VERSION ""

NS_ :

BS_:

BU_: WPC2 RLPSU DPSU APSU PSB SHVU_RR vHS_B2 FCS EMCU SLB ARS RCM CGW_CCU vDummy_HS_B ATS RLHV SGU PFSU ALBCU DSAU SWRC SHVU_FR RCS RRPSU BLTN_CAM SCM DLBCU OHCL RWPC RRHV WPC HOD ASAU

BO_ 2244048387 RCU_03_20ms_3: 8 CGW_CCU
 SG_ RCU_AD3_SCC_TqIntrvntnVal : 0|8@1+ (0.390625,0) [0|0] "%" Vector__XXX
 SG_ RCU_AD3_TCS_TqFlag : 19|1@1+ (1,0) [0|0] "" Vector__XXX
 SG_ RCU_AD3_TCS_Sta : 20|4@1+ (1,0) [0|0] "" Vector__XXX
 SG_ RCU_AD3_VehAccelVal : 24|11@1+ (0.01,-10.23) [0|0] "m/s^2" Vector__XXX
 SG_ RCU_AD3_MSR_TqFlag : 35|1@1+ (1,0) [0|0] "" Vector__XXX
 SG_ RCU_AD3_LDM_Sta : 36|2@1+ (1,0) [0|0] "" Vector__XXX
 SG_ RCU_AD3_ECD_ActvSta : 38|2@1+ (1,0) [0|0] "" Vector__XXX
 SG_ RCU_AD3_MSR_FuncReq : 40|2@1+ (1,0) [0|0] "" Vector__XXX
 SG_ RCU_AD3_TCS_Req : 42|2@1+ (1,0) [0|0] "" Vector__XXX
 SG_ RCU_AD3_TCS_LmpSta : 44|2@1+ (1,0) [0|0] "" Vector__XXX
 SG_ RCU_AD3_SCC_TqReq : 46|2@1+ (1,0) [0|0] "" Vector__XXX
 SG_ RCU_AD3_StdStillVal : 48|2@1+ (1,0) [0|0] "" Vector__XXX
 SG_ RCU_AD3_SCC_ReqLimSta : 50|2@1+ (1,0) [0|0] "" Vector__XXX
 SG_ RCU_AD3_SCC_OptTyp : 52|2@1+ (1,0) [0|0] "" Vector__XXX
 SG_ RCU_AD3_SCC_EnblReq : 54|2@1+ (1,0) [0|0] "" Vector__XXX
 SG_ RCU_AD3_FCA_EquipSta : 56|2@1+ (1,0) [0|0] "" Vector__XXX
 SG_ RCU_AD3_FCA_ActvSta : 58|2@1+ (1,0) [0|0] "" Vector__XXX
 SG_ RCU_AD3_DclEnblReq : 60|2@1+ (1,0) [0|0] "" Vector__XXX
 SG_ RCU_AD3_DBS_ActvSta : 62|2@1+ (1,0) [0|0] "" Vector__XXX
 SG_ RCU_AD3_AccelBasisVal : 8|11@1+ (0.01,-10.23) [0|0] "m/s^2" Vector__XXX

BO_ 2244048386 RCU_03_20ms_2: 8 CGW_CCU
 SG_ RCU_AD3_Wss2FlFltSta : 0|2@1+ (1,0) [0|0] "" Vector__XXX
 SG_ RCU_AD3_DiagSta : 10|2@1+ (1,0) [0|0] "" Vector__XXX
 SG_ RCU_AD3_operation : 12|2@1+ (1,0) [0|0] "" Vector__XXX
 SG_ RCU_AD3_PrsrValVldSta : 14|2@1+ (1,0) [0|0] "" Vector__XXX
 SG_ RCU_AD3_PrsrVal : 16|16@1- (0.01,-30) [0|0] "Bar" Vector__XXX
 SG_ RCU_AD3_Wss2FrFltSta : 2|2@1+ (1,0) [0|0] "" Vector__XXX
 SG_ RCU_AD3_ABS_DfctvSta : 32|2@1+ (1,0) [0|0] "" Vector__XXX
 SG_ RCU_AD3_ABS_ActvSta : 34|2@1+ (1,0) [0|0] "" Vector__XXX
 SG_ RCU_AD3_BBC_DfctvSta : 36|2@1+ (1,0) [0|0] "" Vector__XXX
 SG_ RCU_AD3_BBC_ActvSta : 38|2@1+ (1,0) [0|0] "" Vector__XXX
 SG_ RCU_AD3_Wss2RlFltSta : 4|2@1+ (1,0) [0|0] "" Vector__XXX
 SG_ RCU_AD3_BrkLtActSta : 40|2@1+ (1,0) [0|0] "" Vector__XXX
 SG_ RCU_AD3_DrvOvrdSta : 42|2@1+ (1,0) [0|0] "" Vector__XXX
 SG_ RCU_AD3_PrkBrkActvSta : 44|2@1+ (1,0) [0|0] "" Vector__XXX
 SG_ RCU_AD3_FCA_AvlblSta : 46|2@1+ (1,0) [0|0] "" Vector__XXX
 SG_ RCU_AD3_MSR_TqIntrvntnVal : 48|8@1+ (0.390625,0) [0|0] "%" Vector__XXX
 SG_ RCU_AD3_TCS_TqIntrvntnVal : 56|8@1+ (0.390625,0) [0|0] "%" Vector__XXX
 SG_ RCU_AD3_Wss2RrFltSta : 6|2@1+ (1,0) [0|0] "" Vector__XXX
 SG_ RCU_AD3_SrvLmpDis : 8|2@1+ (1,0) [0|0] "" Vector__XXX

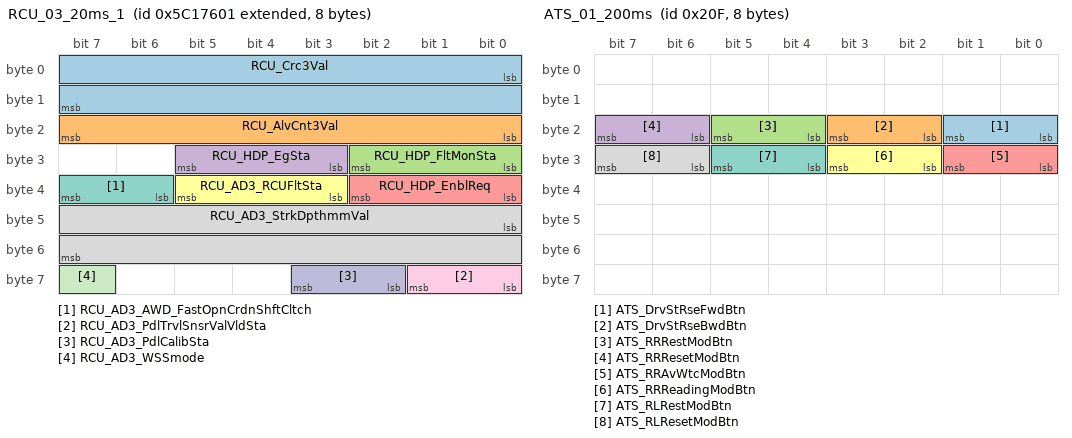
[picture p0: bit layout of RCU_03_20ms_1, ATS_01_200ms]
BO_ 2244048385 RCU_03_20ms_1: 8 CGW_CCU
 SG_ RCU_Crc3Val : 0|16@1+ (1,0) [0|0] "" Vector__XXX
 SG_ RCU_AlvCnt3Val : 16|8@1+ (1,0) [0|0] "" Vector__XXX
 SG_ RCU_HDP_FltMonSta : 24|3@1+ (1,0) [0|0] "" Vector__XXX
 SG_ RCU_HDP_EgSta : 27|3@1+ (1,0) [0|0] ""  PSB
 SG_ RCU_HDP_EnblReq : 32|3@1+ (1,0) [0|0] "" Vector__XXX
 SG_ RCU_AD3_RCUFltSta : 35|3@1+ (1,0) [0|0] "" Vector__XXX
 SG_ RCU_AD3_AWD_FastOpnCrdnShftCltch : 38|2@1+ (1,0) [0|0] "" Vector__XXX
 SG_ RCU_AD3_StrkDpthmmVal : 40|16@1- (0.1,-40) [0|0] "mm" Vector__XXX
 SG_ RCU_AD3_PdlTrvlSnsrValVldSta : 56|2@1+ (1,0) [0|0] "" Vector__XXX
 SG_ RCU_AD3_PdlCalibSta : 58|2@1+ (1,0) [0|0] "" Vector__XXX
 SG_ RCU_AD3_WSSmode : 63|1@1+ (1,0) [0|0] "" Vector__XXX

BO_ 527 ATS_01_200ms: 8 ATS
 SG_ ATS_DrvStRseFwdBtn : 16|2@1+ (1,0) [0|0] "" Vector__XXX
 SG_ ATS_DrvStRseBwdBtn : 18|2@1+ (1,0) [0|0] "" Vector__XXX
 SG_ ATS_RRRestModBtn : 20|2@1+ (1,0) [0|0] "" Vector__XXX
 SG_ ATS_RRResetModBtn : 22|2@1+ (1,0) [0|0] "" Vector__XXX
 SG_ ATS_RRAvWtcModBtn : 24|2@1+ (1,0) [0|0] "" Vector__XXX
 SG_ ATS_RRReadingModBtn : 26|2@1+ (1,0) [0|0] "" Vector__XXX
 SG_ ATS_RLRestModBtn : 28|2@1+ (1,0) [0|0] "" Vector__XXX
 SG_ ATS_RLResetModBtn : 30|2@1+ (1,0) [0|0] "" Vector__XXX

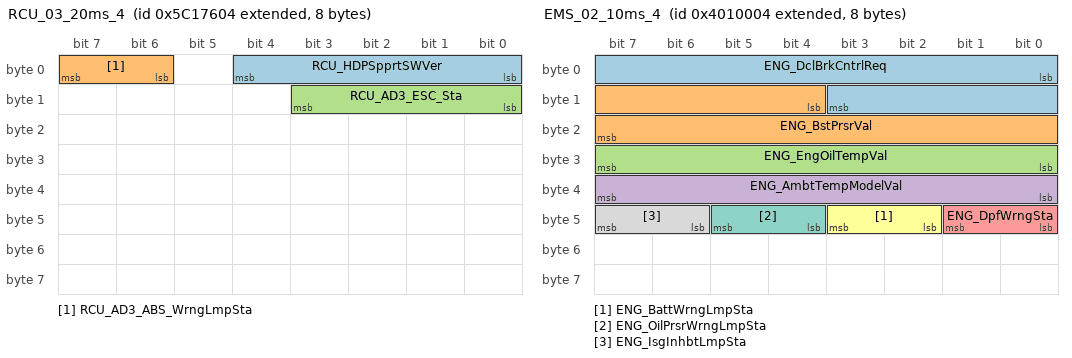
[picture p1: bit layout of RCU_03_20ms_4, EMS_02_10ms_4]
BO_ 2244048388 RCU_03_20ms_4: 8 CGW_CCU
 SG_ RCU_HDPSpprtSWVer : 0|5@1+ (1,0) [0|0] "" Vector__XXX
 SG_ RCU_AD3_ABS_WrngLmpSta : 6|2@1+ (1,0) [0|0] "" Vector__XXX
 SG_ RCU_AD3_ESC_Sta : 8|4@1+ (1,0) [0|0] "" Vector__XXX

BO_ 1616 MKBD_HU_E_01: 8 CGW_CCU
 SG_ MKBD_IllumiState : 48|2@1+ (1,0) [0|0] "" Vector__XXX
 SG_ MKBD_SeatKeySet : 50|2@1+ (1,0) [0|0] ""  APSU,SHVU_FR,DPSU

BO_ 543 ATS_02_200ms: 8 ATS
 SG_ ATS_AstStSldFwdBtn : 16|2@1+ (1,0) [0|0] "" Vector__XXX
 SG_ ATS_AstStSldBwdBtn : 18|2@1+ (1,0) [0|0] "" Vector__XXX
 SG_ ATS_AstStRclFwdBtn : 20|2@1+ (1,0) [0|0] "" Vector__XXX
 SG_ ATS_AstStRclBwdBtn : 22|2@1+ (1,0) [0|0] "" Vector__XXX
 SG_ ATS_AstStHgtUpBtn : 28|2@1+ (1,0) [0|0] "" Vector__XXX
 SG_ ATS_AstStHgtDnBtn : 30|2@1+ (1,0) [0|0] "" Vector__XXX
 SG_ ATS_AstStHRestUpBtn : 40|2@1+ (1,0) [0|0] "" Vector__XXX
 SG_ ATS_AstStHRestDnBtn : 42|2@1+ (1,0) [0|0] "" Vector__XXX
 SG_ ATS_AstStHRestFwdBtn : 44|2@1+ (1,0) [0|0] "" Vector__XXX
 SG_ ATS_AstStHRestBwdBtn : 46|2@1+ (1,0) [0|0] "" Vector__XXX
 SG_ ATS_AstStHRestFldBtn : 48|2@1+ (1,0) [0|0] "" Vector__XXX
 SG_ ATS_AstStHRestUnFldBtn : 50|2@1+ (1,0) [0|0] "" Vector__XXX
 SG_ ATS_AstStRseFwdBtn : 52|2@1+ (1,0) [0|0] "" Vector__XXX
 SG_ ATS_AstStRseBwdBtn : 54|2@1+ (1,0) [0|0] "" Vector__XXX
 SG_ ATS_AstStFRestFldBtn : 56|2@1+ (1,0) [0|0] "" Vector__XXX
 SG_ ATS_AstStFRestUnFldBtn : 58|2@1+ (1,0) [0|0] "" Vector__XXX
 SG_ ATS_AstTltUpBtn : 60|2@1+ (1,0) [0|0] "" Vector__XXX
 SG_ ATS_AstTltDnBtn : 62|2@1+ (1,0) [0|0] "" Vector__XXX

BO_ 2214658052 EMS_02_10ms_4: 8 CGW_CCU
 SG_ ENG_DclBrkCntrlReq : 0|12@1+ (0.001,-4.094) [0|0] "m/s^2" Vector__XXX
 SG_ ENG_BstPrsrVal : 12|12@1+ (1.322,0) [0|0] "hPa" Vector__XXX
 SG_ ENG_EngOilTempVal : 24|8@1+ (0.75,-40) [0|0] "¡É" Vector__XXX
 SG_ ENG_AmbtTempModelVal : 32|8@1+ (0.5,-41) [0|0] "¡É" Vector__XXX
 SG_ ENG_DpfWrngSta : 40|2@1+ (1,0) [0|0] "" Vector__XXX
 SG_ ENG_BattWrngLmpSta : 42|2@1+ (1,0) [0|0] "" Vector__XXX
 SG_ ENG_OilPrsrWrngLmpSta : 44|2@1+ (1,0) [0|0] "" Vector__XXX
 SG_ ENG_IsgInhbtLmpSta : 46|2@1+ (1,0) [0|0] ""  FCS

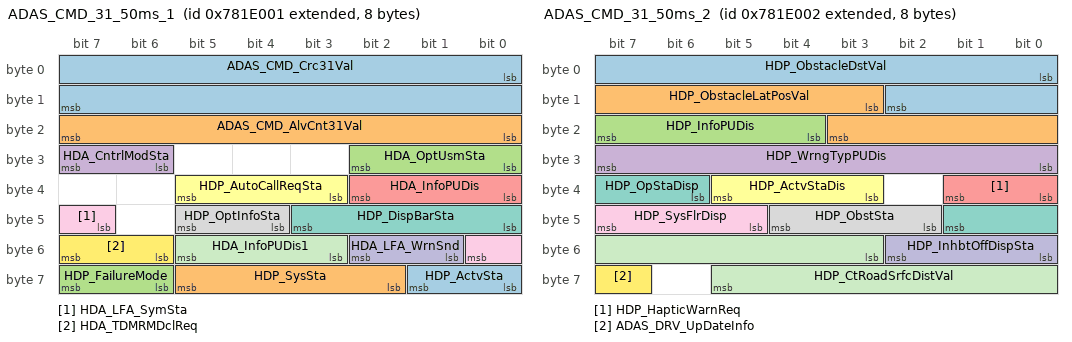
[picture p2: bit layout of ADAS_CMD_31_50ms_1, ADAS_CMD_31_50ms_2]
BO_ 2273435649 ADAS_CMD_31_50ms_1: 8 CGW_CCU
 SG_ ADAS_CMD_Crc31Val : 0|16@1+ (1,0) [0|0] "" Vector__XXX
 SG_ ADAS_CMD_AlvCnt31Val : 16|8@1+ (1,0) [0|0] "" Vector__XXX
 SG_ HDA_OptUsmSta : 24|3@1+ (1,0) [0|0] "" Vector__XXX
 SG_ HDA_CntrlModSta : 30|2@1+ (1,0) [0|0] "" Vector__XXX
 SG_ HDA_InfoPUDis : 32|3@1+ (1,0) [0|0] "" Vector__XXX
 SG_ HDP_AutoCallReqSta : 35|3@1+ (1,0) [0|0] "" Vector__XXX
 SG_ HDP_DispBarSta : 40|4@1+ (1,0) [0|0] "" Vector__XXX
 SG_ HDP_OptInfoSta : 44|2@1+ (1,0) [0|0] "" Vector__XXX
 SG_ HDA_LFA_SymSta : 47|2@1+ (1,0) [0|0] "" Vector__XXX
 SG_ HDA_LFA_WrnSnd : 49|2@1+ (1,0) [0|0] "" Vector__XXX
 SG_ HDA_InfoPUDis1 : 51|3@1+ (1,0) [0|0] "" Vector__XXX
 SG_ HDA_TDMRMDclReq : 54|2@1+ (1,0) [0|0] "" Vector__XXX
 SG_ HDP_ActvSta : 56|2@1+ (1,0) [0|0] "" Vector__XXX
 SG_ HDP_SysSta : 58|4@1+ (1,0) [0|0] ""  HOD
 SG_ HDP_FailureMode : 62|2@1+ (1,0) [0|0] "" Vector__XXX

BO_ 2273435650 ADAS_CMD_31_50ms_2: 8 CGW_CCU
 SG_ HDP_ObstacleDstVal : 0|11@1+ (0.1,0) [0|0] "m" Vector__XXX
 SG_ HDP_ObstacleLatPosVal : 11|9@1+ (0.1,-20) [0|0] "m" Vector__XXX
 SG_ HDP_InfoPUDis : 20|4@1+ (1,0) [0|0] "" Vector__XXX
 SG_ HDP_WrngTypPUDis : 24|8@1+ (1,0) [0|0] "" Vector__XXX
 SG_ HDP_HapticWarnReq : 32|2@1+ (1,0) [0|0] ""  PSB
 SG_ HDP_ActvStaDis : 35|3@1+ (1,0) [0|0] "" Vector__XXX
 SG_ HDP_OpStaDisp : 38|4@1+ (1,0) [0|0] "" Vector__XXX
 SG_ HDP_ObstSta : 42|3@1+ (1,0) [0|0] "" Vector__XXX
 SG_ HDP_SysFlrDisp : 45|3@1+ (1,0) [0|0] "" Vector__XXX
 SG_ HDP_InhbtOffDispSta : 48|3@1+ (1,0) [0|0] "" Vector__XXX
 SG_ HDP_CtRoadSrfcDistVal : 51|11@1+ (1,0) [0|0] "" Vector__XXX
 SG_ ADAS_DRV_UpDateInfo : 63|1@1+ (1,0) [0|0] "" Vector__XXX

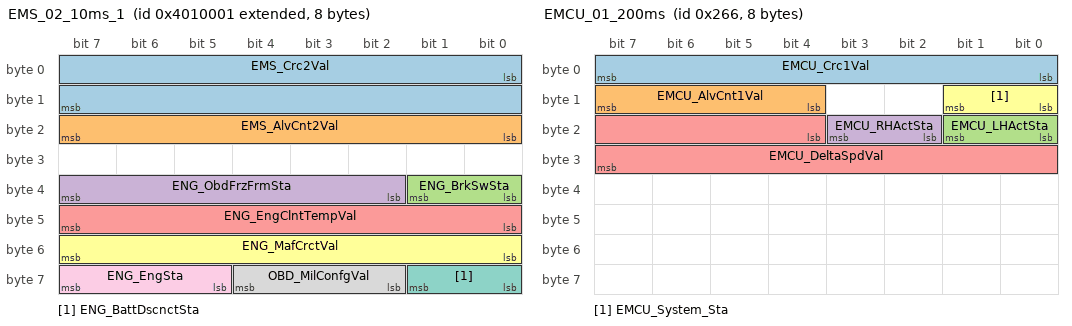
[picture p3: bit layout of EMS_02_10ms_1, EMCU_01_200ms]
BO_ 2214658049 EMS_02_10ms_1: 8 CGW_CCU
 SG_ EMS_Crc2Val : 0|16@1+ (1,0) [0|0] "" Vector__XXX
 SG_ EMS_AlvCnt2Val : 16|8@1+ (1,0) [0|0] "" Vector__XXX
 SG_ ENG_BrkSwSta : 32|2@1+ (1,0) [0|0] ""  BLTN_CAM
 SG_ ENG_ObdFrzFrmSta : 34|6@1+ (1,0) [0|0] "" Vector__XXX
 SG_ ENG_EngClntTempVal : 40|8@1+ (0.75,-48) [0|0] "¡É" Vector__XXX
 SG_ ENG_MafCrctVal : 48|8@1+ (0.00781,0) [0|0] "" Vector__XXX
 SG_ ENG_BattDscnctSta : 56|2@1+ (1,0) [0|0] "" Vector__XXX
 SG_ OBD_MilConfgVal : 58|3@1+ (1,0) [0|0] "" Vector__XXX
 SG_ ENG_EngSta : 61|3@1+ (1,0) [0|0] ""  SCM,WPC,RWPC,SWRC,APSU,RLHV,RRHV,SHVU_FR,SHVU_RR,DPSU,DLBCU,PFSU,RRPSU,RLPSU,HOD,RCM,BLTN_CAM,EMCU,WPC2

BO_ 614 EMCU_01_200ms: 8 EMCU
 SG_ EMCU_Crc1Val : 0|8@1+ (1,0) [0|0] "" Vector__XXX
 SG_ EMCU_AlvCnt1Val : 12|4@1+ (1,0) [0|0] "" Vector__XXX
 SG_ EMCU_LHActSta : 16|2@1+ (1,0) [0|0] "" Vector__XXX
 SG_ EMCU_RHActSta : 18|2@1+ (1,0) [0|0] "" Vector__XXX
 SG_ EMCU_DeltaSpdVal : 20|12@1+ (0.01,0) [0|0] "" Vector__XXX
 SG_ EMCU_System_Sta : 8|2@1+ (1,0) [0|0] "" Vector__XXX

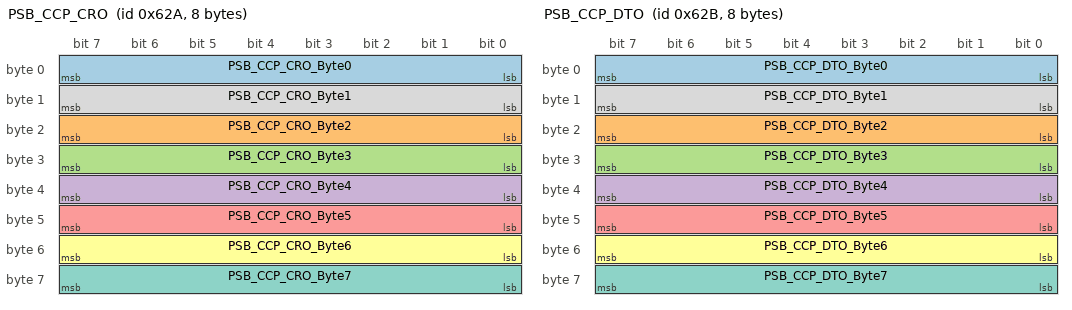
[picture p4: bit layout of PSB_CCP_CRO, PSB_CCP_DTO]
BO_ 1578 PSB_CCP_CRO: 8 CGW_CCU
 SG_ PSB_CCP_CRO_Byte0 : 0|8@1+ (1,0) [0|0] ""  PSB
 SG_ PSB_CCP_CRO_Byte2 : 16|8@1+ (1,0) [0|0] ""  PSB
 SG_ PSB_CCP_CRO_Byte3 : 24|8@1+ (1,0) [0|0] ""  PSB
 SG_ PSB_CCP_CRO_Byte4 : 32|8@1+ (1,0) [0|0] ""  PSB
 SG_ PSB_CCP_CRO_Byte5 : 40|8@1+ (1,0) [0|0] ""  PSB
 SG_ PSB_CCP_CRO_Byte6 : 48|8@1+ (1,0) [0|0] ""  PSB
 SG_ PSB_CCP_CRO_Byte7 : 56|8@1+ (1,0) [0|0] ""  PSB
 SG_ PSB_CCP_CRO_Byte1 : 8|8@1+ (1,0) [0|0] ""  PSB

BO_ 1579 PSB_CCP_DTO: 8 PSB
 SG_ PSB_CCP_DTO_Byte0 : 0|8@1+ (1,0) [0|0] ""  CGW_CCU
 SG_ PSB_CCP_DTO_Byte2 : 16|8@1+ (1,0) [0|0] ""  CGW_CCU
 SG_ PSB_CCP_DTO_Byte3 : 24|8@1+ (1,0) [0|0] ""  CGW_CCU
 SG_ PSB_CCP_DTO_Byte4 : 32|8@1+ (1,0) [0|0] ""  CGW_CCU
 SG_ PSB_CCP_DTO_Byte5 : 40|8@1+ (1,0) [0|0] ""  CGW_CCU
 SG_ PSB_CCP_DTO_Byte6 : 48|8@1+ (1,0) [0|0] ""  CGW_CCU
 SG_ PSB_CCP_DTO_Byte7 : 56|8@1+ (1,0) [0|0] ""  CGW_CCU
 SG_ PSB_CCP_DTO_Byte1 : 8|8@1+ (1,0) [0|0] ""  CGW_CCU

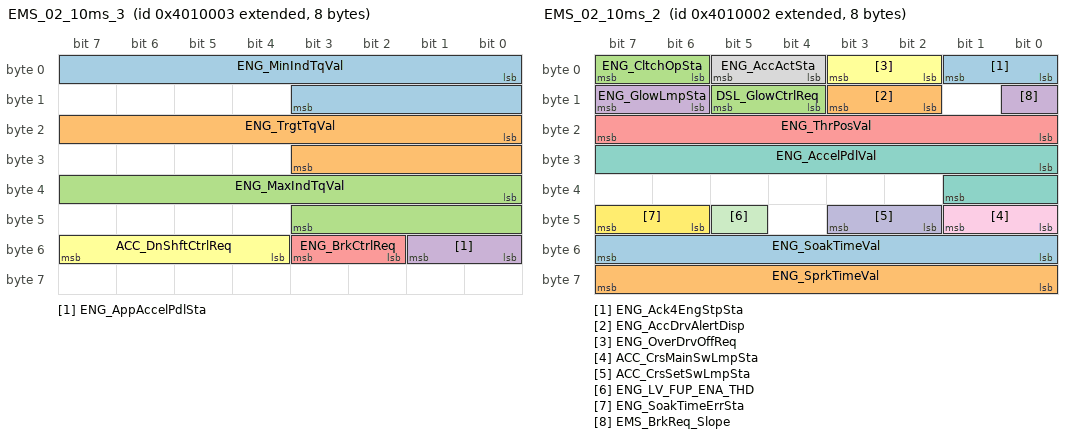
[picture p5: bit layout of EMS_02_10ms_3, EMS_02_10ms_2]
BO_ 2214658051 EMS_02_10ms_3: 8 CGW_CCU
 SG_ ENG_MinIndTqVal : 0|12@1- (1,0) [0|0] "Nm" Vector__XXX
 SG_ ENG_TrgtTqVal : 16|12@1- (1,0) [0|0] "Nm" Vector__XXX
 SG_ ENG_MaxIndTqVal : 32|12@1- (1,0) [0|0] "Nm" Vector__XXX
 SG_ ENG_AppAccelPdlSta : 48|2@1+ (1,0) [0|0] "" Vector__XXX
 SG_ ENG_BrkCtrlReq : 50|2@1+ (1,0) [0|0] "" Vector__XXX
 SG_ ACC_DnShftCtrlReq : 52|4@1+ (1,0) [0|0] "" Vector__XXX

BO_ 2214658050 EMS_02_10ms_2: 8 CGW_CCU
 SG_ ENG_Ack4EngStpSta : 0|2@1+ (1,0) [0|0] "" Vector__XXX
 SG_ ENG_AccDrvAlertDisp : 10|2@1+ (1,0) [0|0] "" Vector__XXX
 SG_ DSL_GlowCtrlReq : 12|2@1+ (1,0) [0|0] "" Vector__XXX
 SG_ ENG_GlowLmpSta : 14|2@1+ (1,0) [0|0] "" Vector__XXX
 SG_ ENG_ThrPosVal : 16|8@1+ (0.4694836,-15.0234742) [0|0] "%" Vector__XXX
 SG_ ENG_OverDrvOffReq : 2|2@1+ (1,0) [0|0] "" Vector__XXX
 SG_ ENG_AccelPdlVal : 24|10@1+ (0.09784,0) [0|0] "%"  BLTN_CAM,EMCU
 SG_ ENG_AccActSta : 4|2@1+ (1,0) [0|0] "" Vector__XXX
 SG_ ACC_CrsMainSwLmpSta : 40|2@1+ (1,0) [0|0] "" Vector__XXX
 SG_ ACC_CrsSetSwLmpSta : 42|2@1+ (1,0) [0|0] "" Vector__XXX
 SG_ ENG_LV_FUP_ENA_THD : 45|1@1+ (1,0) [0|0] "" Vector__XXX
 SG_ ENG_SoakTimeErrSta : 46|2@1+ (1,0) [0|0] "" Vector__XXX
 SG_ ENG_SoakTimeVal : 48|8@1+ (1,0) [0|0] "Min" Vector__XXX
 SG_ ENG_SprkTimeVal : 56|8@1+ (0.375,-35.625) [0|0] "¢ª" Vector__XXX
 SG_ ENG_CltchOpSta : 6|2@1+ (1,0) [0|0] "" Vector__XXX
 SG_ EMS_BrkReq_Slope : 8|1@1+ (1,0) [0|0] "" Vector__XXX

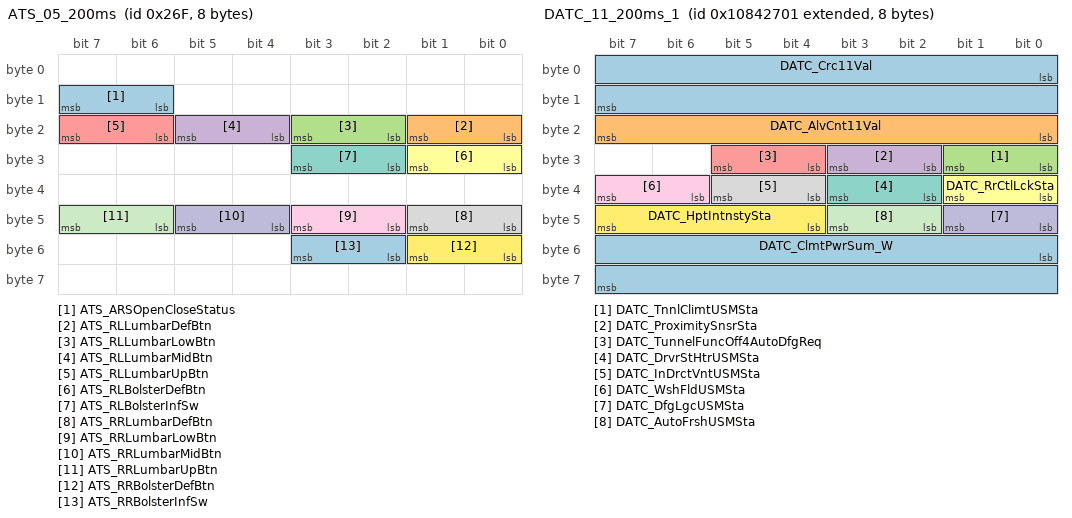
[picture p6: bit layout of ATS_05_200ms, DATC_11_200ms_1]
BO_ 623 ATS_05_200ms: 8 ATS
 SG_ ATS_ARSOpenCloseStatus : 14|2@1+ (1,0) [0|0] "" Vector__XXX
 SG_ ATS_RLLumbarDefBtn : 16|2@1+ (1,0) [0|0] "" Vector__XXX
 SG_ ATS_RLLumbarLowBtn : 18|2@1+ (1,0) [0|0] "" Vector__XXX
 SG_ ATS_RLLumbarMidBtn : 20|2@1+ (1,0) [0|0] "" Vector__XXX
 SG_ ATS_RLLumbarUpBtn : 22|2@1+ (1,0) [0|0] "" Vector__XXX
 SG_ ATS_RLBolsterDefBtn : 24|2@1+ (1,0) [0|0] "" Vector__XXX
 SG_ ATS_RLBolsterInfSw : 26|2@1+ (1,0) [0|0] "" Vector__XXX
 SG_ ATS_RRLumbarDefBtn : 40|2@1+ (1,0) [0|0] "" Vector__XXX
 SG_ ATS_RRLumbarLowBtn : 42|2@1+ (1,0) [0|0] "" Vector__XXX
 SG_ ATS_RRLumbarMidBtn : 44|2@1+ (1,0) [0|0] "" Vector__XXX
 SG_ ATS_RRLumbarUpBtn : 46|2@1+ (1,0) [0|0] "" Vector__XXX
 SG_ ATS_RRBolsterDefBtn : 48|2@1+ (1,0) [0|0] "" Vector__XXX
 SG_ ATS_RRBolsterInfSw : 50|2@1+ (1,0) [0|0] "" Vector__XXX

BO_ 639 ATS_04_00ms: 8 ATS
 SG_ ATS_RRSeatHeaterSW : 0|2@1+ (1,0) [0|0] ""  RRHV,SHVU_RR
 SG_ ATS_RLSeatHeaterUpSW : 10|2@1+ (1,0) [0|0] ""  RLHV,SHVU_RR
 SG_ ATS_RRSeatVentDownSW : 12|2@1+ (1,0) [0|0] ""  RRHV,SHVU_RR
 SG_ ATS_RLSeatVentDownSW : 14|2@1+ (1,0) [0|0] ""  RLHV,SHVU_RR
 SG_ ATS_RLMemoryRestBtn : 16|2@1+ (1,0) [0|0] "" Vector__XXX
 SG_ ATS_RLMemoryReturnBtn : 18|2@1+ (1,0) [0|0] "" Vector__XXX
 SG_ ATS_RLSeatHeaterSW : 2|2@1+ (1,0) [0|0] ""  RLHV,SHVU_RR
 SG_ ATS_RRMemoryRestBtn : 20|2@1+ (1,0) [0|0] "" Vector__XXX
 SG_ ATS_RRMemoryReturnBtn : 22|2@1+ (1,0) [0|0] "" Vector__XXX
 SG_ ATS_RRMemoryAvWtcBtn : 24|2@1+ (1,0) [0|0] "" Vector__XXX
 SG_ ATS_RRMemoryReadingBtn : 26|2@1+ (1,0) [0|0] "" Vector__XXX
 SG_ ATS_RRRestModBtnSTD : 32|2@1+ (1,0) [0|0] "" Vector__XXX
 SG_ ATS_RRResetModBtnSTD : 34|2@1+ (1,0) [0|0] "" Vector__XXX
 SG_ ATS_RRAvWtcModBtnSTD : 36|2@1+ (1,0) [0|0] "" Vector__XXX
 SG_ ATS_RRReadingModBtnSTD : 38|2@1+ (1,0) [0|0] "" Vector__XXX
 SG_ ATS_RRSeatVentSW : 4|2@1+ (1,0) [0|0] ""  RRHV,SHVU_RR
 SG_ ATS_RLRestModBtnSTD : 40|2@1+ (1,0) [0|0] "" Vector__XXX
 SG_ ATS_RLResetModBtnSTD : 42|2@1+ (1,0) [0|0] "" Vector__XXX
 SG_ ATS_RRModestateStopBtn : 44|2@1+ (1,0) [0|0] "" Vector__XXX
 SG_ ATS_RLModestateStopBtn : 46|2@1+ (1,0) [0|0] "" Vector__XXX
 SG_ ATS_RLResetRestBtn : 48|2@1+ (1,0) [0|0] "" Vector__XXX
 SG_ ATS_RLResetReturnBtn : 50|2@1+ (1,0) [0|0] "" Vector__XXX
 SG_ ATS_RRResetRestBtn : 52|2@1+ (1,0) [0|0] "" Vector__XXX
 SG_ ATS_RRResetReturnBtn : 54|2@1+ (1,0) [0|0] "" Vector__XXX
 SG_ ATS_RRResetAvWtcBtn : 56|2@1+ (1,0) [0|0] "" Vector__XXX
 SG_ ATS_RRResetReadingBtn : 58|2@1+ (1,0) [0|0] "" Vector__XXX
 SG_ ATS_RLSeatVentSW : 6|2@1+ (1,0) [0|0] ""  RLHV,SHVU_RR
 SG_ ATS_RRSeatHeaterUpSW : 8|2@1+ (1,0) [0|0] ""  RRHV,SHVU_RR

BO_ 1584 HU_AMP_E_01: 8 CGW_CCU
 SG_ AMP_NaviWarnSound : 0|2@1+ (1,0) [0|0] "" Vector__XXX
 SG_ AMP_Beep1Mode : 14|2@1+ (1,0) [0|0] ""  ATS
 SG_ AMP_MasterBeepVolumeStep : 16|3@1+ (1,0) [0|0] "" Vector__XXX
 SG_ AMP_RrTTSSound : 2|2@1+ (1,0) [0|0] "" Vector__XXX
 SG_ AMP_ASDMode : 21|3@1+ (1,0) [0|0] "" Vector__XXX
 SG_ AMP_ANCMode : 25|2@1+ (1,0) [0|0] "" Vector__XXX
 SG_ AMP_VirtualVenueMode : 32|3@1+ (1,0) [0|0] "" Vector__XXX
 SG_ AMP_QLIMode : 35|3@1+ (1,0) [0|0] "" Vector__XXX
 SG_ AMP_DriverMode : 38|2@1+ (1,0) [0|0] "" Vector__XXX
 SG_ AMP_NaviSound : 4|2@1+ (1,0) [0|0] "" Vector__XXX
 SG_ AMP_ETCSSound : 42|2@1+ (1,0) [0|0] "" Vector__XXX
 SG_ AMP_VoiceGuideTTS : 44|2@1+ (1,0) [0|0] "" Vector__XXX
 SG_ AMP_Beep1KBDMode : 46|2@1+ (1,0) [0|0] "" Vector__XXX
 SG_ AMP_ETCSVolumeStep : 48|8@1+ (1,0) [0|0] "" Vector__XXX
 SG_ AMP_NaviWarnVolumeStep : 56|8@1+ (1,0) [0|0] "" Vector__XXX
 SG_ AMP_TTSSound : 6|2@1+ (1,0) [0|0] "" Vector__XXX
 SG_ AMP_SDVCStep : 9|3@1+ (1,0) [0|0] "" Vector__XXX

BO_ 577 HU_APSU_PE_02: 8 CGW_CCU
 SG_ C_AstBolsterInfSw_HU : 0|2@1+ (1,0) [0|0] ""  ASAU,ALBCU
 SG_ C_RLHrestUpSw_HU : 14|2@1+ (1,0) [0|0] ""  APSU,RLPSU
 SG_ C_RLHrestDnSw_HU : 16|2@1+ (1,0) [0|0] ""  APSU,RLPSU
 SG_ C_RLHrestFwdSw_HU : 18|2@1+ (1,0) [0|0] ""  APSU,RLPSU
 SG_ C_AstBolsterDefSw_HU : 2|2@1+ (1,0) [0|0] ""  ASAU,ALBCU
 SG_ C_RLHrestBwdSw_HU : 20|2@1+ (1,0) [0|0] ""  APSU,RLPSU
 SG_ C_RLLumbarUpSw_HU : 22|2@1+ (1,0) [0|0] ""  RLPSU
 SG_ C_RLLumbarMidSw_HU : 24|2@1+ (1,0) [0|0] ""  RLPSU
 SG_ C_RLLumbarLowSw_HU : 26|2@1+ (1,0) [0|0] ""  RLPSU
 SG_ C_RLLumbarDefSw_HU : 28|2@1+ (1,0) [0|0] ""  RLPSU
 SG_ C_RLBolsterInfSw_HU : 30|2@1+ (1,0) [0|0] ""  RLPSU
 SG_ C_RLBolsterDefSw_HU : 32|2@1+ (1,0) [0|0] ""  RLPSU
 SG_ C_AstHrestUpSw_HU : 36|2@1+ (1,0) [0|0] ""  APSU
 SG_ C_AstHrestDnSw_HU : 38|2@1+ (1,0) [0|0] ""  APSU
 SG_ C_AstFootrestFldSw_HU : 4|2@1+ (1,0) [0|0] ""  APSU
 SG_ C_AstHrestFwdSw_HU : 46|2@1+ (1,0) [0|0] ""  APSU
 SG_ C_AstHrestBwdSw_HU : 54|2@1+ (1,0) [0|0] ""  APSU
 SG_ C_AstFootrestUnFldSw_HU : 6|2@1+ (1,0) [0|0] ""  APSU

BO_ 578 HU_APSU_PE_03: 8 CGW_CCU
 SG_ C_RRLegSupFwdSw_HU : 0|2@1+ (1,0) [0|0] ""  APSU,RRPSU
 SG_ C_RRHrestDnSw_HU : 10|2@1+ (1,0) [0|0] ""  APSU,RRPSU
 SG_ C_RRHrestFwdSw_HU : 12|2@1+ (1,0) [0|0] ""  APSU,RRPSU
 SG_ C_RRHrestBwdSw_HU : 14|2@1+ (1,0) [0|0] ""  APSU,RRPSU
 SG_ C_RRLumbarUpSw_HU : 16|2@1+ (1,0) [0|0] ""  APSU,RRPSU
 SG_ C_RRLumbarMidSw_HU : 18|2@1+ (1,0) [0|0] ""  APSU,RRPSU
 SG_ C_RRLegSupBwdSw_HU : 2|2@1+ (1,0) [0|0] ""  APSU,RRPSU
 SG_ C_RRLumbarLowSw_HU : 20|2@1+ (1,0) [0|0] ""  APSU,RRPSU
 SG_ C_RRLumbarDefSw_HU : 22|2@1+ (1,0) [0|0] ""  APSU,RRPSU
 SG_ C_RRBolsterInfSw_HU : 24|2@1+ (1,0) [0|0] ""  APSU,RRPSU
 SG_ C_RRLegSupUpSw_HU : 4|2@1+ (1,0) [0|0] ""  APSU,RRPSU
 SG_ C_RROneTchNValueSet : 40|3@1+ (1,0) [0|0] ""  APSU,RRPSU,ATS
 SG_ C_RLOneTchNValueSet : 43|3@1+ (1,0) [0|0] ""  APSU,RRPSU,RLPSU,ATS
 SG_ C_RRBolsterDefSw_HU : 46|2@1+ (1,0) [0|0] ""  APSU,RRPSU
 SG_ C_AstRlxTiltUpSw_HU : 50|2@1+ (1,0) [0|0] ""  APSU
 SG_ C_AstRlxTiltDnSw_HU : 52|2@1+ (1,0) [0|0] ""  APSU
 SG_ C_RLRSEUpSw_HU : 54|2@1+ (1,0) [0|0] ""  APSU,RLPSU
 SG_ C_RLRSEDnSw_HU : 56|2@1+ (1,0) [0|0] ""  APSU,RLPSU
 SG_ C_RRRSEUpSw_HU : 58|2@1+ (1,0) [0|0] ""  APSU,RRPSU
 SG_ C_RRLegSupDnSw_HU : 6|2@1+ (1,0) [0|0] ""  APSU,RRPSU
 SG_ C_RRRSEDnSw_HU : 60|2@1+ (1,0) [0|0] ""  APSU,RRPSU
 SG_ C_RRHrestUpSw_HU : 8|2@1+ (1,0) [0|0] ""  APSU,RRPSU

BO_ 2424579841 DATC_11_200ms_1: 8 CGW_CCU
 SG_ DATC_Crc11Val : 0|16@1+ (1,0) [0|0] "" Vector__XXX
 SG_ DATC_AlvCnt11Val : 16|8@1+ (1,0) [0|0] "" Vector__XXX
 SG_ DATC_TnnlClimtUSMSta : 24|2@1+ (1,0) [0|0] "" Vector__XXX
 SG_ DATC_ProximitySnsrSta : 26|2@1+ (1,0) [0|0] "" Vector__XXX
 SG_ DATC_TunnelFuncOff4AutoDfgReq : 28|2@1+ (1,0) [0|0] "" Vector__XXX
 SG_ DATC_RrCtlLckSta : 32|2@1+ (1,0) [0|0] ""  ATS
 SG_ DATC_DrvrStHtrUSMSta : 34|2@1+ (1,0) [0|0] ""  APSU,DPSU
 SG_ DATC_InDrctVntUSMSta : 36|2@1+ (1,0) [0|0] "" Vector__XXX
 SG_ DATC_WshFldUSMSta : 38|2@1+ (1,0) [0|0] "" Vector__XXX
 SG_ DATC_DfgLgcUSMSta : 40|2@1+ (1,0) [0|0] "" Vector__XXX
 SG_ DATC_AutoFrshUSMSta : 42|2@1+ (1,0) [0|0] "" Vector__XXX
 SG_ DATC_HptIntnstySta : 44|4@1+ (1,0) [0|0] "" Vector__XXX
 SG_ DATC_ClmtPwrSum_W : 48|16@1+ (1,0) [0|0] "Wh" Vector__XXX

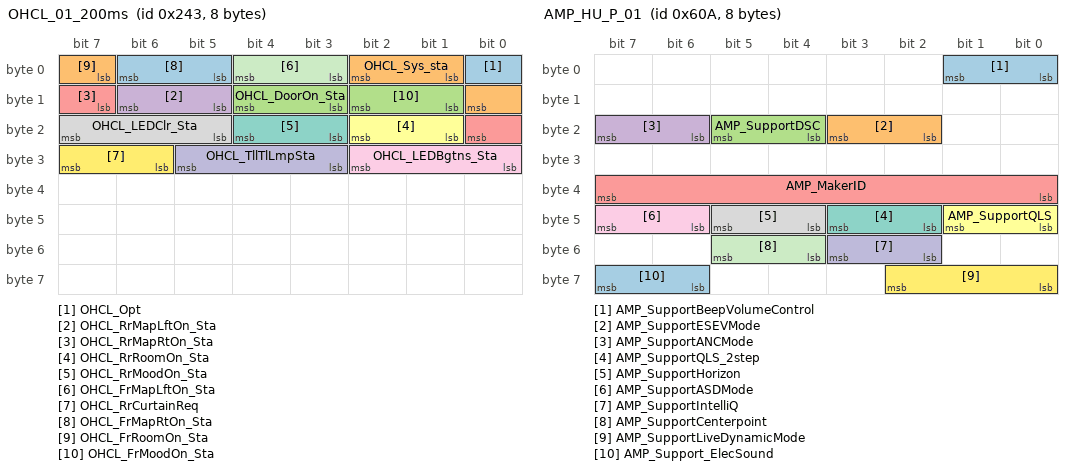
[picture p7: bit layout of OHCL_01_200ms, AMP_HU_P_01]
BO_ 579 OHCL_01_200ms: 8 OHCL
 SG_ OHCL_Opt : 0|1@1+ (1,0) [0|0] ""  ATS
 SG_ OHCL_Sys_sta : 1|2@1+ (1,0) [0|0] ""  ATS
 SG_ OHCL_DoorOn_Sta : 11|2@1+ (1,0) [0|0] ""  ATS
 SG_ OHCL_RrMapLftOn_Sta : 13|2@1+ (1,0) [0|0] ""  ATS
 SG_ OHCL_RrMapRtOn_Sta : 15|2@1+ (1,0) [0|0] ""  ATS
 SG_ OHCL_RrRoomOn_Sta : 17|2@1+ (1,0) [0|0] ""  ATS
 SG_ OHCL_RrMoodOn_Sta : 19|2@1+ (1,0) [0|0] ""  ATS
 SG_ OHCL_LEDClr_Sta : 21|3@1+ (1,0) [0|0] ""  ATS
 SG_ OHCL_LEDBgtns_Sta : 24|3@1+ (1,0) [0|0] ""  ATS
 SG_ OHCL_TllTlLmpSta : 27|3@1+ (1,0) [0|0] ""  CGW_CCU
 SG_ OHCL_FrMapLftOn_Sta : 3|2@1+ (1,0) [0|0] ""  ATS
 SG_ OHCL_RrCurtainReq : 30|2@1+ (1,0) [0|0] "" Vector__XXX
 SG_ OHCL_FrMapRtOn_Sta : 5|2@1+ (1,0) [0|0] ""  ATS
 SG_ OHCL_FrRoomOn_Sta : 7|2@1+ (1,0) [0|0] ""  ATS
 SG_ OHCL_FrMoodOn_Sta : 9|2@1+ (1,0) [0|0] ""  ATS

BO_ 1546 AMP_HU_P_01: 8 CGW_CCU
 SG_ AMP_SupportBeepVolumeControl : 0|2@1+ (1,0) [0|0] ""  ATS
 SG_ AMP_SupportESEVMode : 18|2@1+ (1,0) [0|0] "" Vector__XXX
 SG_ AMP_SupportDSC : 20|2@1+ (1,0) [0|0] "" Vector__XXX
 SG_ AMP_SupportANCMode : 22|2@1+ (1,0) [0|0] "" Vector__XXX
 SG_ AMP_MakerID : 32|8@1+ (1,0) [0|0] "" Vector__XXX
 SG_ AMP_SupportQLS : 40|2@1+ (1,0) [0|0] "" Vector__XXX
 SG_ AMP_SupportQLS_2step : 42|2@1+ (1,0) [0|0] "" Vector__XXX
 SG_ AMP_SupportHorizon : 44|2@1+ (1,0) [0|0] "" Vector__XXX
 SG_ AMP_SupportASDMode : 46|2@1+ (1,0) [0|0] "" Vector__XXX
 SG_ AMP_SupportIntelliQ : 50|2@1+ (1,0) [0|0] "" Vector__XXX
 SG_ AMP_SupportCenterpoint : 52|2@1+ (1,0) [0|0] "" Vector__XXX
 SG_ AMP_SupportLiveDynamicMode : 56|3@1+ (1,0) [0|0] "" Vector__XXX
 SG_ AMP_Support_ElecSound : 62|2@1+ (1,0) [0|0] "" Vector__XXX

CM_ BO_ 2244048387 "[P] Periodic";
CM_ SG_ 2244048387 RCU_AD3_SCC_TqIntrvntnVal "RCU_SCC_TorqueInterventionValue";
CM_ SG_ 2244048387 RCU_AD3_TCS_TqFlag "RCU_Flag indicating positive or negative TCS Intervention";
CM_ SG_ 2244048387 RCU_AD3_TCS_Sta "RCU_Status of TCS Function";
CM_ SG_ 2244048387 RCU_AD3_VehAccelVal "RCU_VehicleAccelerationValue";
CM_ SG_ 2244048387 RCU_AD3_MSR_TqFlag "RCU_Flag indicating positive or negative MSR Intervention";
CM_ SG_ 2244048387 RCU_AD3_LDM_Sta "RCU_LDM_Status";
CM_ SG_ 2244048387 RCU_AD3_ECD_ActvSta "RCU_ECD_ActiveStatus";
CM_ SG_ 2244048387 RCU_AD3_MSR_FuncReq "RCU_MSR_FunctionRequest";
CM_ SG_ 2244048387 RCU_AD3_TCS_Req "RCU_TCS_Request";
CM_ SG_ 2244048387 RCU_AD3_TCS_LmpSta "RCU_TCS_LampStatus";
CM_ SG_ 2244048387 RCU_AD3_SCC_TqReq "RCU_SCC_TorqueRequest";
CM_ SG_ 2244048387 RCU_AD3_StdStillVal "RCU_StandStillValue";
CM_ SG_ 2244048387 RCU_AD3_SCC_ReqLimSta "RCU_SCC_RequestLimitedStatus";
CM_ SG_ 2244048387 RCU_AD3_SCC_OptTyp "RCU_SCC_OptionType";
CM_ SG_ 2244048387 RCU_AD3_SCC_EnblReq "RCU_SCC_EnableRequest";
CM_ SG_ 2244048387 RCU_AD3_FCA_EquipSta "RCU_FCA_EquipmentStatus";
CM_ SG_ 2244048387 RCU_AD3_FCA_ActvSta "Status of control for RCU_FCA control request flag";
CM_ SG_ 2244048387 RCU_AD3_DclEnblReq "RCU_DecelerationEnableRequest";
CM_ SG_ 2244048387 RCU_AD3_DBS_ActvSta "RCU_DBS_ActvSta";
CM_ SG_ 2244048387 RCU_AD3_AccelBasisVal "RCU_AccelerationBasisValue";
CM_ BO_ 2244048386 "[P] Periodic";
CM_ SG_ 2244048386 RCU_AD3_Wss2FlFltSta "Wheel Speed sensor fault status (Front Left Wheel - 2nd)";
CM_ SG_ 2244048386 RCU_AD3_DiagSta "RCU DiagnosticStatus";
CM_ SG_ 2244048386 RCU_AD3_operation "Indicate RCU mode On / Off ( not each function mode )";
CM_ SG_ 2244048386 RCU_AD3_PrsrValVldSta "RCU front circuit pressure Value Validity";
CM_ SG_ 2244048386 RCU_AD3_PrsrVal "RCU front circuit pressure Value";
CM_ SG_ 2244048386 RCU_AD3_Wss2FrFltSta "Wheel Speed sensor fault status (Front Right Wheel - 2nd))";
CM_ SG_ 2244048386 RCU_AD3_ABS_DfctvSta "RCU ABS function Defective Status";
CM_ SG_ 2244048386 RCU_AD3_ABS_ActvSta "RCU ABS Active Status";
CM_ SG_ 2244048386 RCU_AD3_BBC_DfctvSta "RCU BBC function Defective Status";
CM_ SG_ 2244048386 RCU_AD3_BBC_ActvSta "RCU BBC Active Status";
CM_ SG_ 2244048386 RCU_AD3_Wss2RlFltSta "Wheel Speed sensor fault status (Rear Left Wheel - 2nd)";
CM_ SG_ 2244048386 RCU_AD3_BrkLtActSta "RCU_BrakeLightActiveStatus";
CM_ SG_ 2244048386 RCU_AD3_DrvOvrdSta "RCU_OverrideRequest";
CM_ SG_ 2244048386 RCU_AD3_PrkBrkActvSta "RCU_ParkingBrakeActiveStatus";
CM_ SG_ 2244048386 RCU_AD3_FCA_AvlblSta "RCU_FCA_AvailableStatus";
CM_ SG_ 2244048386 RCU_AD3_MSR_TqIntrvntnVal "RCU_MSR_TorqueInterventionValue";
CM_ SG_ 2244048386 RCU_AD3_TCS_TqIntrvntnVal "RCU_TCS_TorqueInterventionValue";
CM_ SG_ 2244048386 RCU_AD3_Wss2RrFltSta "Wheel Speed sensor fault status (Rear Right Wheel - 2nd)";
CM_ SG_ 2244048386 RCU_AD3_SrvLmpDis "RCU_ServiceLampDisplay";
CM_ BO_ 2244048385 "[P] Periodic";
CM_ SG_ 2244048385 RCU_Crc3Val "RCU_CyclicRedundancyCheck3Value";
CM_ SG_ 2244048385 RCU_AlvCnt3Val "RCU_AliveCounter3Value";
CM_ SG_ 2244048385 RCU_HDP_FltMonSta "RCU_HDP_FaultStatus";
CM_ SG_ 2244048385 RCU_HDP_EgSta "RCU_HDP_EngagedStatus";
CM_ SG_ 2244048385 RCU_HDP_EnblReq "RCU_HDP_EnableRequest";
CM_ SG_ 2244048385 RCU_AD3_RCUFltSta "RCU fault status ( degraded support / not support )";
CM_ SG_ 2244048385 RCU_AD3_AWD_FastOpnCrdnShftCltch "(RCU) AWD_FastOpenCardanShaftClutchRequest";
CM_ SG_ 2244048385 RCU_AD3_StrkDpthmmVal "RCU Pedal ( PTS2 ) Stroke Depth mmValue";
CM_ SG_ 2244048385 RCU_AD3_PdlTrvlSnsrValVldSta "RCU_PedalTravelSensor Value Validity Status (PTS2)";
CM_ SG_ 2244048385 RCU_AD3_PdlCalibSta "RCU_PedalCalibrationStatus ( PTS2 )";
CM_ SG_ 2244048385 RCU_AD3_WSSmode "RCU Wheel control mode";
CM_ BO_ 527 "[PE] Periodic and On Event";
CM_ SG_ 527 ATS_DrvStRseFwdBtn "Drive Seat  RSE Forward Touch Button";
CM_ SG_ 527 ATS_DrvStRseBwdBtn "Drive Seat  RSE Backward Touch Button";
CM_ SG_ 527 ATS_RRRestModBtn "Rear Right Rest Mode Touch Button";
CM_ SG_ 527 ATS_RRResetModBtn "Rear Right Return Mode Touch Button";
CM_ SG_ 527 ATS_RRAvWtcModBtn "Rear Right AV Watching Mode Touch Button";
CM_ SG_ 527 ATS_RRReadingModBtn "Rear Right Reading Mode Touch Button";
CM_ SG_ 527 ATS_RLRestModBtn "Rear Left Rest Mode Touch Button";
CM_ SG_ 527 ATS_RLResetModBtn "Rear Left Return Mode Touch Button";
CM_ BO_ 2244048388 "[P] Periodic";
CM_ SG_ 2244048388 RCU_HDPSpprtSWVer "IEB/RCU - HDP Support Software Version";
CM_ SG_ 2244048388 RCU_AD3_ABS_WrngLmpSta "RCU_ABS_WarningLampStatus";
CM_ SG_ 2244048388 RCU_AD3_ESC_Sta "Status of RCU ESC Function";
CM_ BO_ 1616 "[EC] On Event and On Change";
CM_ SG_ 1616 MKBD_IllumiState "Signal to confirm completion transmission of illumination information between MKBD and HU";
CM_ SG_ 1616 MKBD_SeatKeySet "The signal for transmitting Seat Key inputs from MKBD to Seat ECU";
CM_ BO_ 543 "[PE] Periodic and On Event";
CM_ SG_ 543 ATS_AstStSldFwdBtn "Assist Power Seat Slide Forward Rear Walk In Button";
CM_ SG_ 543 ATS_AstStSldBwdBtn "Assist Power Seat Slide Backward Rear Walk In Button";
CM_ SG_ 543 ATS_AstStRclFwdBtn "Assist Power Seat Recline Forward Rear Walk In Button";
CM_ SG_ 543 ATS_AstStRclBwdBtn "Assist Power Seat Recline Backward Rear Walk In Button";
CM_ SG_ 543 ATS_AstStHgtUpBtn "Assist Power Seat Height Up Walk In Button";
CM_ SG_ 543 ATS_AstStHgtDnBtn "Assist Power Seat Height Dn Walk In Button";
CM_ SG_ 543 ATS_AstStHRestUpBtn "Assist Power Seat Head Rest Up Walk In Button";
CM_ SG_ 543 ATS_AstStHRestDnBtn "Assist Power Seat  Head Rest Dn Walk In Button";
CM_ SG_ 543 ATS_AstStHRestFwdBtn "Assist Power Seat Head Rest Forward  Walk In Button";
CM_ SG_ 543 ATS_AstStHRestBwdBtn "Assist Power Seat Head Rest Backward  Walk In Button";
CM_ SG_ 543 ATS_AstStHRestFldBtn "Assist Power Seat Head Rest Folding  Walk In Button";
CM_ SG_ 543 ATS_AstStHRestUnFldBtn "Assist Power Seat Head Rest Unfolding  Walk In Button";
CM_ SG_ 543 ATS_AstStRseFwdBtn "Assist Power Seat RSE Forward  Walk In Button";
CM_ SG_ 543 ATS_AstStRseBwdBtn "Assist Power Seat RSE Backward Walk In Button";
CM_ SG_ 543 ATS_AstStFRestFldBtn "Assist Power Seat Foot Rest Folding Walk In Button";
CM_ SG_ 543 ATS_AstStFRestUnFldBtn "Assist Power Seat Foot Rest Unfolding Walk In Button";
CM_ SG_ 543 ATS_AstTltUpBtn "Assist Power Seat  Tilt Up Walk In Button";
CM_ SG_ 543 ATS_AstTltDnBtn "Assist Power Seat Tilt Down  Walk In Button";
CM_ BO_ 2214658052 "[P] Periodic";
CM_ SG_ 2214658052 ENG_DclBrkCntrlReq "ENG_DecelerationBrakeControlRequest ##2G##EMS - EMS19 - CF_Ems_DecelReq";
CM_ SG_ 2214658052 ENG_BstPrsrVal "ENG_BoostPressureValue ##2G##EMS - EMS19 - CR_Ems_BstPre";
CM_ SG_ 2214658052 ENG_EngOilTempVal "ENG_EngineOilTemperatureValue ##2G##EMS - EMS19 - CR_Ems_EngOilTemp";
CM_ SG_ 2214658052 ENG_AmbtTempModelVal "ENG_AmbientTemperatureModelValue ##2G##EMS - EMS19 - CF_Ems_ModeledAmbTemp";
CM_ SG_ 2214658052 ENG_DpfWrngSta "ENG_DpfWarningStatus ##2G##EMS - EMS19 - DPF_LAMP_STAT";
CM_ SG_ 2214658052 ENG_BattWrngLmpSta "ENG_BatteryWarningLampStatus ##2G##EMS - EMS19 - BAT_LAMP_STAT";
CM_ SG_ 2214658052 ENG_OilPrsrWrngLmpSta "ENG_OilPressureWarningLampStatus ##2G##EMS - EMS19 - CF_Ems_OPSFail";
CM_ SG_ 2214658052 ENG_IsgInhbtLmpSta "ENG_IsgInhibitLampStatus ##2G##EMS - EMS19 - ISG_INHIBIT_LAMP_STAT";
CM_ BO_ 2273435649 "[P] Periodic";
CM_ SG_ 2273435649 ADAS_CMD_Crc31Val "ADAS_CMD_CyclicRedundancyCheck31Value";
CM_ SG_ 2273435649 ADAS_CMD_AlvCnt31Val "ADAS_CMD_AliveCounter31Value";
CM_ SG_ 2273435649 HDA_OptUsmSta "HDA_OptionUSMStatus ##2G##LDW_LKA - HDA11 - CF_HDA_Opt_USM";
CM_ SG_ 2273435649 HDA_CntrlModSta "HDA_ControlModeStatus ##2G##LDW_LKA - HDA11 - CF_HDA_Mode";
CM_ SG_ 2273435649 HDA_InfoPUDis "HDA_InformationPopUpDisplay ##2G##LDW_LKA - HDA11 - CF_HDA_InfoDisplay";
CM_ SG_ 2273435649 HDP_AutoCallReqSta "HDP Auto Call Request State";
CM_ SG_ 2273435649 HDP_DispBarSta "HDP Display Bar State";
CM_ SG_ 2273435649 HDP_OptInfoSta "HDP Option Infomation State";
CM_ SG_ 2273435649 HDA_LFA_SymSta "HDA_LFA_SymbolStatus ##2G##LDW_LKA - HDA11 - CF_HDA_LFA_SymbolState";
CM_ SG_ 2273435649 HDA_LFA_WrnSnd "HDA/LFA Additional Warning Sound";
CM_ SG_ 2273435649 HDA_InfoPUDis1 "HDA_InfomationPopupDisplay";
CM_ SG_ 2273435649 HDP_ActvSta "HDP_ControlActiveStatus";
CM_ SG_ 2273435649 HDP_SysSta "HDP_SystemStatus";
CM_ BO_ 2273435650 "[P] Periodic";
CM_ SG_ 2273435650 HDP_ObstacleDstVal "HDP_InPathObstacleDistance";
CM_ SG_ 2273435650 HDP_ObstacleLatPosVal "HDP_InPathObstaclePositionValue";
CM_ SG_ 2273435650 HDP_InfoPUDis "HDP_InformationPopupDisplay (main pop-up)";
CM_ SG_ 2273435650 HDP_WrngTypPUDis "HDP_WarningTypePopupDisplay (mini pop-up)";
CM_ SG_ 2273435650 HDP_HapticWarnReq "Request for HDP haptic warning";
CM_ SG_ 2273435650 HDP_ActvStaDis "HDP_Active/Deactive Status Display";
CM_ SG_ 2273435650 HDP_OpStaDisp "HDP Operation State Display";
CM_ SG_ 2273435650 HDP_ObstSta "HDP Obstacle State";
CM_ SG_ 2273435650 HDP_SysFlrDisp "HDP System Failure Display";
CM_ SG_ 2273435650 HDP_InhbtOffDispSta "HDP Inhibit Off Display State";
CM_ SG_ 2273435650 HDP_CtRoadSrfcDistVal "HDP Center Road Surface Distance Value";
CM_ SG_ 2273435650 ADAS_DRV_UpDateInfo "ADAS_DRV update state info";
CM_ BO_ 2214658049 "[P] Periodic";
CM_ SG_ 2214658049 EMS_Crc2Val "EMS_CyclicRedundancyCheck2Value";
CM_ SG_ 2214658049 EMS_AlvCnt2Val "EMS_AliveCounter2Value";
CM_ SG_ 2214658049 ENG_BrkSwSta "ENG_BrakeSwitchStatus ##2G##EMS - EMS12 - BRAKE_ACT";
CM_ SG_ 2214658049 ENG_ObdFrzFrmSta "ENG_ObdFreezeFrameStatus ##2G##EMS - EMS12 - OBD_FRF_ACK";
CM_ SG_ 2214658049 ENG_EngClntTempVal "ENG_EngineCoolantTemperatureValue ##2G##EMS - EMS12 - TEMP_ENG";
CM_ SG_ 2214658049 ENG_MafCrctVal "ENG_MassAirFlowCorrectionValue ##2G##EMS - EMS12 - MAF_FAC_ALTI_MMV";
CM_ SG_ 2214658049 ENG_BattDscnctSta "ENG_BatteryDisconnectStatus ##2G##EMS - EMS12 - VB_OFF_ACT";
CM_ SG_ 2214658049 OBD_MilConfgVal "OBD_MalfunctionIndicationLampConfigurationValue ##2G##EMS - EMS12 - CONF_MIL_FMY";
CM_ SG_ 2214658049 ENG_EngSta "ENG_EngineStatus ##2G##EMS - EMS16 - ENG_STAT";
CM_ BO_ 614 "[PE] Periodic and On Event";
CM_ SG_ 614 EMCU_Crc1Val "EMCU_CyclicRedundancyCheck1Value";
CM_ SG_ 614 EMCU_AlvCnt1Val "EMCU_AliveCounter1Value";
CM_ SG_ 614 EMCU_LHActSta "EMCU_LeftActuatorStatus";
CM_ SG_ 614 EMCU_RHActSta "EMCU_RightActuatorStatus";
CM_ SG_ 614 EMCU_DeltaSpdVal "EMCU_DeltaSpeedValue";
CM_ SG_ 614 EMCU_System_Sta "EMCU_SystemStatus";
CM_ BO_ 1578 "[EW] On Event and On Write";
CM_ SG_ 1578 PSB_CCP_CRO_Byte0 "EOL Message for PSB";
CM_ SG_ 1578 PSB_CCP_CRO_Byte2 "EOL Message for PSB";
CM_ SG_ 1578 PSB_CCP_CRO_Byte3 "EOL Message for PSB";
CM_ SG_ 1578 PSB_CCP_CRO_Byte4 "EOL Message for PSB";
CM_ SG_ 1578 PSB_CCP_CRO_Byte5 "EOL Message for PSB";
CM_ SG_ 1578 PSB_CCP_CRO_Byte6 "EOL Message for PSB";
CM_ SG_ 1578 PSB_CCP_CRO_Byte7 "EOL Message for PSB";
CM_ SG_ 1578 PSB_CCP_CRO_Byte1 "EOL Message for PSB";
CM_ BO_ 1579 "[EW] On Event and On Write";
CM_ SG_ 1579 PSB_CCP_DTO_Byte0 "EOL Message for PSB";
CM_ SG_ 1579 PSB_CCP_DTO_Byte2 "EOL Message for PSB";
CM_ SG_ 1579 PSB_CCP_DTO_Byte3 "EOL Message for PSB";
CM_ SG_ 1579 PSB_CCP_DTO_Byte4 "EOL Message for PSB";
CM_ SG_ 1579 PSB_CCP_DTO_Byte5 "EOL Message for PSB";
CM_ SG_ 1579 PSB_CCP_DTO_Byte6 "EOL Message for PSB";
CM_ SG_ 1579 PSB_CCP_DTO_Byte7 "EOL Message for PSB";
CM_ SG_ 1579 PSB_CCP_DTO_Byte1 "EOL Message for PSB";
CM_ BO_ 2214658051 "[P] Periodic";
CM_ SG_ 2214658051 ENG_MinIndTqVal "ENG_MinimumIndicatedTorqueValue ##2G##EMS - EMS16 - TQI_MIN";
CM_ SG_ 2214658051 ENG_TrgtTqVal "ENG_TargetTorqueValue ##2G##EMS - EMS16 - TQI_TARGET";
CM_ SG_ 2214658051 ENG_MaxIndTqVal "ENG_MaximumIndicatedTorqueValue ##2G##EMS - EMS16 - TQI_MAX";
CM_ SG_ 2214658051 ENG_AppAccelPdlSta "ENG_AppliedAcceleratorPedalStatus ##2G##EMS - EMS16 - CF_Ems_AclAct";
CM_ SG_ 2214658051 ENG_BrkCtrlReq "ENG_BrakeControlRequest ##2G##EMS - EMS19 - CF_Ems_BrkReq";
CM_ SG_ 2214658051 ACC_DnShftCtrlReq "ACC_DownShiftControlRequest ##2G##EMS - EMS19 - CF_Ems_DnShftReq";
CM_ BO_ 2214658050 "[P] Periodic";
CM_ SG_ 2214658050 ENG_Ack4EngStpSta "ENG_AcknowledgeForEngineStopStatus ##2G##EMS - EMS12 - ACK_ES";
CM_ SG_ 2214658050 ENG_AccDrvAlertDisp "The status of No Auto cruise Engaged or Auto cruise Disengaged.";
CM_ SG_ 2214658050 DSL_GlowCtrlReq "DSL_GlowControlRequest ##2G##EMS - EMS12 - GP_CTL";
CM_ SG_ 2214658050 ENG_GlowLmpSta "ENG_GlowLampStatus ##2G##EMS - EMS16 - GLOW_STAT";
CM_ SG_ 2214658050 ENG_ThrPosVal "ENG_ThrottlePositionValue ##2G##EMS - EMS12 - TPS";
CM_ SG_ 2214658050 ENG_OverDrvOffReq "ENG_OverDriveOffRequest ##2G##EMS - EMS12 - OD_OFF_REQ";
CM_ SG_ 2214658050 ENG_AccelPdlVal "ENG_AcceleratorPedalValue ##2G##EMS - EMS12 - PV_AV_CAN";
CM_ SG_ 2214658050 ENG_AccActSta "ENG_AutoCruiseControlActiveStatus ##2G##EMS - EMS12 - ACC_ACT";
CM_ SG_ 2214658050 ACC_CrsMainSwLmpSta "ACC_CruiseMainSwLampStatus ##2G##EMS - EMS16 - CRUISE_LAMP_M";
CM_ SG_ 2214658050 ACC_CrsSetSwLmpSta "ACC_CruiseSetSwLampStatus ##2G##EMS - EMS16 - CRUISE_LAMP_S";
CM_ SG_ 2214658050 ENG_LV_FUP_ENA_THD "Fuel prsssure state ##2G##EMS - LPI11 - LV_FUP_ENA_THD";
CM_ SG_ 2214658050 ENG_SoakTimeErrSta "ENG_SoakTimeErrorStatus ##2G##EMS - EMS16 - SOAK_TIME_ERROR";
CM_ SG_ 2214658050 ENG_SoakTimeVal "ENG_SoakTimeValue ##2G##EMS - EMS16 - SOAK_TIME";
CM_ SG_ 2214658050 ENG_SprkTimeVal "ENG_SparkTimeValue ##2G##EMS - EMS16 - SPK_TIME_CUR";
CM_ SG_ 2214658050 ENG_CltchOpSta "ENG_ClutchStatus ##2G##EMS - EMS12 - CLU_ACK";
CM_ SG_ 2214658050 EMS_BrkReq_Slope "Brake request at slope for anti-stall";
CM_ BO_ 623 "[PE] Periodic and On Event";
CM_ SG_ 623 ATS_ARSOpenCloseStatus "Armrest Open / Close Status";
CM_ SG_ 623 ATS_RLLumbarDefBtn "Rear Left Lumbar Deflation Touch Button";
CM_ SG_ 623 ATS_RLLumbarLowBtn "Rear Left Lumbar Low Touch Button";
CM_ SG_ 623 ATS_RLLumbarMidBtn "Rear Left Lumbar Middle Touch Button";
CM_ SG_ 623 ATS_RLLumbarUpBtn "Rear Left Lumbar Up Touch Button";
CM_ SG_ 623 ATS_RLBolsterDefBtn "Rear Left Bolster Deflation Touch Button";
CM_ SG_ 623 ATS_RLBolsterInfSw "Rear Left Bolster Inflation Touch Button";
CM_ SG_ 623 ATS_RRLumbarDefBtn "Rear Right Lumbar Deflation Touch Button";
CM_ SG_ 623 ATS_RRLumbarLowBtn "Rear Right Lumbar Low Touch Button";
CM_ SG_ 623 ATS_RRLumbarMidBtn "Rear Right Lumbar Middle Touch Button";
CM_ SG_ 623 ATS_RRLumbarUpBtn "Rear Right Lumbar Up Touch Button";
CM_ SG_ 623 ATS_RRBolsterDefBtn "Rear Right Bolster Deflation Touch Button";
CM_ SG_ 623 ATS_RRBolsterInfSw "Rear Right Bolster Inflation Touch Button";
CM_ BO_ 639 "[EC] On Event and On Change";
CM_ SG_ 639 ATS_RRSeatHeaterSW "ATS touch command for seat heat control (For Rear Right seat)";
CM_ SG_ 639 ATS_RLSeatHeaterUpSW "ATS touch command for seat heat control  (For Rear Left seat)";
CM_ SG_ 639 ATS_RRSeatVentDownSW "ATS touch command for seat Vent control (For Rear Right seat)";
CM_ SG_ 639 ATS_RLSeatVentDownSW "ATS touch command for seat Vent control (For Rear Left seat)";
CM_ SG_ 639 ATS_RLMemoryRestBtn "Rear Left Rest Mode Custom Save Button (Except North America)";
CM_ SG_ 639 ATS_RLMemoryReturnBtn "Rear Left Return Mode Custom Save Button (Except North America)";
CM_ SG_ 639 ATS_RLSeatHeaterSW "ATS touch command for seat heat control  (For Rear Left seat)";
CM_ SG_ 639 ATS_RRMemoryRestBtn "Rear Right Rest Mode Custom Save Button (Except North America)";
CM_ SG_ 639 ATS_RRMemoryReturnBtn "Rear Right Return Mode Custom Save Button (Except North America)";
CM_ SG_ 639 ATS_RRMemoryAvWtcBtn "Rear Right AV Watching Mode Custom Save Button (Except North America)";
CM_ SG_ 639 ATS_RRMemoryReadingBtn "Rear Right Reading Mode Custom Save Button (Except North America)";
CM_ SG_ 639 ATS_RRRestModBtnSTD "Rear Right Rest Mode Touch Button (EXCEPT North America)";
CM_ SG_ 639 ATS_RRResetModBtnSTD "Rear Right Return Mode Touch Button (EXCEPT North America)";
CM_ SG_ 639 ATS_RRAvWtcModBtnSTD "Rear Right AV Watching Mode Touch Button (EXCEPT North America)";
CM_ SG_ 639 ATS_RRReadingModBtnSTD "Rear Right Reading Mode Touch Button (EXCEPT North America)";
CM_ SG_ 639 ATS_RRSeatVentSW "ATS touch command for seat Vent control (For Rear Right seat)";
CM_ SG_ 639 ATS_RLRestModBtnSTD "Rear Left Rest Mode Touch Button (EXCEPT North America)";
CM_ SG_ 639 ATS_RLResetModBtnSTD "Rear Left Return Mode Touch Button (EXCEPT North America)";
CM_ SG_ 639 ATS_RRModestateStopBtn "Rear Right One touch mode Stop Button";
CM_ SG_ 639 ATS_RLModestateStopBtn "Rear Left One touch mode Stop Button";
CM_ SG_ 639 ATS_RLResetRestBtn "Rear Left Rest Mode Custom Initialization Button (Except North America)";
CM_ SG_ 639 ATS_RLResetReturnBtn "Rear Left Return Mode Custom Initialization Button (Except North America)";
CM_ SG_ 639 ATS_RRResetRestBtn "Rear Right Rest Mode Custom Initialization Button (Except North America)";
CM_ SG_ 639 ATS_RRResetReturnBtn "Rear Right Return Mode Custom Initialization Button (Except North America)";
CM_ SG_ 639 ATS_RRResetAvWtcBtn "Rear Right AV Watching Mode Custom Initialization Button (Except North America)";
CM_ SG_ 639 ATS_RRResetReadingBtn "Rear Right Reading Mode Custom Initialization Button (Except North America)";
CM_ SG_ 639 ATS_RLSeatVentSW "ATS touch command for seat Vent control (For Rear Left seat)";
CM_ SG_ 639 ATS_RRSeatHeaterUpSW "ATS touch command for seat heat control  (For Rear Right seat)";
CM_ BO_ 1584 "[EC] On Event and On Change";
CM_ SG_ 1584 AMP_NaviWarnSound "Navi Warning prompt on/off";
CM_ SG_ 1584 AMP_Beep1Mode "Play touch beep sound one time
Beep1 mode on/off
For Harman AMP
Default : Off
Goes On when play beep sound
-This Signal's Feedback is AMP_Beep1ModeState(0x180)@AMP";
CM_ SG_ 1584 AMP_RrTTSSound "Rear TTS prompt on/offOnly ON during the Rear TTS Sound Playing Default : Off-This Signal's Feedback is AMP_RrTTSModeState(0x60c)@AMP";
CM_ SG_ 1584 AMP_ASDMode "ASD Set Mode Value";
CM_ SG_ 1584 AMP_ANCMode "Signal for setting ANC On/Off";
CM_ SG_ 1584 AMP_NaviSound "Navi prompt on/off
Only ON during the Navi Guide Sound Playing
Default : Off
-This Signal's Feedback is AMP_NaviModeState(0x180)@AMP";
CM_ SG_ 1584 AMP_ETCSSound "ETCS sound on/off";
CM_ SG_ 1584 AMP_Beep1KBDMode "Play touch beep sound at keyboard screen on AVN-This Signal's Feedback is AMP_Beep1KBDModeState@AMP";
CM_ SG_ 1584 AMP_ETCSVolumeStep "- Command for ETCS Volume Setting";
CM_ SG_ 1584 AMP_NaviWarnVolumeStep "- Command for Navigation Warning Prompt Volume Setting";
CM_ SG_ 1584 AMP_TTSSound "TTS prompt on/offOnly ON during the TTS Sound Playing Default : Off-This Signal's Feedback is AMP_TTSModeState(0x60c)@AMP";
CM_ SG_ 1584 AMP_SDVCStep "SDVC(Speed Dependant Volume Control = VSC) 
Step4 : off, low, mid, high";
CM_ BO_ 577 "[PE] Periodic and On Event";
CM_ SG_ 577 C_AstBolsterInfSw_HU "Assistant seat moving switch: Bolster Inflate";
CM_ SG_ 577 C_RLHrestUpSw_HU "2nd Left side seat Moving control : Headrest Up";
CM_ SG_ 577 C_RLHrestDnSw_HU "2nd Left side seat Moving control : Headrest Down";
CM_ SG_ 577 C_RLHrestFwdSw_HU "2nd Left side seat Moving control : Headrest Forward";
CM_ SG_ 577 C_AstBolsterDefSw_HU "Assistant seat moving switch: Bolster Deflate";
CM_ SG_ 577 C_RLHrestBwdSw_HU "2nd Left side seat Moving control : Headrest Backward";
CM_ SG_ 577 C_RLLumbarUpSw_HU "2nd Left side seat Moving control : Lumbar Up";
CM_ SG_ 577 C_RLLumbarMidSw_HU "2nd Left side seat Moving control : Lumbar Mid";
CM_ SG_ 577 C_RLLumbarLowSw_HU "2nd Left side seat Moving control : Lumbar Low";
CM_ SG_ 577 C_RLLumbarDefSw_HU "2nd Left side seat Moving control : Lumbar Deflate";
CM_ SG_ 577 C_RLBolsterInfSw_HU "2nd Left side seat Moving control : Bolster Inflate";
CM_ SG_ 577 C_RLBolsterDefSw_HU "2nd Left side seat Moving control : Bolster Deflate";
CM_ SG_ 577 C_AstHrestUpSw_HU "Assistant seat moving switch : Headrest Up";
CM_ SG_ 577 C_AstHrestDnSw_HU "Assistant seat Moving control : Headrest Down";
CM_ SG_ 577 C_AstFootrestFldSw_HU "Assistant seat moving switch: Footrest Fold";
CM_ SG_ 577 C_AstHrestFwdSw_HU "Assistant seat Moving control : Headrest Forward";
CM_ SG_ 577 C_AstHrestBwdSw_HU "Assistant seat moving switch : Headrest Backward";
CM_ SG_ 577 C_AstFootrestUnFldSw_HU "Assistant seat moving switch: Footrest Unfold";
CM_ BO_ 578 "[PE] Periodic and On Event";
CM_ SG_ 578 C_RRLegSupFwdSw_HU "2nd Right side seat Moving control : Leg Support Forward";
CM_ SG_ 578 C_RRHrestDnSw_HU "2nd Right side seat Moving control : Headrest Down";
CM_ SG_ 578 C_RRHrestFwdSw_HU "2nd Right side seat Moving control : Headrest Forward";
CM_ SG_ 578 C_RRHrestBwdSw_HU "2nd Right side seat Moving control : Headrest Backward";
CM_ SG_ 578 C_RRLumbarUpSw_HU "2nd Right side seat Moving control : Lumbar Up";
CM_ SG_ 578 C_RRLumbarMidSw_HU "2nd Right side seat Moving control : Lumbar Mid";
CM_ SG_ 578 C_RRLegSupBwdSw_HU "2nd Right side seat Moving control : Leg Support Backward";
CM_ SG_ 578 C_RRLumbarLowSw_HU "2nd Right side seat Moving control : Lumbar Low";
CM_ SG_ 578 C_RRLumbarDefSw_HU "2nd Right side seat Moving control : Lumbar Deflate";
CM_ SG_ 578 C_RRBolsterInfSw_HU "2nd Right side seat Moving control : Bolster Inflate";
CM_ SG_ 578 C_RRLegSupUpSw_HU "2nd Right side seat Moving control : Leg Support Up";
CM_ SG_ 578 C_RROneTchNValueSet "2nd Right side seat One Touch Mode";
CM_ SG_ 578 C_RLOneTchNValueSet "2nd Left side seat One Touch Mode";
CM_ SG_ 578 C_RRBolsterDefSw_HU "2nd Right side seat Moving control : Bolster Deflate";
CM_ SG_ 578 C_AstRlxTiltUpSw_HU "Assistant seat Moving control : Relaxtion Tilt Up";
CM_ SG_ 578 C_AstRlxTiltDnSw_HU "Assistant seat Moving control : Relaxtion Tilt Down";
CM_ SG_ 578 C_RLRSEUpSw_HU "2nd Left side seat Moving control : RSE Up";
CM_ SG_ 578 C_RLRSEDnSw_HU "2nd Left side seat Moving control : RSE Down";
CM_ SG_ 578 C_RRRSEUpSw_HU "2nd Right side seat Moving control : RSE Up";
CM_ SG_ 578 C_RRLegSupDnSw_HU "2nd Right side seat Moving control : Leg Support Down";
CM_ SG_ 578 C_RRRSEDnSw_HU "2nd Right side seat Moving control : RSE Down";
CM_ SG_ 578 C_RRHrestUpSw_HU "2nd Right side seat Moving control : Headrest Up";
CM_ BO_ 2424579841 "[PE] Periodic and On Event";
CM_ SG_ 2424579841 DATC_Crc11Val "DATC_CyclicRedundancyCheck11Value";
CM_ SG_ 2424579841 DATC_AlvCnt11Val "DATC_AliveCounter11Value";
CM_ SG_ 2424579841 DATC_TnnlClimtUSMSta "DATC_TunnelCLimateUSMState";
CM_ SG_ 2424579841 DATC_ProximitySnsrSta "DATC_ProximitySensorStatus";
CM_ SG_ 2424579841 DATC_TunnelFuncOff4AutoDfgReq "DATC_TunnelFunctionOffForAutoDefogRequest";
CM_ SG_ 2424579841 DATC_RrCtlLckSta "Datc_RearClimateControlLockStatus";
CM_ SG_ 2424579841 DATC_DrvrStHtrUSMSta "DATC_DriverSeatHeaterUSMStatus";
CM_ SG_ 2424579841 DATC_InDrctVntUSMSta "DATC_InDirectVent_USM_State";
CM_ SG_ 2424579841 DATC_WshFldUSMSta "DATC_WasherFulidUSMState";
CM_ SG_ 2424579841 DATC_DfgLgcUSMSta "DefLogic USM State";
CM_ SG_ 2424579841 DATC_AutoFrshUSMSta "Auto Fresh USM State";
CM_ SG_ 2424579841 DATC_HptIntnstySta "Haptic Intensity State";
CM_ SG_ 2424579841 DATC_ClmtPwrSum_W "accumulated energy consumption while driving(200ms)";
CM_ BO_ 579 "[PE] Periodic and On Event";
CM_ SG_ 579 OHCL_Opt "OHCL option state";
CM_ SG_ 579 OHCL_Sys_sta "OHCL Status";
CM_ SG_ 579 OHCL_DoorOn_Sta "Door lamp switch On/Off status";
CM_ SG_ 579 OHCL_RrMapLftOn_Sta "Rear left map lamp On/Off status";
CM_ SG_ 579 OHCL_RrMapRtOn_Sta "Rear right map lamp On/Off status";
CM_ SG_ 579 OHCL_RrRoomOn_Sta "Rear room lamp On/Off status";
CM_ SG_ 579 OHCL_RrMoodOn_Sta "Rear mood lamp On/Off status";
CM_ SG_ 579 OHCL_LEDClr_Sta "Interior lamps lighting color status";
CM_ SG_ 579 OHCL_LEDBgtns_Sta "Interior lamps brightness status";
CM_ SG_ 579 OHCL_TllTlLmpSta "PAB tell tale lamp status";
CM_ SG_ 579 OHCL_FrMapLftOn_Sta "Front left map lamp On/Off status";
CM_ SG_ 579 OHCL_RrCurtainReq "Rear Curtain Switch On/Off Signal";
CM_ SG_ 579 OHCL_FrMapRtOn_Sta "Front right map lamp On/Off status";
CM_ SG_ 579 OHCL_FrRoomOn_Sta "Front room lamp On/Off status";
CM_ SG_ 579 OHCL_FrMoodOn_Sta "Front mood lamp On/Off status";
CM_ BO_ 1546 "[P] Periodic";
CM_ SG_ 1546 AMP_SupportBeepVolumeControl "Information for AMPsupport configurable Beep1
send 500msec after Booting up";
CM_ SG_ 1546 AMP_SupportESEVMode "Information for AMP support ESEV(Engine Sound by Engine Vibration).";
CM_ SG_ 1546 AMP_SupportDSC "Does amp support Dynamic Speed Compensation mode?";
CM_ SG_ 1546 AMP_SupportANCMode "Does AMP support ANC?";
CM_ SG_ 1546 AMP_MakerID "Information for AMP Maker
For model afrer 2014, use 0x01~0x03 only.
* Use Only 0x01~0x03 values after 2014 *";
CM_ SG_ 1546 AMP_SupportQLS "Information for amp support Quantum Logic Surround mode
Harman AMP Only";
CM_ SG_ 1546 AMP_SupportQLS_2step "Information for amp support 2 Step Quantum Logic Surround mode Harman AMP Only";
CM_ SG_ 1546 AMP_SupportHorizon "Information for amp support Meridian Horizon mode Meridian AMP Only";
CM_ SG_ 1546 AMP_SupportASDMode "Information for  AMP support ASD (Active Sound Design, Virtual Engine Sound)";
CM_ SG_ 1546 AMP_SupportIntelliQ "Does amp support Meridian Intelli-Q mode?";
CM_ SG_ 1546 AMP_SupportCenterpoint "Does amp support CenterPoint mode?";
CM_ SG_ 1546 AMP_SupportLiveDynamicMode "Information for amp
 Support
 LiveDynamic mode";
CM_ SG_ 1546 AMP_Support_ElecSound "inform to H/U & CLU whether amp support premium electric sound or not";
BA_DEF_ BO_  "DiagState" ENUM  "No","Yes";
BA_DEF_ BO_  "DiagResponse" ENUM  "No","Yes";
BA_DEF_ BO_  "DiagRequest" ENUM  "No","Yes";
BA_DEF_ BO_  "TpMessage" ENUM  "No","Yes";
BA_DEF_ BO_  "UsrMsgIDSforwardDeviation" INT 0 100;
BA_DEF_ BO_  "UsrMsgIDSbackwardDeviation" INT 50 1000;
BA_DEF_ BO_  "GenMsgCycleTime" INT 0 2000;
BA_DEF_ BO_  "GenMsgStartDelayTime" INT 0 2000;
BA_DEF_ BO_  "GenMsgSendType" ENUM  "Cyclic","NoMsgSendType";
BA_DEF_ BO_  "GenMsgCycleTimeFast" INT 0 500;
BA_DEF_ BO_  "GenMsgDelayTime" INT 0 20;
BA_DEF_ BO_  "GenMsgILSupport" ENUM  "No","Yes";
BA_DEF_ BO_  "GenMsgNrOfRepetition" INT 0 3;
BA_DEF_ BO_  "NmMessage" ENUM  "No","Yes";
BA_DEF_ BO_  "NWM-Botschaft" ENUM  "No","Yes";
BA_DEF_ BO_  "TpTxIndex" INT 0 65535;
BA_DEF_ BO_  "VFrameFormat" ENUM  "StandardCAN","ExtendedCAN","reserved","reserved","reserved","reserved","reserved","reserved","reserved","reserved","reserved","reserved","reserved","reserved","StandardCAN_FD","ExtendedCAN_FD";
BA_DEF_ SG_  "UserSigValidity" ENUM  "B+","ACC","IG","IG1","IG2","IG3","IG1 or IG2","IG1 or IG3","Undef";
BA_DEF_ SG_  "TimeoutValue" STRING ;
BA_DEF_ SG_  "UsrSigPurpose" ENUM  "Undef","FN","DIAG","DIAG(Req)","DIAG(Res)","DIAG(Phy)","DEV","CCP(Req)","CCP(Res)","NM","TP";
BA_DEF_ SG_  "GenSigStartValue" INT 0 1215752192;
BA_DEF_ SG_  "NetworkRequest" ENUM  "Yes","No";
BA_DEF_ SG_  "NetworkRequestHoldingTime" INT 0 65535;
BA_DEF_ SG_  "Description" STRING ;
BA_DEF_ SG_  "Version" STRING ;
BA_DEF_ SG_  "GenSigEnvVarType" ENUM  "Int","Float","Undef";
BA_DEF_ SG_  "GenSigSendType" ENUM  "Cyclic","OnWrite","OnWriteWithRepetition","OnChange","OnChangeWithRepetition","IfActive","IfActiveWithRepetition","NoSigSendType","OnChangeAndIfActive","OnChangeAndIfActiveWithRepetition";
BA_DEF_ SG_  "GwSigLatencyTime" INT 0 65536;
BA_DEF_ SG_  "GwSigMissingSourceType" ENUM  "Undef","OldValue","DefaultValue","InitialValue";
BA_DEF_ SG_  "NWM-WakeupAllowed" ENUM  "<n.a.>";
BA_DEF_ SG_  "RoutingFactor" INT 1 1215752192;
BA_DEF_ SG_  "SystemSignalLongSymbol" STRING ;
BA_DEF_REL_ BU_SG_REL_  "GenSigTimeoutTime" INT 0 7000;
BA_DEF_DEF_  "DiagState" "No";
BA_DEF_DEF_  "DiagResponse" "No";
BA_DEF_DEF_  "DiagRequest" "No";
BA_DEF_DEF_  "TpMessage" "No";
BA_DEF_DEF_  "UsrMsgIDSforwardDeviation" 10;
BA_DEF_DEF_  "UsrMsgIDSbackwardDeviation" 100;
BA_DEF_DEF_  "GenMsgCycleTime" 200;
BA_DEF_DEF_  "GenMsgStartDelayTime" 0;
BA_DEF_DEF_  "GenMsgSendType" "NoMsgSendType";
BA_DEF_DEF_  "GenMsgCycleTimeFast" 40;
BA_DEF_DEF_  "GenMsgDelayTime" 20;
BA_DEF_DEF_  "GenMsgILSupport" "Yes";
BA_DEF_DEF_  "GenMsgNrOfRepetition" 3;
BA_DEF_DEF_  "NmMessage" "No";
BA_DEF_DEF_  "NWM-Botschaft" "No";
BA_DEF_DEF_  "TpTxIndex" 0;
BA_DEF_DEF_  "VFrameFormat" "StandardCAN";
BA_DEF_DEF_  "UserSigValidity" "IG";
BA_DEF_DEF_  "TimeoutValue" "";
BA_DEF_DEF_  "UsrSigPurpose" "FN";
BA_DEF_DEF_  "GenSigStartValue" 0;
BA_DEF_DEF_  "NetworkRequest" "No";
BA_DEF_DEF_  "NetworkRequestHoldingTime" 0;
BA_DEF_DEF_  "Description" "";
BA_DEF_DEF_  "Version" "";
BA_DEF_DEF_  "GenSigEnvVarType" "Undef";
BA_DEF_DEF_  "GenSigSendType" "NoSigSendType";
BA_DEF_DEF_  "GwSigLatencyTime" 40;
BA_DEF_DEF_  "GwSigMissingSourceType" "Undef";
BA_DEF_DEF_  "NWM-WakeupAllowed" "<n.a.>";
BA_DEF_DEF_  "RoutingFactor" 1;
BA_DEF_DEF_REL_ "GenSigTimeoutTime" 500;
BA_DEF_DEF_  "SystemSignalLongSymbol" "";
BA_ "GenMsgSendType" BO_ 2244048387 0;
BA_ "GenMsgCycleTime" BO_ 2244048387 100;
BA_ "GenMsgCycleTimeFast" BO_ 2244048387 0;
BA_ "GenMsgNrOfRepetition" BO_ 2244048387 0;
BA_ "VFrameFormat" BO_ 2244048387 1;
BA_ "GenMsgSendType" BO_ 2244048386 0;
BA_ "GenMsgCycleTime" BO_ 2244048386 100;
BA_ "GenMsgCycleTimeFast" BO_ 2244048386 0;
BA_ "GenMsgNrOfRepetition" BO_ 2244048386 0;
BA_ "VFrameFormat" BO_ 2244048386 1;
BA_ "GenMsgSendType" BO_ 2244048385 0;
BA_ "GenMsgCycleTime" BO_ 2244048385 100;
BA_ "GenMsgCycleTimeFast" BO_ 2244048385 0;
BA_ "GenMsgNrOfRepetition" BO_ 2244048385 0;
BA_ "VFrameFormat" BO_ 2244048385 1;
BA_ "GenMsgSendType" BO_ 527 0;
BA_ "GenMsgSendType" BO_ 2244048388 0;
BA_ "GenMsgCycleTime" BO_ 2244048388 100;
BA_ "GenMsgCycleTimeFast" BO_ 2244048388 0;
BA_ "GenMsgNrOfRepetition" BO_ 2244048388 0;
BA_ "VFrameFormat" BO_ 2244048388 1;
BA_ "GenMsgCycleTime" BO_ 1616 0;
BA_ "GenMsgSendType" BO_ 543 0;
BA_ "GenMsgSendType" BO_ 2214658052 0;
BA_ "GenMsgCycleTime" BO_ 2214658052 50;
BA_ "GenMsgCycleTimeFast" BO_ 2214658052 0;
BA_ "GenMsgNrOfRepetition" BO_ 2214658052 0;
BA_ "VFrameFormat" BO_ 2214658052 1;
BA_ "GenMsgSendType" BO_ 2273435649 0;
BA_ "GenMsgCycleTime" BO_ 2273435649 150;
BA_ "GenMsgCycleTimeFast" BO_ 2273435649 0;
BA_ "GenMsgNrOfRepetition" BO_ 2273435649 0;
BA_ "VFrameFormat" BO_ 2273435649 1;
BA_ "GenMsgSendType" BO_ 2273435650 0;
BA_ "GenMsgCycleTime" BO_ 2273435650 150;
BA_ "GenMsgCycleTimeFast" BO_ 2273435650 0;
BA_ "GenMsgNrOfRepetition" BO_ 2273435650 0;
BA_ "VFrameFormat" BO_ 2273435650 1;
BA_ "GenMsgSendType" BO_ 2214658049 0;
BA_ "GenMsgCycleTime" BO_ 2214658049 50;
BA_ "GenMsgCycleTimeFast" BO_ 2214658049 0;
BA_ "GenMsgNrOfRepetition" BO_ 2214658049 0;
BA_ "VFrameFormat" BO_ 2214658049 1;
BA_ "GenMsgSendType" BO_ 614 0;
BA_ "GenMsgCycleTime" BO_ 1578 0;
BA_ "GenMsgILSupport" BO_ 1578 0;
BA_ "TpMessage" BO_ 1578 1;
BA_ "GenMsgDelayTime" BO_ 1578 10;
BA_ "GenMsgCycleTime" BO_ 1579 0;
BA_ "GenMsgILSupport" BO_ 1579 0;
BA_ "TpMessage" BO_ 1579 1;
BA_ "GenMsgDelayTime" BO_ 1579 10;
BA_ "GenMsgSendType" BO_ 2214658051 0;
BA_ "GenMsgCycleTime" BO_ 2214658051 50;
BA_ "GenMsgCycleTimeFast" BO_ 2214658051 0;
BA_ "GenMsgNrOfRepetition" BO_ 2214658051 0;
BA_ "VFrameFormat" BO_ 2214658051 1;
BA_ "GenMsgSendType" BO_ 2214658050 0;
BA_ "GenMsgCycleTime" BO_ 2214658050 50;
BA_ "GenMsgCycleTimeFast" BO_ 2214658050 0;
BA_ "GenMsgNrOfRepetition" BO_ 2214658050 0;
BA_ "VFrameFormat" BO_ 2214658050 1;
BA_ "GenMsgSendType" BO_ 623 0;
BA_ "GenMsgCycleTime" BO_ 639 0;
BA_ "GenMsgCycleTime" BO_ 1584 0;
BA_ "GenMsgSendType" BO_ 577 0;
BA_ "GenMsgSendType" BO_ 578 0;
BA_ "GenMsgSendType" BO_ 2424579841 0;
BA_ "VFrameFormat" BO_ 2424579841 1;
BA_ "GenMsgSendType" BO_ 579 0;
BA_ "GenMsgSendType" BO_ 1546 0;
BA_ "GenMsgCycleTimeFast" BO_ 1546 0;
BA_ "GenMsgNrOfRepetition" BO_ 1546 0;
BA_ "Description" SG_ 2244048387 RCU_AD3_SCC_TqIntrvntnVal "The indicated torque command TQI_ACC is the basic control path to the engine power control. This command has the same priority in the torque-structure than the driver¡¯s demand torque. The maximum value of either TQI_ACC or the driver torque is selected ";
BA_ "UserSigValidity" SG_ 2244048387 RCU_AD3_SCC_TqIntrvntnVal 3;
BA_ "RoutingFactor" SG_ 2244048387 RCU_AD3_SCC_TqIntrvntnVal 5;
BA_ "Version" SG_ 2244048387 RCU_AD3_SCC_TqIntrvntnVal "22.01.00";
BA_ "Description" SG_ 2244048387 RCU_AD3_TCS_TqFlag "Flag indicating positive or negative TCS Intervention. (RCU)";
BA_ "UserSigValidity" SG_ 2244048387 RCU_AD3_TCS_TqFlag 3;
BA_ "RoutingFactor" SG_ 2244048387 RCU_AD3_TCS_TqFlag 5;
BA_ "Version" SG_ 2244048387 RCU_AD3_TCS_TqFlag "22.01.00";
BA_ "Description" SG_ 2244048387 RCU_AD3_TCS_Sta "Information regarding the status of TCS function. (RCU)

If the function has not been coded(fixed) yet, this signal will be transmitted as 0xE.";
BA_ "UserSigValidity" SG_ 2244048387 RCU_AD3_TCS_Sta 3;
BA_ "RoutingFactor" SG_ 2244048387 RCU_AD3_TCS_Sta 5;
BA_ "Version" SG_ 2244048387 RCU_AD3_TCS_Sta "22.01.00";
BA_ "Description" SG_ 2244048387 RCU_AD3_VehAccelVal "The vehicle acceleration ACCEL_REF_ACC displays the feedback signal for the inner acceleration control loop since it is the SCC-internal acceleration command value. In addition this signal is used to calculate the target object acceleration. If the requi";
BA_ "UserSigValidity" SG_ 2244048387 RCU_AD3_VehAccelVal 3;
BA_ "RoutingFactor" SG_ 2244048387 RCU_AD3_VehAccelVal 5;
BA_ "Version" SG_ 2244048387 RCU_AD3_VehAccelVal "22.01.00";
BA_ "Description" SG_ 2244048387 RCU_AD3_MSR_TqFlag "Flag indicating positive or negative MSR Intervention. (RCU)";
BA_ "UserSigValidity" SG_ 2244048387 RCU_AD3_MSR_TqFlag 3;
BA_ "RoutingFactor" SG_ 2244048387 RCU_AD3_MSR_TqFlag 5;
BA_ "Version" SG_ 2244048387 RCU_AD3_MSR_TqFlag "22.01.00";
BA_ "Description" SG_ 2244048387 RCU_AD3_LDM_Sta "Information about RCU-Readiness to perform Dynamic Braking Function (DBF) or Automatic Vehicle Hold (AVH) which is requested by AVH switch.



LDM_STAT (0H)

 - EPB function : EPB is slave

LDM_STAT (1H)

 - EPB function : EPB stand alone";
BA_ "UserSigValidity" SG_ 2244048387 RCU_AD3_LDM_Sta 3;
BA_ "RoutingFactor" SG_ 2244048387 RCU_AD3_LDM_Sta 5;
BA_ "Version" SG_ 2244048387 RCU_AD3_LDM_Sta "22.01.00";
BA_ "Description" SG_ 2244048387 RCU_AD3_ECD_ActvSta "RCU ECD Active signal indicates whether ECD function is active (operating) or not.";
BA_ "UserSigValidity" SG_ 2244048387 RCU_AD3_ECD_ActvSta 3;
BA_ "RoutingFactor" SG_ 2244048387 RCU_AD3_ECD_ActvSta 5;
BA_ "Version" SG_ 2244048387 RCU_AD3_ECD_ActvSta "22.01.00";
BA_ "Description" SG_ 2244048387 RCU_AD3_MSR_FuncReq "Request for an indicated desired engine torque, the combination of signals calls, on the one hand, for a desire for charge reduction (TCS or ESC function), and, on the other hand, for a desire for charge increase (MSR function).



MSR_C_REQ : Identifies";
BA_ "UserSigValidity" SG_ 2244048387 RCU_AD3_MSR_FuncReq 3;
BA_ "RoutingFactor" SG_ 2244048387 RCU_AD3_MSR_FuncReq 5;
BA_ "Version" SG_ 2244048387 RCU_AD3_MSR_FuncReq "22.01.00";
BA_ "Description" SG_ 2244048387 RCU_AD3_TCS_Req "Request for an indicated desired engine torque, the combination of signals calls, on the one hand, for a desire for charge reduction (TCS or ESC function), and, on the other hand, for a desire for charge increase (MSR function).



TCS_REQ : Identifies a";
BA_ "UserSigValidity" SG_ 2244048387 RCU_AD3_TCS_Req 3;
BA_ "RoutingFactor" SG_ 2244048387 RCU_AD3_TCS_Req 5;
BA_ "Version" SG_ 2244048387 RCU_AD3_TCS_Req "22.01.00";
BA_ "Description" SG_ 2244048387 RCU_AD3_TCS_LmpSta "The signal indicates the status of the ¡°TCS/ESC Function/Warning Lamp¡± (RCU)";
BA_ "UserSigValidity" SG_ 2244048387 RCU_AD3_TCS_LmpSta 3;
BA_ "RoutingFactor" SG_ 2244048387 RCU_AD3_TCS_LmpSta 5;
BA_ "Version" SG_ 2244048387 RCU_AD3_TCS_LmpSta "22.01.00";
BA_ "Description" SG_ 2244048387 RCU_AD3_SCC_TqReq "When it is set, the signal indicates that RCU requests engine torque control for SCC. When the signal is set, EMS should not conduct fuel-cut off control unless it is required to prevent the damage of the engine and the related components.";
BA_ "UserSigValidity" SG_ 2244048387 RCU_AD3_SCC_TqReq 3;
BA_ "RoutingFactor" SG_ 2244048387 RCU_AD3_SCC_TqReq 5;
BA_ "Version" SG_ 2244048387 RCU_AD3_SCC_TqReq "22.01.00";
BA_ "Description" SG_ 2244048387 RCU_AD3_StdStillVal "If an RCU/ESC uses active wheel speed sensors, wheel speeds down to 0 Km/h can be measured. And at 0 Km/h a StandStill flag is set in the RCU/ESC. This signal is used in the offset determination of the yaw rate and shall indicate that the vehicle has com";
BA_ "UserSigValidity" SG_ 2244048387 RCU_AD3_StdStillVal 3;
BA_ "RoutingFactor" SG_ 2244048387 RCU_AD3_StdStillVal 5;
BA_ "Version" SG_ 2244048387 RCU_AD3_StdStillVal "22.01.00";
BA_ "Description" SG_ 2244048387 RCU_AD3_SCC_ReqLimSta "Due to limitaion of the actuators the acceleration or deceleration request from SCC can not be processed or only partly. 



Examples:

1. SCC is requesting more acceleration than the engine can deliver.

2. SCC is requesting deceleration on a low ¥ì sur";
BA_ "UserSigValidity" SG_ 2244048387 RCU_AD3_SCC_ReqLimSta 3;
BA_ "RoutingFactor" SG_ 2244048387 RCU_AD3_SCC_ReqLimSta 5;
BA_ "Version" SG_ 2244048387 RCU_AD3_SCC_ReqLimSta "22.01.00";
BA_ "Description" SG_ 2244048387 RCU_AD3_SCC_OptTyp "This value is used for SCC is equipped or not.

Do not recognize 0x3(Not Coded) as failure.";
BA_ "UserSigValidity" SG_ 2244048387 RCU_AD3_SCC_OptTyp 3;
BA_ "RoutingFactor" SG_ 2244048387 RCU_AD3_SCC_OptTyp 5;
BA_ "Version" SG_ 2244048387 RCU_AD3_SCC_OptTyp "22.01.00";
BA_ "Description" SG_ 2244048387 RCU_AD3_SCC_EnblReq "This signal is set by the safety logic in the TCS/ESC. The safety logic shall monitor the following:

1. A temporary failure in the vehicle does not allow SCC (Brakes are overheated, etc¡¦). 

SCC is disabled reversible.

2. SCC communication failure (ti";
BA_ "UserSigValidity" SG_ 2244048387 RCU_AD3_SCC_EnblReq 3;
BA_ "RoutingFactor" SG_ 2244048387 RCU_AD3_SCC_EnblReq 5;
BA_ "Version" SG_ 2244048387 RCU_AD3_SCC_EnblReq "22.01.00";
BA_ "Description" SG_ 2244048387 RCU_AD3_FCA_EquipSta "FCA Equipment Status

Do not recognize 0x3(Not Coded) as failure.";
BA_ "UserSigValidity" SG_ 2244048387 RCU_AD3_FCA_EquipSta 3;
BA_ "RoutingFactor" SG_ 2244048387 RCU_AD3_FCA_EquipSta 5;
BA_ "Version" SG_ 2244048387 RCU_AD3_FCA_EquipSta "22.01.00";
BA_ "Description" SG_ 2244048387 RCU_AD3_FCA_ActvSta "This signal specifies the status of control for FCA control request flag.";
BA_ "UserSigValidity" SG_ 2244048387 RCU_AD3_FCA_ActvSta 3;
BA_ "RoutingFactor" SG_ 2244048387 RCU_AD3_FCA_ActvSta 5;
BA_ "Version" SG_ 2244048387 RCU_AD3_FCA_ActvSta "22.01.00";
BA_ "Description" SG_ 2244048387 RCU_AD3_DclEnblReq "This signal enables the deceleration control to accept command values axvCv from SCC. This flag is complementary to the ACC_REQ flag if SCC is in active mode.";
BA_ "UserSigValidity" SG_ 2244048387 RCU_AD3_DclEnblReq 3;
BA_ "RoutingFactor" SG_ 2244048387 RCU_AD3_DclEnblReq 5;
BA_ "Version" SG_ 2244048387 RCU_AD3_DclEnblReq "22.01.00";
BA_ "Description" SG_ 2244048387 RCU_AD3_DBS_ActvSta "This signal specifies the status of control for DBS flag.";
BA_ "UserSigValidity" SG_ 2244048387 RCU_AD3_DBS_ActvSta 3;
BA_ "RoutingFactor" SG_ 2244048387 RCU_AD3_DBS_ActvSta 5;
BA_ "Version" SG_ 2244048387 RCU_AD3_DBS_ActvSta "22.01.00";
BA_ "Description" SG_ 2244048387 RCU_AD3_AccelBasisVal "This value is used to initialize the acceleration control when SCC is engaged or after driver override. (RCU)";
BA_ "UserSigValidity" SG_ 2244048387 RCU_AD3_AccelBasisVal 3;
BA_ "RoutingFactor" SG_ 2244048387 RCU_AD3_AccelBasisVal 5;
BA_ "Version" SG_ 2244048387 RCU_AD3_AccelBasisVal "22.01.00";
BA_ "UserSigValidity" SG_ 2244048386 RCU_AD3_Wss2FlFltSta 3;
BA_ "RoutingFactor" SG_ 2244048386 RCU_AD3_Wss2FlFltSta 5;
BA_ "Version" SG_ 2244048386 RCU_AD3_Wss2FlFltSta "22.01.00";
BA_ "Description" SG_ 2244048386 RCU_AD3_DiagSta "Information regarding the ¡°diagnostic mode¡± indication. (RCU)";
BA_ "UserSigValidity" SG_ 2244048386 RCU_AD3_DiagSta 3;
BA_ "RoutingFactor" SG_ 2244048386 RCU_AD3_DiagSta 5;
BA_ "Version" SG_ 2244048386 RCU_AD3_DiagSta "22.01.00";
BA_ "UserSigValidity" SG_ 2244048386 RCU_AD3_operation 3;
BA_ "RoutingFactor" SG_ 2244048386 RCU_AD3_operation 5;
BA_ "Version" SG_ 2244048386 RCU_AD3_operation "22.01.00";
BA_ "Description" SG_ 2244048386 RCU_AD3_PrsrValVldSta "This signal indicates validity of 'RCU_PrsrVal' signal.";
BA_ "GenSigStartValue" SG_ 2244048386 RCU_AD3_PrsrValVldSta 1;
BA_ "UserSigValidity" SG_ 2244048386 RCU_AD3_PrsrValVldSta 3;
BA_ "RoutingFactor" SG_ 2244048386 RCU_AD3_PrsrValVldSta 5;
BA_ "Version" SG_ 2244048386 RCU_AD3_PrsrValVldSta "22.04.01";
BA_ "Description" SG_ 2244048386 RCU_AD3_PrsrVal "This signal indicates RCU front circuit pressure Value.";
BA_ "UserSigValidity" SG_ 2244048386 RCU_AD3_PrsrVal 3;
BA_ "RoutingFactor" SG_ 2244048386 RCU_AD3_PrsrVal 5;
BA_ "Version" SG_ 2244048386 RCU_AD3_PrsrVal "22.04.01";
BA_ "UserSigValidity" SG_ 2244048386 RCU_AD3_Wss2FrFltSta 3;
BA_ "RoutingFactor" SG_ 2244048386 RCU_AD3_Wss2FrFltSta 5;
BA_ "Version" SG_ 2244048386 RCU_AD3_Wss2FrFltSta "22.01.00";
BA_ "Description" SG_ 2244048386 RCU_AD3_ABS_DfctvSta "Information regarding the ABS 'defective' indication. (RCU)";
BA_ "UserSigValidity" SG_ 2244048386 RCU_AD3_ABS_DfctvSta 3;
BA_ "RoutingFactor" SG_ 2244048386 RCU_AD3_ABS_DfctvSta 5;
BA_ "Version" SG_ 2244048386 RCU_AD3_ABS_DfctvSta "22.01.00";
BA_ "Description" SG_ 2244048386 RCU_AD3_ABS_ActvSta "information on ABS Active signal. (RCU)";
BA_ "UserSigValidity" SG_ 2244048386 RCU_AD3_ABS_ActvSta 3;
BA_ "RoutingFactor" SG_ 2244048386 RCU_AD3_ABS_ActvSta 5;
BA_ "Version" SG_ 2244048386 RCU_AD3_ABS_ActvSta "22.01.00";
BA_ "Description" SG_ 2244048386 RCU_AD3_BBC_DfctvSta "Information regarding the BBC 'defective' indication. (RCU)";
BA_ "UserSigValidity" SG_ 2244048386 RCU_AD3_BBC_DfctvSta 3;
BA_ "RoutingFactor" SG_ 2244048386 RCU_AD3_BBC_DfctvSta 5;
BA_ "Version" SG_ 2244048386 RCU_AD3_BBC_DfctvSta "22.01.00";
BA_ "Description" SG_ 2244048386 RCU_AD3_BBC_ActvSta "information on BBC Active signal. (RCU)";
BA_ "UserSigValidity" SG_ 2244048386 RCU_AD3_BBC_ActvSta 3;
BA_ "RoutingFactor" SG_ 2244048386 RCU_AD3_BBC_ActvSta 5;
BA_ "Version" SG_ 2244048386 RCU_AD3_BBC_ActvSta "22.01.00";
BA_ "UserSigValidity" SG_ 2244048386 RCU_AD3_Wss2RlFltSta 3;
BA_ "RoutingFactor" SG_ 2244048386 RCU_AD3_Wss2RlFltSta 5;
BA_ "Version" SG_ 2244048386 RCU_AD3_Wss2RlFltSta "22.01.00";
BA_ "Description" SG_ 2244048386 RCU_AD3_BrkLtActSta "Flag which activates the illumination of the brake lights during automatic braking. (RCU)";
BA_ "UserSigValidity" SG_ 2244048386 RCU_AD3_BrkLtActSta 0;
BA_ "RoutingFactor" SG_ 2244048386 RCU_AD3_BrkLtActSta 5;
BA_ "Version" SG_ 2244048386 RCU_AD3_BrkLtActSta "22.01.00";
BA_ "Description" SG_ 2244048386 RCU_AD3_DrvOvrdSta "This signal indicates that acceleration or deceleration value of driver¡¯s requirement is greater than SCC setting value. (RCU)";
BA_ "UserSigValidity" SG_ 2244048386 RCU_AD3_DrvOvrdSta 3;
BA_ "RoutingFactor" SG_ 2244048386 RCU_AD3_DrvOvrdSta 5;
BA_ "Version" SG_ 2244048386 RCU_AD3_DrvOvrdSta "22.01.00";
BA_ "Description" SG_ 2244048386 RCU_AD3_PrkBrkActvSta "This signal indicates whether the parking brake is activated or not. (RCU)";
BA_ "UserSigValidity" SG_ 2244048386 RCU_AD3_PrkBrkActvSta 3;
BA_ "RoutingFactor" SG_ 2244048386 RCU_AD3_PrkBrkActvSta 5;
BA_ "Version" SG_ 2244048386 RCU_AD3_PrkBrkActvSta "22.01.00";
BA_ "Description" SG_ 2244048386 RCU_AD3_FCA_AvlblSta "This signal indicates state signal from RCU to FCA which tells if RCU is 'Available', 'Temporarily not available', 'Permanently not available' or 'FCA Communication Error'.";
BA_ "UserSigValidity" SG_ 2244048386 RCU_AD3_FCA_AvlblSta 3;
BA_ "RoutingFactor" SG_ 2244048386 RCU_AD3_FCA_AvlblSta 5;
BA_ "Version" SG_ 2244048386 RCU_AD3_FCA_AvlblSta "22.01.00";
BA_ "Description" SG_ 2244048386 RCU_AD3_MSR_TqIntrvntnVal "Request for an indicated desired engine torque, the combination of signals calls, on the one hand, for a desire for charge reduction (TCS or ESC function), and, on the other hand, for a desire for charge increase (MSR function).



TQI_MSR : The torque i";
BA_ "UserSigValidity" SG_ 2244048386 RCU_AD3_MSR_TqIntrvntnVal 3;
BA_ "RoutingFactor" SG_ 2244048386 RCU_AD3_MSR_TqIntrvntnVal 5;
BA_ "Version" SG_ 2244048386 RCU_AD3_MSR_TqIntrvntnVal "22.01.00";
BA_ "Description" SG_ 2244048386 RCU_AD3_TCS_TqIntrvntnVal "Request for an indicated desired engine torque, the combination of signals calls, on the one hand, for a desire for charge reduction (TCS or ESC function), and, on the other hand, for a desire for charge increase (MSR function).



TQI_TCS : Torque reduc";
BA_ "GenSigStartValue" SG_ 2244048386 RCU_AD3_TCS_TqIntrvntnVal 255;
BA_ "UserSigValidity" SG_ 2244048386 RCU_AD3_TCS_TqIntrvntnVal 3;
BA_ "RoutingFactor" SG_ 2244048386 RCU_AD3_TCS_TqIntrvntnVal 5;
BA_ "Version" SG_ 2244048386 RCU_AD3_TCS_TqIntrvntnVal "22.01.00";
BA_ "UserSigValidity" SG_ 2244048386 RCU_AD3_Wss2RrFltSta 3;
BA_ "RoutingFactor" SG_ 2244048386 RCU_AD3_Wss2RrFltSta 5;
BA_ "Version" SG_ 2244048386 RCU_AD3_Wss2RrFltSta "22.01.00";
BA_ "Description" SG_ 2244048386 RCU_AD3_SrvLmpDis "The signal indicates the status of the ¡°RCU Service lamp¡±";
BA_ "UserSigValidity" SG_ 2244048386 RCU_AD3_SrvLmpDis 3;
BA_ "RoutingFactor" SG_ 2244048386 RCU_AD3_SrvLmpDis 5;
BA_ "Version" SG_ 2244048386 RCU_AD3_SrvLmpDis "22.04.01";
BA_ "Description" SG_ 2244048385 RCU_Crc3Val "The data area for CRC calculation is based on the data length (DLC) of the message DB.

The CRC shall be calculated over the entire data block (excluding the CRC bytes) including the user data, alive counter and Data ID



- CRC Polynomial (0x1021) , Ini";
BA_ "GenSigStartValue" SG_ 2244048385 RCU_Crc3Val 65535;
BA_ "UserSigValidity" SG_ 2244048385 RCU_Crc3Val 3;
BA_ "RoutingFactor" SG_ 2244048385 RCU_Crc3Val 5;
BA_ "Version" SG_ 2244048385 RCU_Crc3Val "22.01.00";
BA_ "Description" SG_ 2244048385 RCU_AlvCnt3Val "For the first transmission request for a data element the counter shall be initialized with 0 and shall be incremented by 1 for every subsequent send request. 

When the counter reaches the maximum value(0xFF), then it shall restart with 0 for the next s";
BA_ "UserSigValidity" SG_ 2244048385 RCU_AlvCnt3Val 3;
BA_ "RoutingFactor" SG_ 2244048385 RCU_AlvCnt3Val 5;
BA_ "Version" SG_ 2244048385 RCU_AlvCnt3Val "22.01.00";
BA_ "Description" SG_ 2244048385 RCU_HDP_FltMonSta "This signal is the result of the RCU monitoring the state of the HDP controller (Main/Sub).";
BA_ "UserSigValidity" SG_ 2244048385 RCU_HDP_FltMonSta 3;
BA_ "RoutingFactor" SG_ 2244048385 RCU_HDP_FltMonSta 5;
BA_ "Version" SG_ 2244048385 RCU_HDP_FltMonSta "22.01.00";
BA_ "Description" SG_ 2244048385 RCU_HDP_EgSta "This signal is the information which of the HDP controllers (Main/Sub) the IEB (ESC)/RCU is engaged.";
BA_ "UserSigValidity" SG_ 2244048385 RCU_HDP_EgSta 0;
BA_ "RoutingFactor" SG_ 2244048385 RCU_HDP_EgSta 5;
BA_ "Version" SG_ 2244048385 RCU_HDP_EgSta "22.05.03";
BA_ "Description" SG_ 2244048385 RCU_HDP_EnblReq "This signal is a fault state of the RCU for the HDP function.";
BA_ "UserSigValidity" SG_ 2244048385 RCU_HDP_EnblReq 3;
BA_ "RoutingFactor" SG_ 2244048385 RCU_HDP_EnblReq 5;
BA_ "Version" SG_ 2244048385 RCU_HDP_EnblReq "22.01.00";
BA_ "UserSigValidity" SG_ 2244048385 RCU_AD3_RCUFltSta 3;
BA_ "RoutingFactor" SG_ 2244048385 RCU_AD3_RCUFltSta 5;
BA_ "Version" SG_ 2244048385 RCU_AD3_RCUFltSta "22.01.00";
BA_ "Description" SG_ 2244048385 RCU_AD3_AWD_FastOpnCrdnShftCltch "Interface signal between RCU and 4WD, demands fast opening or torque limit of the 4WD cardan shaft clutch.";
BA_ "UserSigValidity" SG_ 2244048385 RCU_AD3_AWD_FastOpnCrdnShftCltch 3;
BA_ "RoutingFactor" SG_ 2244048385 RCU_AD3_AWD_FastOpnCrdnShftCltch 5;
BA_ "Version" SG_ 2244048385 RCU_AD3_AWD_FastOpnCrdnShftCltch "22.01.00";
BA_ "SystemSignalLongSymbol" SG_ 2244048385 RCU_AD3_AWD_FastOpnCrdnShftCltch "RCU_AD3_AWD_FastOpnCrdnShftCltchReq";
BA_ "Description" SG_ 2244048385 RCU_AD3_StrkDpthmmVal "The signal indicates the depth of brake pedal (RCU Pedal - PTS2)";
BA_ "UserSigValidity" SG_ 2244048385 RCU_AD3_StrkDpthmmVal 3;
BA_ "RoutingFactor" SG_ 2244048385 RCU_AD3_StrkDpthmmVal 5;
BA_ "Version" SG_ 2244048385 RCU_AD3_StrkDpthmmVal "22.04.01";
BA_ "Description" SG_ 2244048385 RCU_AD3_PdlTrvlSnsrValVldSta "Information regarding the pedal travel sensor value validity status (RCU Pedal - PTS2)";
BA_ "UserSigValidity" SG_ 2244048385 RCU_AD3_PdlTrvlSnsrValVldSta 3;
BA_ "RoutingFactor" SG_ 2244048385 RCU_AD3_PdlTrvlSnsrValVldSta 5;
BA_ "Version" SG_ 2244048385 RCU_AD3_PdlTrvlSnsrValVldSta "22.04.01";
BA_ "Description" SG_ 2244048385 RCU_AD3_PdlCalibSta "Information regarding the pedal travel sensor¡¯s calibration status (RCU Pedal - PTS2)";
BA_ "UserSigValidity" SG_ 2244048385 RCU_AD3_PdlCalibSta 3;
BA_ "RoutingFactor" SG_ 2244048385 RCU_AD3_PdlCalibSta 5;
BA_ "Version" SG_ 2244048385 RCU_AD3_PdlCalibSta "22.04.01";
BA_ "Description" SG_ 2244048385 RCU_AD3_WSSmode "This signal indicates RCU support WSS or Not ( not each wss validity )";
BA_ "UserSigValidity" SG_ 2244048385 RCU_AD3_WSSmode 3;
BA_ "RoutingFactor" SG_ 2244048385 RCU_AD3_WSSmode 5;
BA_ "Version" SG_ 2244048385 RCU_AD3_WSSmode "22.01.00";
BA_ "Description" SG_ 527 ATS_DrvStRseFwdBtn "¿îÀü¼® ¸ð´ÏÅÍ °¢µµ Á¶Àý Àü¹æ ÀÌµ¿";
BA_ "GenSigSendType" SG_ 527 ATS_DrvStRseFwdBtn 4;
BA_ "UserSigValidity" SG_ 527 ATS_DrvStRseFwdBtn 3;
BA_ "NetworkRequest" SG_ 527 ATS_DrvStRseFwdBtn 0;
BA_ "NetworkRequestHoldingTime" SG_ 527 ATS_DrvStRseFwdBtn 5000;
BA_ "Version" SG_ 527 ATS_DrvStRseFwdBtn "19.09.02";
BA_ "Description" SG_ 527 ATS_DrvStRseBwdBtn "¿îÀü¼® ¸ð´ÏÅÍ °¢µµ Á¶Àý ÈÄ¹æ ÀÌµ¿";
BA_ "GenSigSendType" SG_ 527 ATS_DrvStRseBwdBtn 4;
BA_ "UserSigValidity" SG_ 527 ATS_DrvStRseBwdBtn 3;
BA_ "NetworkRequest" SG_ 527 ATS_DrvStRseBwdBtn 0;
BA_ "NetworkRequestHoldingTime" SG_ 527 ATS_DrvStRseBwdBtn 5000;
BA_ "Version" SG_ 527 ATS_DrvStRseBwdBtn "19.09.02";
BA_ "Description" SG_ 527 ATS_RRRestModBtn "ÈÄ¼® RH REST ¸ðµå ÀÛµ¿";
BA_ "GenSigSendType" SG_ 527 ATS_RRRestModBtn 4;
BA_ "UserSigValidity" SG_ 527 ATS_RRRestModBtn 3;
BA_ "NetworkRequest" SG_ 527 ATS_RRRestModBtn 0;
BA_ "NetworkRequestHoldingTime" SG_ 527 ATS_RRRestModBtn 5000;
BA_ "Version" SG_ 527 ATS_RRRestModBtn "19.09.02";
BA_ "Description" SG_ 527 ATS_RRResetModBtn "ÈÄ¼® RH RETURN ¸ðµå ÀÛµ¿";
BA_ "GenSigSendType" SG_ 527 ATS_RRResetModBtn 4;
BA_ "UserSigValidity" SG_ 527 ATS_RRResetModBtn 3;
BA_ "NetworkRequest" SG_ 527 ATS_RRResetModBtn 0;
BA_ "NetworkRequestHoldingTime" SG_ 527 ATS_RRResetModBtn 5000;
BA_ "Version" SG_ 527 ATS_RRResetModBtn "19.09.02";
BA_ "Description" SG_ 527 ATS_RRAvWtcModBtn "ÈÄ¼® RH AVN ¸ðµå ÀÛµ¿";
BA_ "GenSigSendType" SG_ 527 ATS_RRAvWtcModBtn 4;
BA_ "UserSigValidity" SG_ 527 ATS_RRAvWtcModBtn 3;
BA_ "NetworkRequest" SG_ 527 ATS_RRAvWtcModBtn 0;
BA_ "NetworkRequestHoldingTime" SG_ 527 ATS_RRAvWtcModBtn 5000;
BA_ "Version" SG_ 527 ATS_RRAvWtcModBtn "19.09.02";
BA_ "Description" SG_ 527 ATS_RRReadingModBtn "ÈÄ¼® RH READING ¸ðµå ÀÛµ¿";
BA_ "GenSigSendType" SG_ 527 ATS_RRReadingModBtn 4;
BA_ "UserSigValidity" SG_ 527 ATS_RRReadingModBtn 3;
BA_ "NetworkRequest" SG_ 527 ATS_RRReadingModBtn 0;
BA_ "NetworkRequestHoldingTime" SG_ 527 ATS_RRReadingModBtn 5000;
BA_ "Version" SG_ 527 ATS_RRReadingModBtn "19.09.02";
BA_ "Description" SG_ 527 ATS_RLRestModBtn "ÈÄ¼® LH REST ¸ðµå ÀÛµ¿";
BA_ "GenSigSendType" SG_ 527 ATS_RLRestModBtn 4;
BA_ "UserSigValidity" SG_ 527 ATS_RLRestModBtn 3;
BA_ "NetworkRequest" SG_ 527 ATS_RLRestModBtn 0;
BA_ "NetworkRequestHoldingTime" SG_ 527 ATS_RLRestModBtn 5000;
BA_ "Version" SG_ 527 ATS_RLRestModBtn "19.09.02";
BA_ "Description" SG_ 527 ATS_RLResetModBtn "ÈÄ¼® LH RETURN ¸ðµå ÀÛµ¿";
BA_ "GenSigSendType" SG_ 527 ATS_RLResetModBtn 4;
BA_ "UserSigValidity" SG_ 527 ATS_RLResetModBtn 3;
BA_ "NetworkRequest" SG_ 527 ATS_RLResetModBtn 0;
BA_ "NetworkRequestHoldingTime" SG_ 527 ATS_RLResetModBtn 5000;
BA_ "Version" SG_ 527 ATS_RLResetModBtn "19.09.02";
BA_ "Description" SG_ 2244048388 RCU_HDPSpprtSWVer "Software version of IEB/RCU that supports HDP function";
BA_ "UserSigValidity" SG_ 2244048388 RCU_HDPSpprtSWVer 3;
BA_ "RoutingFactor" SG_ 2244048388 RCU_HDPSpprtSWVer 5;
BA_ "Version" SG_ 2244048388 RCU_HDPSpprtSWVer "22.01.00";
BA_ "Description" SG_ 2244048388 RCU_AD3_ABS_WrngLmpSta "The signal indicates the status of the RCU ¡°ABS Warning lamp¡±";
BA_ "UserSigValidity" SG_ 2244048388 RCU_AD3_ABS_WrngLmpSta 3;
BA_ "RoutingFactor" SG_ 2244048388 RCU_AD3_ABS_WrngLmpSta 5;
BA_ "Version" SG_ 2244048388 RCU_AD3_ABS_WrngLmpSta "22.04.01";
BA_ "Description" SG_ 2244048388 RCU_AD3_ESC_Sta "Information regarding the status of RCU ESC function.



If the function has not been coded(fixed) yet, this signal will be transmitted as 0xE.



If the vehicle has been applied only ABS(without ESC), this signal will be fixed as 0x0.";
BA_ "UserSigValidity" SG_ 2244048388 RCU_AD3_ESC_Sta 3;
BA_ "RoutingFactor" SG_ 2244048388 RCU_AD3_ESC_Sta 5;
BA_ "Version" SG_ 2244048388 RCU_AD3_ESC_Sta "22.04.01";
BA_ "GenSigSendType" SG_ 1616 MKBD_IllumiState 4;
BA_ "GenSigStartValue" SG_ 1616 MKBD_IllumiState 3;
BA_ "UserSigValidity" SG_ 1616 MKBD_IllumiState 1;
BA_ "Version" SG_ 1616 MKBD_IllumiState "20.04.02";
BA_ "Description" SG_ 1616 MKBD_SeatKeySet "The signal for transmitting Seat Key inputs from MKBD to Seat ECU

Release : 0x0 / Press : 0x1";
BA_ "GenSigSendType" SG_ 1616 MKBD_SeatKeySet 4;
BA_ "GenSigStartValue" SG_ 1616 MKBD_SeatKeySet 3;
BA_ "UserSigValidity" SG_ 1616 MKBD_SeatKeySet 3;
BA_ "Version" SG_ 1616 MKBD_SeatKeySet "20.06.07";
BA_ "Description" SG_ 543 ATS_AstStSldFwdBtn "µ¿½Â¼® ½½¶óÀÌµù Àü¹æ ÀÌµ¿ (¿öÅ©ÀÎ ÀÛµ¿)";
BA_ "GenSigSendType" SG_ 543 ATS_AstStSldFwdBtn 4;
BA_ "UserSigValidity" SG_ 543 ATS_AstStSldFwdBtn 3;
BA_ "NetworkRequest" SG_ 543 ATS_AstStSldFwdBtn 0;
BA_ "NetworkRequestHoldingTime" SG_ 543 ATS_AstStSldFwdBtn 5000;
BA_ "Version" SG_ 543 ATS_AstStSldFwdBtn "19.09.02";
BA_ "Description" SG_ 543 ATS_AstStSldBwdBtn "µ¿½Â¼® ½½¶óÀÌµù ÈÄ¹æ ÀÌµ¿ (¿öÅ©ÀÎ ÀÛµ¿)";
BA_ "GenSigSendType" SG_ 543 ATS_AstStSldBwdBtn 4;
BA_ "UserSigValidity" SG_ 543 ATS_AstStSldBwdBtn 3;
BA_ "NetworkRequest" SG_ 543 ATS_AstStSldBwdBtn 0;
BA_ "NetworkRequestHoldingTime" SG_ 543 ATS_AstStSldBwdBtn 5000;
BA_ "Version" SG_ 543 ATS_AstStSldBwdBtn "19.09.02";
BA_ "Description" SG_ 543 ATS_AstStRclFwdBtn "µ¿½Â¼® ¸®Å¬¶óÀÌ´× Àü¹æ ÀÌµ¿ (¿öÅ©ÀÎ ÀÛµ¿)";
BA_ "GenSigSendType" SG_ 543 ATS_AstStRclFwdBtn 4;
BA_ "UserSigValidity" SG_ 543 ATS_AstStRclFwdBtn 3;
BA_ "NetworkRequest" SG_ 543 ATS_AstStRclFwdBtn 0;
BA_ "NetworkRequestHoldingTime" SG_ 543 ATS_AstStRclFwdBtn 5000;
BA_ "Version" SG_ 543 ATS_AstStRclFwdBtn "19.09.02";
BA_ "Description" SG_ 543 ATS_AstStRclBwdBtn "µ¿½Â¼® ¸®Å¬¶óÀÌ´× ÈÄ¹æ ÀÌµ¿ (¿öÅ©ÀÎ ÀÛµ¿)";
BA_ "GenSigSendType" SG_ 543 ATS_AstStRclBwdBtn 4;
BA_ "UserSigValidity" SG_ 543 ATS_AstStRclBwdBtn 3;
BA_ "NetworkRequest" SG_ 543 ATS_AstStRclBwdBtn 0;
BA_ "NetworkRequestHoldingTime" SG_ 543 ATS_AstStRclBwdBtn 5000;
BA_ "Version" SG_ 543 ATS_AstStRclBwdBtn "19.09.02";
BA_ "Description" SG_ 543 ATS_AstStHgtUpBtn "µ¿½Â¼® ÇÏÀÌÆ® ¾÷ ÀÌµ¿ (¿öÅ©ÀÎ ÀÛµ¿)";
BA_ "GenSigSendType" SG_ 543 ATS_AstStHgtUpBtn 4;
BA_ "UserSigValidity" SG_ 543 ATS_AstStHgtUpBtn 3;
BA_ "NetworkRequest" SG_ 543 ATS_AstStHgtUpBtn 0;
BA_ "NetworkRequestHoldingTime" SG_ 543 ATS_AstStHgtUpBtn 5000;
BA_ "Version" SG_ 543 ATS_AstStHgtUpBtn "19.09.02";
BA_ "Description" SG_ 543 ATS_AstStHgtDnBtn "µ¿½Â¼® ÇÏÀÌÆ® ´Ù¿î ÀÌµ¿ (¿öÅ©ÀÎ ÀÛµ¿)";
BA_ "GenSigSendType" SG_ 543 ATS_AstStHgtDnBtn 4;
BA_ "UserSigValidity" SG_ 543 ATS_AstStHgtDnBtn 3;
BA_ "NetworkRequest" SG_ 543 ATS_AstStHgtDnBtn 0;
BA_ "NetworkRequestHoldingTime" SG_ 543 ATS_AstStHgtDnBtn 5000;
BA_ "Version" SG_ 543 ATS_AstStHgtDnBtn "19.09.02";
BA_ "Description" SG_ 543 ATS_AstStHRestUpBtn "µ¿½Â¼® Çìµå·¹½ºÆ® ¾÷ ÀÌµ¿ (¿öÅ©ÀÎ ÀÛµ¿)";
BA_ "GenSigSendType" SG_ 543 ATS_AstStHRestUpBtn 4;
BA_ "UserSigValidity" SG_ 543 ATS_AstStHRestUpBtn 3;
BA_ "NetworkRequest" SG_ 543 ATS_AstStHRestUpBtn 0;
BA_ "NetworkRequestHoldingTime" SG_ 543 ATS_AstStHRestUpBtn 5000;
BA_ "Version" SG_ 543 ATS_AstStHRestUpBtn "19.09.02";
BA_ "Description" SG_ 543 ATS_AstStHRestDnBtn "µ¿½Â¼® Çìµå·¹½ºÆ® ´Ù¿î ÀÌµ¿ (¿öÅ©ÀÎ ÀÛµ¿)";
BA_ "GenSigSendType" SG_ 543 ATS_AstStHRestDnBtn 4;
BA_ "UserSigValidity" SG_ 543 ATS_AstStHRestDnBtn 3;
BA_ "NetworkRequest" SG_ 543 ATS_AstStHRestDnBtn 0;
BA_ "NetworkRequestHoldingTime" SG_ 543 ATS_AstStHRestDnBtn 5000;
BA_ "Version" SG_ 543 ATS_AstStHRestDnBtn "19.09.02";
BA_ "Description" SG_ 543 ATS_AstStHRestFwdBtn "µ¿½Â¼® Çìµå·¹½ºÆ® Àü¹æ ÀÌµ¿ (¿öÅ©ÀÎ ÀÛµ¿)";
BA_ "GenSigSendType" SG_ 543 ATS_AstStHRestFwdBtn 4;
BA_ "UserSigValidity" SG_ 543 ATS_AstStHRestFwdBtn 3;
BA_ "NetworkRequest" SG_ 543 ATS_AstStHRestFwdBtn 0;
BA_ "NetworkRequestHoldingTime" SG_ 543 ATS_AstStHRestFwdBtn 5000;
BA_ "Version" SG_ 543 ATS_AstStHRestFwdBtn "19.09.02";
BA_ "Description" SG_ 543 ATS_AstStHRestBwdBtn "µ¿½Â¼® Çìµå·¹½ºÆ® ÈÄ¹æ ÀÌµ¿ (¿öÅ©ÀÎ ÀÛµ¿)";
BA_ "GenSigSendType" SG_ 543 ATS_AstStHRestBwdBtn 4;
BA_ "UserSigValidity" SG_ 543 ATS_AstStHRestBwdBtn 3;
BA_ "NetworkRequest" SG_ 543 ATS_AstStHRestBwdBtn 0;
BA_ "NetworkRequestHoldingTime" SG_ 543 ATS_AstStHRestBwdBtn 5000;
BA_ "Version" SG_ 543 ATS_AstStHRestBwdBtn "19.09.02";
BA_ "Description" SG_ 543 ATS_AstStHRestFldBtn "µ¿½Â¼® Çìµå·¹½ºÆ® Æúµù ÀÌµ¿ (¿öÅ©ÀÎ ÀÛµ¿)";
BA_ "GenSigSendType" SG_ 543 ATS_AstStHRestFldBtn 4;
BA_ "UserSigValidity" SG_ 543 ATS_AstStHRestFldBtn 3;
BA_ "NetworkRequest" SG_ 543 ATS_AstStHRestFldBtn 0;
BA_ "NetworkRequestHoldingTime" SG_ 543 ATS_AstStHRestFldBtn 5000;
BA_ "Version" SG_ 543 ATS_AstStHRestFldBtn "19.09.02";
BA_ "Description" SG_ 543 ATS_AstStHRestUnFldBtn "µ¿½Â¼® Çìµå·¹½ºÆ® ¾ðÆúµù ÀÌµ¿ (¿öÅ©ÀÎ ÀÛµ¿)";
BA_ "GenSigSendType" SG_ 543 ATS_AstStHRestUnFldBtn 4;
BA_ "UserSigValidity" SG_ 543 ATS_AstStHRestUnFldBtn 3;
BA_ "NetworkRequest" SG_ 543 ATS_AstStHRestUnFldBtn 0;
BA_ "NetworkRequestHoldingTime" SG_ 543 ATS_AstStHRestUnFldBtn 5000;
BA_ "Version" SG_ 543 ATS_AstStHRestUnFldBtn "19.09.02";
BA_ "Description" SG_ 543 ATS_AstStRseFwdBtn "µ¿½Â¼® ¸ð´ÏÅÍ °¢µµ Á¶Àý Àü¹æ ÀÌµ¿";
BA_ "GenSigSendType" SG_ 543 ATS_AstStRseFwdBtn 4;
BA_ "UserSigValidity" SG_ 543 ATS_AstStRseFwdBtn 3;
BA_ "NetworkRequest" SG_ 543 ATS_AstStRseFwdBtn 0;
BA_ "NetworkRequestHoldingTime" SG_ 543 ATS_AstStRseFwdBtn 5000;
BA_ "Version" SG_ 543 ATS_AstStRseFwdBtn "19.09.02";
BA_ "Description" SG_ 543 ATS_AstStRseBwdBtn "µ¿½Â¼® ¸ð´ÏÅÍ °¢µµ Á¶Àý ÈÄ¹æ ÀÌµ¿";
BA_ "GenSigSendType" SG_ 543 ATS_AstStRseBwdBtn 4;
BA_ "UserSigValidity" SG_ 543 ATS_AstStRseBwdBtn 3;
BA_ "NetworkRequest" SG_ 543 ATS_AstStRseBwdBtn 0;
BA_ "NetworkRequestHoldingTime" SG_ 543 ATS_AstStRseBwdBtn 5000;
BA_ "Version" SG_ 543 ATS_AstStRseBwdBtn "19.09.02";
BA_ "Description" SG_ 543 ATS_AstStFRestFldBtn "µ¿½Â¼® Ç²·¹½ºÆ® Æúµù ÀÌµ¿ (¿öÅ©ÀÎ ÀÛµ¿)";
BA_ "GenSigSendType" SG_ 543 ATS_AstStFRestFldBtn 4;
BA_ "UserSigValidity" SG_ 543 ATS_AstStFRestFldBtn 3;
BA_ "NetworkRequest" SG_ 543 ATS_AstStFRestFldBtn 0;
BA_ "NetworkRequestHoldingTime" SG_ 543 ATS_AstStFRestFldBtn 5000;
BA_ "Version" SG_ 543 ATS_AstStFRestFldBtn "19.09.02";
BA_ "Description" SG_ 543 ATS_AstStFRestUnFldBtn "µ¿½Â¼® Ç²·¹½ºÆ® ¾ðÆúµù ÀÌµ¿ (¿öÅ©ÀÎ ÀÛµ¿)";
BA_ "GenSigSendType" SG_ 543 ATS_AstStFRestUnFldBtn 4;
BA_ "UserSigValidity" SG_ 543 ATS_AstStFRestUnFldBtn 3;
BA_ "NetworkRequest" SG_ 543 ATS_AstStFRestUnFldBtn 0;
BA_ "NetworkRequestHoldingTime" SG_ 543 ATS_AstStFRestUnFldBtn 5000;
BA_ "Version" SG_ 543 ATS_AstStFRestUnFldBtn "19.09.02";
BA_ "Description" SG_ 543 ATS_AstTltUpBtn "µ¿½Â¼® Æ¿Æ® UP ÀÌµ¿ (¿öÅ©ÀÎ ÀÛµ¿)";
BA_ "GenSigSendType" SG_ 543 ATS_AstTltUpBtn 4;
BA_ "UserSigValidity" SG_ 543 ATS_AstTltUpBtn 3;
BA_ "NetworkRequest" SG_ 543 ATS_AstTltUpBtn 0;
BA_ "NetworkRequestHoldingTime" SG_ 543 ATS_AstTltUpBtn 5000;
BA_ "Version" SG_ 543 ATS_AstTltUpBtn "19.12.00";
BA_ "Description" SG_ 543 ATS_AstTltDnBtn "µ¿½Â¼® Æ¿Æ® DOWN ÀÌµ¿ (¿öÅ©ÀÎ ÀÛµ¿)";
BA_ "GenSigSendType" SG_ 543 ATS_AstTltDnBtn 4;
BA_ "UserSigValidity" SG_ 543 ATS_AstTltDnBtn 3;
BA_ "NetworkRequest" SG_ 543 ATS_AstTltDnBtn 0;
BA_ "NetworkRequestHoldingTime" SG_ 543 ATS_AstTltDnBtn 5000;
BA_ "Version" SG_ 543 ATS_AstTltDnBtn "19.12.00";
BA_ "Description" SG_ 2214658052 ENG_DclBrkCntrlReq "When current vehicle speed goes over set vehicle speed in the downhill during cruise control or speed limiter, ECU requests brake control to TCS with target deceleration. This is function of (Current vehicle speed - Set vehicle speed).";
BA_ "GenSigStartValue" SG_ 2214658052 ENG_DclBrkCntrlReq 4094;
BA_ "UserSigValidity" SG_ 2214658052 ENG_DclBrkCntrlReq 3;
BA_ "RoutingFactor" SG_ 2214658052 ENG_DclBrkCntrlReq 5;
BA_ "Version" SG_ 2214658052 ENG_DclBrkCntrlReq "17.12.00";
BA_ "Description" SG_ 2214658052 ENG_BstPrsrVal "Boost pressure for Turbo engine";
BA_ "UserSigValidity" SG_ 2214658052 ENG_BstPrsrVal 3;
BA_ "RoutingFactor" SG_ 2214658052 ENG_BstPrsrVal 5;
BA_ "Version" SG_ 2214658052 ENG_BstPrsrVal "17.12.00";
BA_ "Description" SG_ 2214658052 ENG_EngOilTempVal "engine oil temperature";
BA_ "GenSigStartValue" SG_ 2214658052 ENG_EngOilTempVal 53;
BA_ "UserSigValidity" SG_ 2214658052 ENG_EngOilTempVal 3;
BA_ "RoutingFactor" SG_ 2214658052 ENG_EngOilTempVal 5;
BA_ "Version" SG_ 2214658052 ENG_EngOilTempVal "17.12.00";
BA_ "Description" SG_ 2214658052 ENG_AmbtTempModelVal "Modeled Ambient temperature";
BA_ "GenSigStartValue" SG_ 2214658052 ENG_AmbtTempModelVal 164;
BA_ "UserSigValidity" SG_ 2214658052 ENG_AmbtTempModelVal 3;
BA_ "RoutingFactor" SG_ 2214658052 ENG_AmbtTempModelVal 5;
BA_ "Version" SG_ 2214658052 ENG_AmbtTempModelVal "17.12.00";
BA_ "Description" SG_ 2214658052 ENG_DpfWrngSta "The signal indicates the status of the 'DPF Warning Level'";
BA_ "UserSigValidity" SG_ 2214658052 ENG_DpfWrngSta 3;
BA_ "RoutingFactor" SG_ 2214658052 ENG_DpfWrngSta 5;
BA_ "Version" SG_ 2214658052 ENG_DpfWrngSta "17.12.00";
BA_ "Description" SG_ 2214658052 ENG_BattWrngLmpSta "The signal indicates the status of the 'Battery Warning Lamp'";
BA_ "UserSigValidity" SG_ 2214658052 ENG_BattWrngLmpSta 3;
BA_ "RoutingFactor" SG_ 2214658052 ENG_BattWrngLmpSta 5;
BA_ "Version" SG_ 2214658052 ENG_BattWrngLmpSta "17.12.00";
BA_ "Description" SG_ 2214658052 ENG_OilPrsrWrngLmpSta "The signal indicates the status of the 'Oil Pressure Warning Lamp'";
BA_ "UserSigValidity" SG_ 2214658052 ENG_OilPrsrWrngLmpSta 3;
BA_ "RoutingFactor" SG_ 2214658052 ENG_OilPrsrWrngLmpSta 5;
BA_ "Version" SG_ 2214658052 ENG_OilPrsrWrngLmpSta "17.12.00";
BA_ "Description" SG_ 2214658052 ENG_IsgInhbtLmpSta "The signal indicates the status of the 'ISG Inhibit Lamp'";
BA_ "UserSigValidity" SG_ 2214658052 ENG_IsgInhbtLmpSta 3;
BA_ "RoutingFactor" SG_ 2214658052 ENG_IsgInhbtLmpSta 5;
BA_ "Version" SG_ 2214658052 ENG_IsgInhbtLmpSta "17.12.00";
BA_ "Description" SG_ 2273435649 ADAS_CMD_Crc31Val "The data area for CRC calculation is based on the data length (DLC) of the message DB.

The CRC shall be calculated over the entire data block (excluding the CRC bytes) including the user data, alive counter and Data ID



- CRC Polynomial (0x1021) , Ini";
BA_ "GenSigStartValue" SG_ 2273435649 ADAS_CMD_Crc31Val 65535;
BA_ "UserSigValidity" SG_ 2273435649 ADAS_CMD_Crc31Val 3;
BA_ "RoutingFactor" SG_ 2273435649 ADAS_CMD_Crc31Val 3;
BA_ "Version" SG_ 2273435649 ADAS_CMD_Crc31Val "21.09.03";
BA_ "Description" SG_ 2273435649 ADAS_CMD_AlvCnt31Val "For the first transmission request for a data element the counter shall be initialized with 0 and shall be incremented by 1 for every subsequent send request. 

When the counter reaches the maximum value(0xFF), then it shall restart with 0 for the next s";
BA_ "UserSigValidity" SG_ 2273435649 ADAS_CMD_AlvCnt31Val 3;
BA_ "RoutingFactor" SG_ 2273435649 ADAS_CMD_AlvCnt31Val 3;
BA_ "Version" SG_ 2273435649 ADAS_CMD_AlvCnt31Val "21.09.03";
BA_ "Description" SG_ 2273435649 HDA_OptUsmSta "This is HDA system status needed for the cluster USM display.";
BA_ "UserSigValidity" SG_ 2273435649 HDA_OptUsmSta 3;
BA_ "RoutingFactor" SG_ 2273435649 HDA_OptUsmSta 3;
BA_ "Version" SG_ 2273435649 HDA_OptUsmSta "17.12.02";
BA_ "Description" SG_ 2273435649 HDA_CntrlModSta "This is HDA Control Mode needed for longitudinal/lateral control and cluster display.";
BA_ "UserSigValidity" SG_ 2273435649 HDA_CntrlModSta 3;
BA_ "RoutingFactor" SG_ 2273435649 HDA_CntrlModSta 3;
BA_ "Version" SG_ 2273435649 HDA_CntrlModSta "20.05.02";
BA_ "Description" SG_ 2273435649 HDA_InfoPUDis "This is HDA information display needed for the cluster pop-up display.";
BA_ "UserSigValidity" SG_ 2273435649 HDA_InfoPUDis 3;
BA_ "RoutingFactor" SG_ 2273435649 HDA_InfoPUDis 3;
BA_ "Version" SG_ 2273435649 HDA_InfoPUDis "21.10.02";
BA_ "Description" SG_ 2273435649 HDP_AutoCallReqSta "This signal is needed for HDP Auto Call.";
BA_ "UserSigValidity" SG_ 2273435649 HDP_AutoCallReqSta 3;
BA_ "RoutingFactor" SG_ 2273435649 HDP_AutoCallReqSta 3;
BA_ "Version" SG_ 2273435649 HDP_AutoCallReqSta "21.04.03";
BA_ "Description" SG_ 2273435649 HDP_DispBarSta "This signal indicates HDP operation state (always not covered other display)";
BA_ "UserSigValidity" SG_ 2273435649 HDP_DispBarSta 0;
BA_ "RoutingFactor" SG_ 2273435649 HDP_DispBarSta 3;
BA_ "Version" SG_ 2273435649 HDP_DispBarSta "22.01.00";
BA_ "Description" SG_ 2273435649 HDP_OptInfoSta "This signal indicates whether the HDP system has been applied or not.";
BA_ "UserSigValidity" SG_ 2273435649 HDP_OptInfoSta 0;
BA_ "RoutingFactor" SG_ 2273435649 HDP_OptInfoSta 3;
BA_ "Version" SG_ 2273435649 HDP_OptInfoSta "21.10.02";
BA_ "Description" SG_ 2273435649 HDA_LFA_SymSta "This signal shows the state of steering assist.";
BA_ "UserSigValidity" SG_ 2273435649 HDA_LFA_SymSta 3;
BA_ "RoutingFactor" SG_ 2273435649 HDA_LFA_SymSta 3;
BA_ "Version" SG_ 2273435649 HDA_LFA_SymSta "20.11.02";
BA_ "Description" SG_ 2273435649 HDA_LFA_WrnSnd "HDA/LFA Additional Warning Sound";
BA_ "UserSigValidity" SG_ 2273435649 HDA_LFA_WrnSnd 3;
BA_ "RoutingFactor" SG_ 2273435649 HDA_LFA_WrnSnd 3;
BA_ "Version" SG_ 2273435649 HDA_LFA_WrnSnd "18.02.03";
BA_ "Description" SG_ 2273435649 HDA_InfoPUDis1 "This is HDA/LFA information display needed for the cluster pop-up display.";
BA_ "UserSigValidity" SG_ 2273435649 HDA_InfoPUDis1 3;
BA_ "RoutingFactor" SG_ 2273435649 HDA_InfoPUDis1 3;
BA_ "Version" SG_ 2273435649 HDA_InfoPUDis1 "21.01.08";
BA_ "Description" SG_ 2273435649 HDA_TDMRMDclReq "This signal show the state of LFA automatic deactivation.";
BA_ "UserSigValidity" SG_ 2273435649 HDA_TDMRMDclReq 3;
BA_ "RoutingFactor" SG_ 2273435649 HDA_TDMRMDclReq 3;
BA_ "Version" SG_ 2273435649 HDA_TDMRMDclReq "19.02.00";
BA_ "Description" SG_ 2273435649 HDP_ActvSta "This signal indicates control active status of HDP.";
BA_ "UserSigValidity" SG_ 2273435649 HDP_ActvSta 3;
BA_ "RoutingFactor" SG_ 2273435649 HDP_ActvSta 3;
BA_ "Version" SG_ 2273435649 HDP_ActvSta "19.11.02";
BA_ "Description" SG_ 2273435649 HDP_SysSta "This signal indicates system status of HDP.";
BA_ "UserSigValidity" SG_ 2273435649 HDP_SysSta 3;
BA_ "RoutingFactor" SG_ 2273435649 HDP_SysSta 3;
BA_ "Version" SG_ 2273435649 HDP_SysSta "20.07.10";
BA_ "Description" SG_ 2273435649 HDP_FailureMode "This signal shows HDP failure status";
BA_ "UserSigValidity" SG_ 2273435649 HDP_FailureMode 3;
BA_ "RoutingFactor" SG_ 2273435649 HDP_FailureMode 3;
BA_ "Version" SG_ 2273435649 HDP_FailureMode "20.07.10";
BA_ "Description" SG_ 2273435650 HDP_ObstacleDstVal "This signal indicates distance to a obstacle which is on driving path.";
BA_ "GenSigStartValue" SG_ 2273435650 HDP_ObstacleDstVal 2046;
BA_ "UserSigValidity" SG_ 2273435650 HDP_ObstacleDstVal 3;
BA_ "RoutingFactor" SG_ 2273435650 HDP_ObstacleDstVal 3;
BA_ "Version" SG_ 2273435650 HDP_ObstacleDstVal "19.11.02";
BA_ "Description" SG_ 2273435650 HDP_ObstacleLatPosVal "This signal indicates distance to a obstacle which is on driving path.";
BA_ "GenSigStartValue" SG_ 2273435650 HDP_ObstacleLatPosVal 510;
BA_ "UserSigValidity" SG_ 2273435650 HDP_ObstacleLatPosVal 3;
BA_ "RoutingFactor" SG_ 2273435650 HDP_ObstacleLatPosVal 3;
BA_ "Version" SG_ 2273435650 HDP_ObstacleLatPosVal "19.11.02";
BA_ "Description" SG_ 2273435650 HDP_InfoPUDis "This signal needed for the cluster pop-up display to inform HDP system status and warning.";
BA_ "UserSigValidity" SG_ 2273435650 HDP_InfoPUDis 0;
BA_ "RoutingFactor" SG_ 2273435650 HDP_InfoPUDis 3;
BA_ "Version" SG_ 2273435650 HDP_InfoPUDis "22.05.00";
BA_ "Description" SG_ 2273435650 HDP_WrngTypPUDis "This signal is needed for the cluster mini pop-up display to inform a reason of unavailable/TD activation or warning messages.";
BA_ "UserSigValidity" SG_ 2273435650 HDP_WrngTypPUDis 3;
BA_ "RoutingFactor" SG_ 2273435650 HDP_WrngTypPUDis 3;
BA_ "Version" SG_ 2273435650 HDP_WrngTypPUDis "20.03.01";
BA_ "Description" SG_ 2273435650 HDP_HapticWarnReq "This signal is needed for HDP haptic warning";
BA_ "UserSigValidity" SG_ 2273435650 HDP_HapticWarnReq 3;
BA_ "RoutingFactor" SG_ 2273435650 HDP_HapticWarnReq 3;
BA_ "Version" SG_ 2273435650 HDP_HapticWarnReq "22.08.00";
BA_ "Description" SG_ 2273435650 HDP_ActvStaDis "This signal is needed for the cluster symbol display to inform a activation or deactivation status";
BA_ "UserSigValidity" SG_ 2273435650 HDP_ActvStaDis 0;
BA_ "RoutingFactor" SG_ 2273435650 HDP_ActvStaDis 3;
BA_ "Version" SG_ 2273435650 HDP_ActvStaDis "22.05.00";
BA_ "Description" SG_ 2273435650 HDP_OpStaDisp "This signal is needed for the cluster symbol display to inform highway driving pilot status";
BA_ "UserSigValidity" SG_ 2273435650 HDP_OpStaDisp 0;
BA_ "RoutingFactor" SG_ 2273435650 HDP_OpStaDisp 3;
BA_ "Version" SG_ 2273435650 HDP_OpStaDisp "22.05.00";
BA_ "Description" SG_ 2273435650 HDP_ObstSta "This signal represents the state of in-path obstacle and information of controllable state.

- ÀÚÂ÷¼±»óÀÇ Àü¹æ ÀÏ¹Ý¹°Ã¼ ÀÎ½Ä ¿©ºÎ ¹× Á¦¾î °¡´É »óÅÂ Á¤º¸";
BA_ "UserSigValidity" SG_ 2273435650 HDP_ObstSta 3;
BA_ "RoutingFactor" SG_ 2273435650 HDP_ObstSta 3;
BA_ "Version" SG_ 2273435650 HDP_ObstSta "20.06.01";
BA_ "Description" SG_ 2273435650 HDP_SysFlrDisp "This signal is for pop-up indication of HDP system failure.

If this signal is set to 1, the display device shall indicate HDP failure information to the driver.";
BA_ "UserSigValidity" SG_ 2273435650 HDP_SysFlrDisp 0;
BA_ "RoutingFactor" SG_ 2273435650 HDP_SysFlrDisp 3;
BA_ "Version" SG_ 2273435650 HDP_SysFlrDisp "22.05.00";
BA_ "Description" SG_ 2273435650 HDP_InhbtOffDispSta "This signal is shows that driving safety functions are inhibited while HDP in operation";
BA_ "UserSigValidity" SG_ 2273435650 HDP_InhbtOffDispSta 0;
BA_ "RoutingFactor" SG_ 2273435650 HDP_InhbtOffDispSta 3;
BA_ "Version" SG_ 2273435650 HDP_InhbtOffDispSta "22.05.00";
BA_ "Description" SG_ 2273435650 HDP_CtRoadSrfcDistVal "This signal is notifying how far to display the road surfaces.";
BA_ "GenSigStartValue" SG_ 2273435650 HDP_CtRoadSrfcDistVal 2046;
BA_ "UserSigValidity" SG_ 2273435650 HDP_CtRoadSrfcDistVal 0;
BA_ "RoutingFactor" SG_ 2273435650 HDP_CtRoadSrfcDistVal 3;
BA_ "Version" SG_ 2273435650 HDP_CtRoadSrfcDistVal "22.05.00";
BA_ "Description" SG_ 2273435650 ADAS_DRV_UpDateInfo "ADAS_DRV update state info for AVN";
BA_ "GenSigStartValue" SG_ 2273435650 ADAS_DRV_UpDateInfo 1;
BA_ "UserSigValidity" SG_ 2273435650 ADAS_DRV_UpDateInfo 3;
BA_ "RoutingFactor" SG_ 2273435650 ADAS_DRV_UpDateInfo 3;
BA_ "Version" SG_ 2273435650 ADAS_DRV_UpDateInfo "20.10.02";
BA_ "Description" SG_ 2214658049 EMS_Crc2Val "The data area for CRC calculation is based on the data length (DLC) of the message DB.

The CRC shall be calculated over the entire data block (excluding the CRC bytes) including the user data, alive counter and Data ID



- CRC Polynomial (0x1021) , Ini";
BA_ "GenSigStartValue" SG_ 2214658049 EMS_Crc2Val 65535;
BA_ "UserSigValidity" SG_ 2214658049 EMS_Crc2Val 3;
BA_ "RoutingFactor" SG_ 2214658049 EMS_Crc2Val 5;
BA_ "Version" SG_ 2214658049 EMS_Crc2Val "21.09.03";
BA_ "Description" SG_ 2214658049 EMS_AlvCnt2Val "For the first transmission request for a data element the counter shall be initialized with 0 and shall be incremented by 1 for every subsequent send request. 

When the counter reaches the maximum value(0xFF), then it shall restart with 0 for the next s";
BA_ "UserSigValidity" SG_ 2214658049 EMS_AlvCnt2Val 3;
BA_ "RoutingFactor" SG_ 2214658049 EMS_AlvCnt2Val 5;
BA_ "Version" SG_ 2214658049 EMS_AlvCnt2Val "21.09.03";
BA_ "Description" SG_ 2214658049 ENG_BrkSwSta "This signal indicates that a brake switch is activated or not. When the brake switch is activated(pressed) its value is 01H otherwise its value is 00H.

If the EMS does not support this signal the value is 02H.



Physical range : 0 ... 100

Conversion :";
BA_ "GenSigStartValue" SG_ 2214658049 ENG_BrkSwSta 1;
BA_ "UserSigValidity" SG_ 2214658049 ENG_BrkSwSta 3;
BA_ "RoutingFactor" SG_ 2214658049 ENG_BrkSwSta 5;
BA_ "Version" SG_ 2214658049 ENG_BrkSwSta "18.11.00";
BA_ "Description" SG_ 2214658049 ENG_ObdFrzFrmSta "An ECU which detects an OBD fault, requires the EMS to store a set of environmental conditions

(freeze frame). If the EMS follows this requirement it is acknowledged in OBD_FRF_ACK. Also the synchronization of OBD relevant ECUs is made by this signal:

";
BA_ "UserSigValidity" SG_ 2214658049 ENG_ObdFrzFrmSta 3;
BA_ "RoutingFactor" SG_ 2214658049 ENG_ObdFrzFrmSta 5;
BA_ "Version" SG_ 2214658049 ENG_ObdFrzFrmSta "17.12.00";
BA_ "Description" SG_ 2214658049 ENG_EngClntTempVal "Engine coolant temperature in EMS sensed via an A/D converter; converted into degrees centigrade (¡ÆC).";
BA_ "GenSigStartValue" SG_ 2214658049 ENG_EngClntTempVal 255;
BA_ "UserSigValidity" SG_ 2214658049 ENG_EngClntTempVal 3;
BA_ "RoutingFactor" SG_ 2214658049 ENG_EngClntTempVal 5;
BA_ "Version" SG_ 2214658049 ENG_EngClntTempVal "17.12.00";
BA_ "Description" SG_ 2214658049 ENG_MafCrctVal "The altitude correction factor MAF_FAC_ALTI_MMV is calculated from division of MAF by MAF_SUB_DIAG (=limp home-value for MAF) or from AMP_AD by 1013 mbar in order to take into account different atmospheric pressures at different altitudes.



The Initial";
BA_ "GenSigStartValue" SG_ 2214658049 ENG_MafCrctVal 128;
BA_ "UserSigValidity" SG_ 2214658049 ENG_MafCrctVal 3;
BA_ "RoutingFactor" SG_ 2214658049 ENG_MafCrctVal 5;
BA_ "Version" SG_ 2214658049 ENG_MafCrctVal "17.12.00";
BA_ "Description" SG_ 2214658049 ENG_BattDscnctSta "The signal specifies that ECU has detected a disconnection of the battery since last driving cycle, and therefore has reset the adaptive values and failure memory.

If the EMS does not support this signal the value is 00H



The failure memory erasure is";
BA_ "UserSigValidity" SG_ 2214658049 ENG_BattDscnctSta 3;
BA_ "RoutingFactor" SG_ 2214658049 ENG_BattDscnctSta 5;
BA_ "Version" SG_ 2214658049 ENG_BattDscnctSta "17.12.00";
BA_ "Description" SG_ 2214658049 OBD_MilConfgVal "The signal specifies the Configuration of the MIL Handling and Failure Memory Management by ECU.";
BA_ "GenSigStartValue" SG_ 2214658049 OBD_MilConfgVal 3;
BA_ "UserSigValidity" SG_ 2214658049 OBD_MilConfgVal 3;
BA_ "RoutingFactor" SG_ 2214658049 OBD_MilConfgVal 5;
BA_ "Version" SG_ 2214658049 OBD_MilConfgVal "17.12.00";
BA_ "Description" SG_ 2214658049 ENG_EngSta "This signal indicates that a status of engine.";
BA_ "UserSigValidity" SG_ 2214658049 ENG_EngSta 3;
BA_ "RoutingFactor" SG_ 2214658049 ENG_EngSta 5;
BA_ "Version" SG_ 2214658049 ENG_EngSta "17.12.00";
BA_ "Description" SG_ 614 EMCU_Crc1Val "The data area for CRC calculation is based on the data length (DLC) of the message DB.

The CRC shall be calculated over the entire data block (excluding the CRC bytes) including the user data, alive counter and Data ID 

 

- CRC Polynomial (0x1D) , Ini";
BA_ "GenSigSendType" SG_ 614 EMCU_Crc1Val 4;
BA_ "UserSigValidity" SG_ 614 EMCU_Crc1Val 3;
BA_ "Version" SG_ 614 EMCU_Crc1Val "21.09.03";
BA_ "Description" SG_ 614 EMCU_AlvCnt1Val "For the first transmission request for a data element the counter shall be initialized with 0 and shall be incremented by 1

for every subsequent send request. When the counter reaches the maximum value(0xE), then it shall restart with 0 for the next sen";
BA_ "GenSigSendType" SG_ 614 EMCU_AlvCnt1Val 4;
BA_ "UserSigValidity" SG_ 614 EMCU_AlvCnt1Val 3;
BA_ "Version" SG_ 614 EMCU_AlvCnt1Val "21.09.03";
BA_ "Description" SG_ 614 EMCU_LHActSta "Left Engine Mount ON/OFF Status";
BA_ "GenSigSendType" SG_ 614 EMCU_LHActSta 4;
BA_ "UserSigValidity" SG_ 614 EMCU_LHActSta 3;
BA_ "Version" SG_ 614 EMCU_LHActSta "21.10.03";
BA_ "Description" SG_ 614 EMCU_RHActSta "Right Engine Mount ON/OFF Status";
BA_ "GenSigSendType" SG_ 614 EMCU_RHActSta 4;
BA_ "UserSigValidity" SG_ 614 EMCU_RHActSta 3;
BA_ "Version" SG_ 614 EMCU_RHActSta "21.10.03";
BA_ "Description" SG_ 614 EMCU_DeltaSpdVal "Current Delta Speed Vaule in control logic";
BA_ "GenSigSendType" SG_ 614 EMCU_DeltaSpdVal 4;
BA_ "UserSigValidity" SG_ 614 EMCU_DeltaSpdVal 3;
BA_ "Version" SG_ 614 EMCU_DeltaSpdVal "21.10.03";
BA_ "Description" SG_ 614 EMCU_System_Sta "Engine Mount Control Unit Status";
BA_ "GenSigSendType" SG_ 614 EMCU_System_Sta 4;
BA_ "UserSigValidity" SG_ 614 EMCU_System_Sta 3;
BA_ "Version" SG_ 614 EMCU_System_Sta "21.10.03";
BA_ "UsrSigPurpose" SG_ 1578 PSB_CCP_CRO_Byte0 0;
BA_ "GenSigSendType" SG_ 1578 PSB_CCP_CRO_Byte0 2;
BA_ "UserSigValidity" SG_ 1578 PSB_CCP_CRO_Byte0 0;
BA_ "NetworkRequest" SG_ 1578 PSB_CCP_CRO_Byte0 0;
BA_ "NetworkRequestHoldingTime" SG_ 1578 PSB_CCP_CRO_Byte0 5000;
BA_ "Version" SG_ 1578 PSB_CCP_CRO_Byte0 "21.02.04";
BA_ "UsrSigPurpose" SG_ 1578 PSB_CCP_CRO_Byte2 0;
BA_ "GenSigSendType" SG_ 1578 PSB_CCP_CRO_Byte2 2;
BA_ "UserSigValidity" SG_ 1578 PSB_CCP_CRO_Byte2 0;
BA_ "NetworkRequest" SG_ 1578 PSB_CCP_CRO_Byte2 0;
BA_ "NetworkRequestHoldingTime" SG_ 1578 PSB_CCP_CRO_Byte2 5000;
BA_ "Version" SG_ 1578 PSB_CCP_CRO_Byte2 "21.02.04";
BA_ "UsrSigPurpose" SG_ 1578 PSB_CCP_CRO_Byte3 0;
BA_ "GenSigSendType" SG_ 1578 PSB_CCP_CRO_Byte3 2;
BA_ "UserSigValidity" SG_ 1578 PSB_CCP_CRO_Byte3 0;
BA_ "NetworkRequest" SG_ 1578 PSB_CCP_CRO_Byte3 0;
BA_ "NetworkRequestHoldingTime" SG_ 1578 PSB_CCP_CRO_Byte3 5000;
BA_ "Version" SG_ 1578 PSB_CCP_CRO_Byte3 "21.02.04";
BA_ "UsrSigPurpose" SG_ 1578 PSB_CCP_CRO_Byte4 0;
BA_ "GenSigSendType" SG_ 1578 PSB_CCP_CRO_Byte4 2;
BA_ "UserSigValidity" SG_ 1578 PSB_CCP_CRO_Byte4 0;
BA_ "NetworkRequest" SG_ 1578 PSB_CCP_CRO_Byte4 0;
BA_ "NetworkRequestHoldingTime" SG_ 1578 PSB_CCP_CRO_Byte4 5000;
BA_ "Version" SG_ 1578 PSB_CCP_CRO_Byte4 "21.02.04";
BA_ "UsrSigPurpose" SG_ 1578 PSB_CCP_CRO_Byte5 0;
BA_ "GenSigSendType" SG_ 1578 PSB_CCP_CRO_Byte5 2;
BA_ "UserSigValidity" SG_ 1578 PSB_CCP_CRO_Byte5 0;
BA_ "NetworkRequest" SG_ 1578 PSB_CCP_CRO_Byte5 0;
BA_ "NetworkRequestHoldingTime" SG_ 1578 PSB_CCP_CRO_Byte5 5000;
BA_ "Version" SG_ 1578 PSB_CCP_CRO_Byte5 "21.02.04";
BA_ "UsrSigPurpose" SG_ 1578 PSB_CCP_CRO_Byte6 0;
BA_ "GenSigSendType" SG_ 1578 PSB_CCP_CRO_Byte6 2;
BA_ "UserSigValidity" SG_ 1578 PSB_CCP_CRO_Byte6 0;
BA_ "NetworkRequest" SG_ 1578 PSB_CCP_CRO_Byte6 0;
BA_ "NetworkRequestHoldingTime" SG_ 1578 PSB_CCP_CRO_Byte6 5000;
BA_ "Version" SG_ 1578 PSB_CCP_CRO_Byte6 "21.02.04";
BA_ "UsrSigPurpose" SG_ 1578 PSB_CCP_CRO_Byte7 0;
BA_ "GenSigSendType" SG_ 1578 PSB_CCP_CRO_Byte7 2;
BA_ "UserSigValidity" SG_ 1578 PSB_CCP_CRO_Byte7 0;
BA_ "NetworkRequest" SG_ 1578 PSB_CCP_CRO_Byte7 0;
BA_ "NetworkRequestHoldingTime" SG_ 1578 PSB_CCP_CRO_Byte7 5000;
BA_ "Version" SG_ 1578 PSB_CCP_CRO_Byte7 "21.02.04";
BA_ "UsrSigPurpose" SG_ 1578 PSB_CCP_CRO_Byte1 0;
BA_ "GenSigSendType" SG_ 1578 PSB_CCP_CRO_Byte1 2;
BA_ "UserSigValidity" SG_ 1578 PSB_CCP_CRO_Byte1 0;
BA_ "NetworkRequest" SG_ 1578 PSB_CCP_CRO_Byte1 0;
BA_ "NetworkRequestHoldingTime" SG_ 1578 PSB_CCP_CRO_Byte1 5000;
BA_ "Version" SG_ 1578 PSB_CCP_CRO_Byte1 "21.02.04";
BA_ "UsrSigPurpose" SG_ 1579 PSB_CCP_DTO_Byte0 0;
BA_ "GenSigSendType" SG_ 1579 PSB_CCP_DTO_Byte0 2;
BA_ "UserSigValidity" SG_ 1579 PSB_CCP_DTO_Byte0 0;
BA_ "NetworkRequest" SG_ 1579 PSB_CCP_DTO_Byte0 0;
BA_ "NetworkRequestHoldingTime" SG_ 1579 PSB_CCP_DTO_Byte0 5000;
BA_ "Version" SG_ 1579 PSB_CCP_DTO_Byte0 "21.02.04";
BA_ "UsrSigPurpose" SG_ 1579 PSB_CCP_DTO_Byte2 0;
BA_ "GenSigSendType" SG_ 1579 PSB_CCP_DTO_Byte2 2;
BA_ "UserSigValidity" SG_ 1579 PSB_CCP_DTO_Byte2 0;
BA_ "NetworkRequest" SG_ 1579 PSB_CCP_DTO_Byte2 0;
BA_ "NetworkRequestHoldingTime" SG_ 1579 PSB_CCP_DTO_Byte2 5000;
BA_ "Version" SG_ 1579 PSB_CCP_DTO_Byte2 "21.02.04";
BA_ "UsrSigPurpose" SG_ 1579 PSB_CCP_DTO_Byte3 0;
BA_ "GenSigSendType" SG_ 1579 PSB_CCP_DTO_Byte3 2;
BA_ "UserSigValidity" SG_ 1579 PSB_CCP_DTO_Byte3 0;
BA_ "NetworkRequest" SG_ 1579 PSB_CCP_DTO_Byte3 0;
BA_ "NetworkRequestHoldingTime" SG_ 1579 PSB_CCP_DTO_Byte3 5000;
BA_ "Version" SG_ 1579 PSB_CCP_DTO_Byte3 "21.02.04";
BA_ "UsrSigPurpose" SG_ 1579 PSB_CCP_DTO_Byte4 0;
BA_ "GenSigSendType" SG_ 1579 PSB_CCP_DTO_Byte4 2;
BA_ "UserSigValidity" SG_ 1579 PSB_CCP_DTO_Byte4 0;
BA_ "NetworkRequest" SG_ 1579 PSB_CCP_DTO_Byte4 0;
BA_ "NetworkRequestHoldingTime" SG_ 1579 PSB_CCP_DTO_Byte4 5000;
BA_ "Version" SG_ 1579 PSB_CCP_DTO_Byte4 "21.02.04";
BA_ "UsrSigPurpose" SG_ 1579 PSB_CCP_DTO_Byte5 0;
BA_ "GenSigSendType" SG_ 1579 PSB_CCP_DTO_Byte5 2;
BA_ "UserSigValidity" SG_ 1579 PSB_CCP_DTO_Byte5 0;
BA_ "NetworkRequest" SG_ 1579 PSB_CCP_DTO_Byte5 0;
BA_ "NetworkRequestHoldingTime" SG_ 1579 PSB_CCP_DTO_Byte5 5000;
BA_ "Version" SG_ 1579 PSB_CCP_DTO_Byte5 "21.02.04";
BA_ "UsrSigPurpose" SG_ 1579 PSB_CCP_DTO_Byte6 0;
BA_ "GenSigSendType" SG_ 1579 PSB_CCP_DTO_Byte6 2;
BA_ "UserSigValidity" SG_ 1579 PSB_CCP_DTO_Byte6 0;
BA_ "NetworkRequest" SG_ 1579 PSB_CCP_DTO_Byte6 0;
BA_ "NetworkRequestHoldingTime" SG_ 1579 PSB_CCP_DTO_Byte6 5000;
BA_ "Version" SG_ 1579 PSB_CCP_DTO_Byte6 "21.02.04";
BA_ "UsrSigPurpose" SG_ 1579 PSB_CCP_DTO_Byte7 0;
BA_ "GenSigSendType" SG_ 1579 PSB_CCP_DTO_Byte7 2;
BA_ "UserSigValidity" SG_ 1579 PSB_CCP_DTO_Byte7 0;
BA_ "NetworkRequest" SG_ 1579 PSB_CCP_DTO_Byte7 0;
BA_ "NetworkRequestHoldingTime" SG_ 1579 PSB_CCP_DTO_Byte7 5000;
BA_ "Version" SG_ 1579 PSB_CCP_DTO_Byte7 "21.02.04";
BA_ "UsrSigPurpose" SG_ 1579 PSB_CCP_DTO_Byte1 0;
BA_ "GenSigSendType" SG_ 1579 PSB_CCP_DTO_Byte1 2;
BA_ "UserSigValidity" SG_ 1579 PSB_CCP_DTO_Byte1 0;
BA_ "NetworkRequest" SG_ 1579 PSB_CCP_DTO_Byte1 0;
BA_ "NetworkRequestHoldingTime" SG_ 1579 PSB_CCP_DTO_Byte1 5000;
BA_ "Version" SG_ 1579 PSB_CCP_DTO_Byte1 "21.02.04";
BA_ "Description" SG_ 2214658051 ENG_MinIndTqVal "The signal TQI_MIN is the minimum engine torque (minimum air charging rate) which can be fired without misfire including compensation factors such as atmospheric pressure and temperature.

It is not enough to keep the engine running without external powe";
BA_ "UserSigValidity" SG_ 2214658051 ENG_MinIndTqVal 3;
BA_ "RoutingFactor" SG_ 2214658051 ENG_MinIndTqVal 5;
BA_ "Version" SG_ 2214658051 ENG_MinIndTqVal "18.01.01";
BA_ "Description" SG_ 2214658051 ENG_TrgtTqVal "The signal TQI_TARGET is determined by an engine torque map with input which consists of  acceleration pedal value, MAF sensor, current RPM and etc. This signal reflects driver¡¯s demand directly. 

But it does not depend on torque interventions realised";
BA_ "UserSigValidity" SG_ 2214658051 ENG_TrgtTqVal 3;
BA_ "RoutingFactor" SG_ 2214658051 ENG_TrgtTqVal 5;
BA_ "Version" SG_ 2214658051 ENG_TrgtTqVal "18.01.01";
BA_ "Description" SG_ 2214658051 ENG_MaxIndTqVal "The signal TQI_MAX is the current maximum indicated engine torque. This signal reflects the maximum engine torque under current conditions (engine speed, etc¡¦).



Note : TQI_MAX must be transmitted actual engine torque including COT, thermal/spark effi";
BA_ "UserSigValidity" SG_ 2214658051 ENG_MaxIndTqVal 3;
BA_ "RoutingFactor" SG_ 2214658051 ENG_MaxIndTqVal 5;
BA_ "Version" SG_ 2214658051 ENG_MaxIndTqVal "18.01.01";
BA_ "Description" SG_ 2214658051 ENG_AppAccelPdlSta "This signal indicates if the driver applies the accelerator pedal. 

The signal always indicates the actual operation of the accelerator pedal, independent from SCC mode.";
BA_ "UserSigValidity" SG_ 2214658051 ENG_AppAccelPdlSta 3;
BA_ "RoutingFactor" SG_ 2214658051 ENG_AppAccelPdlSta 5;
BA_ "Version" SG_ 2214658051 ENG_AppAccelPdlSta "17.12.00";
BA_ "Description" SG_ 2214658051 ENG_BrkCtrlReq "This signal indicates that if brake control request during cruise control or speed limiter is active or not. This signal is for prevention of unwanted vehicle speed increase during cruise control or speed limiter control mode.";
BA_ "UserSigValidity" SG_ 2214658051 ENG_BrkCtrlReq 3;
BA_ "RoutingFactor" SG_ 2214658051 ENG_BrkCtrlReq 5;
BA_ "Version" SG_ 2214658051 ENG_BrkCtrlReq "17.12.00";
BA_ "Description" SG_ 2214658051 ACC_DnShftCtrlReq "This signal indicates target gear for downshift control request during cruise control or speed limiter is active or not. This signal is for prevention of unwanted vehicle speed increase during cruise control or speed limiter control mode.";
BA_ "UserSigValidity" SG_ 2214658051 ACC_DnShftCtrlReq 3;
BA_ "RoutingFactor" SG_ 2214658051 ACC_DnShftCtrlReq 5;
BA_ "Version" SG_ 2214658051 ACC_DnShftCtrlReq "17.12.00";
BA_ "Description" SG_ 2214658050 ENG_Ack4EngStpSta "The signal specifies the acknowledgement of the request for the operating state 'engine stopped'.";
BA_ "UserSigValidity" SG_ 2214658050 ENG_Ack4EngStpSta 3;
BA_ "RoutingFactor" SG_ 2214658050 ENG_Ack4EngStpSta 5;
BA_ "Version" SG_ 2214658050 ENG_Ack4EngStpSta "17.12.00";
BA_ "Description" SG_ 2214658050 ENG_AccDrvAlertDisp "If EMS sends the No Auto cruise engaged status or Auto cruise Disengaged status, 

Cluster shall display the status of Auto cruise.";
BA_ "TimeoutValue" SG_ 2214658050 ENG_AccDrvAlertDisp "0x0";
BA_ "UserSigValidity" SG_ 2214658050 ENG_AccDrvAlertDisp 3;
BA_ "RoutingFactor" SG_ 2214658050 ENG_AccDrvAlertDisp 5;
BA_ "Version" SG_ 2214658050 ENG_AccDrvAlertDisp "19.12.08";
BA_ "Description" SG_ 2214658050 DSL_GlowCtrlReq "This signal indicates that a diesel ECU requests ISS system to control glow plugs. 



If the EMS does not support this signal the value is 00H";
BA_ "UserSigValidity" SG_ 2214658050 DSL_GlowCtrlReq 3;
BA_ "RoutingFactor" SG_ 2214658050 DSL_GlowCtrlReq 5;
BA_ "Version" SG_ 2214658050 DSL_GlowCtrlReq "17.12.00";
BA_ "Description" SG_ 2214658050 ENG_GlowLmpSta "This signal indicates that a status of glow lamp.



This signal is used for a Diesel or LPI Engine alternatively.";
BA_ "GenSigStartValue" SG_ 2214658050 ENG_GlowLmpSta 1;
BA_ "UserSigValidity" SG_ 2214658050 ENG_GlowLmpSta 3;
BA_ "RoutingFactor" SG_ 2214658050 ENG_GlowLmpSta 5;
BA_ "Version" SG_ 2214658050 ENG_GlowLmpSta "17.12.00";
BA_ "Description" SG_ 2214658050 ENG_ThrPosVal "The signal TPS is a measure of the throttle position.

The throttle position is determined via a potentiometer, which is connected mechanically to the throttle shaft. The voltage value, which is adjusted in the port via the voltage divider, is sensed in ";
BA_ "GenSigStartValue" SG_ 2214658050 ENG_ThrPosVal 32;
BA_ "UserSigValidity" SG_ 2214658050 ENG_ThrPosVal 3;
BA_ "RoutingFactor" SG_ 2214658050 ENG_ThrPosVal 5;
BA_ "Version" SG_ 2214658050 ENG_ThrPosVal "17.12.00";
BA_ "Description" SG_ 2214658050 ENG_OverDrvOffReq "This signal indicates that auto cruise control function requests over drive off of TCU. 

In general, the over drive off request is done by hardware. (i.e. line-to-line signal between an EMS and a TCU). However, some systems may not have external over dr";
BA_ "UserSigValidity" SG_ 2214658050 ENG_OverDrvOffReq 3;
BA_ "RoutingFactor" SG_ 2214658050 ENG_OverDrvOffReq 5;
BA_ "Version" SG_ 2214658050 ENG_OverDrvOffReq "17.12.00";
BA_ "Description" SG_ 2214658050 ENG_AccelPdlVal "The signal PV_AV_CAN is a measure of the Accelerator Pedal value.

The accelerator pedal value is determined via 2 pedal sensors, which are connected mechanically to the

accelerator pedal. If the EMS-ECU recognizes that the accelerator pedal is not acti";
BA_ "UserSigValidity" SG_ 2214658050 ENG_AccelPdlVal 3;
BA_ "RoutingFactor" SG_ 2214658050 ENG_AccelPdlVal 5;
BA_ "Version" SG_ 2214658050 ENG_AccelPdlVal "18.01.01";
BA_ "Description" SG_ 2214658050 ENG_AccActSta "EMS sends the state of the cruise control via the signal ACC_ACT. 

If the EMS does not support this signal the value is 00H



If the cruise control is activated then ACC_ACT = 1. In this period, vehicle speed control (cruise control) is performed by th";
BA_ "UserSigValidity" SG_ 2214658050 ENG_AccActSta 3;
BA_ "RoutingFactor" SG_ 2214658050 ENG_AccActSta 5;
BA_ "Version" SG_ 2214658050 ENG_AccActSta "17.12.00";
BA_ "Description" SG_ 2214658050 ACC_CrsMainSwLmpSta "This signal indicates that an ECU requests cluster to turn on/off auto-cruise control ¡°MAIN¡± switch indication lamp.



This signal is for the CAN-type cluster installed vehicled only.";
BA_ "UserSigValidity" SG_ 2214658050 ACC_CrsMainSwLmpSta 3;
BA_ "RoutingFactor" SG_ 2214658050 ACC_CrsMainSwLmpSta 5;
BA_ "Version" SG_ 2214658050 ACC_CrsMainSwLmpSta "17.12.00";
BA_ "Description" SG_ 2214658050 ACC_CrsSetSwLmpSta "This signal indicates that an ECU requests cluster to turn on/off auto-cruise control ¡°SET¡± switch indication lamp.



This signal is for the CAN-type cluster installed vehicled only.";
BA_ "UserSigValidity" SG_ 2214658050 ACC_CrsSetSwLmpSta 3;
BA_ "RoutingFactor" SG_ 2214658050 ACC_CrsSetSwLmpSta 5;
BA_ "Version" SG_ 2214658050 ACC_CrsSetSwLmpSta "17.12.00";
BA_ "Description" SG_ 2214658050 ENG_LV_FUP_ENA_THD "The signal indicates that the status of the pressure on fuel rail is enough high to start engine.

(LPI)";
BA_ "UserSigValidity" SG_ 2214658050 ENG_LV_FUP_ENA_THD 3;
BA_ "RoutingFactor" SG_ 2214658050 ENG_LV_FUP_ENA_THD 5;
BA_ "Version" SG_ 2214658050 ENG_LV_FUP_ENA_THD "18.12.01";
BA_ "Description" SG_ 2214658050 ENG_SoakTimeErrSta "This signal indicates that information on soak time error.";
BA_ "UserSigValidity" SG_ 2214658050 ENG_SoakTimeErrSta 3;
BA_ "RoutingFactor" SG_ 2214658050 ENG_SoakTimeErrSta 5;
BA_ "Version" SG_ 2214658050 ENG_SoakTimeErrSta "17.12.00";
BA_ "Description" SG_ 2214658050 ENG_SoakTimeVal "The Signal SOAK_TIME means the duration from Engine Ignition Off to Ignition On.";
BA_ "UserSigValidity" SG_ 2214658050 ENG_SoakTimeVal 3;
BA_ "RoutingFactor" SG_ 2214658050 ENG_SoakTimeVal 5;
BA_ "Version" SG_ 2214658050 ENG_SoakTimeVal "17.12.00";
BA_ "Description" SG_ 2214658050 ENG_SprkTimeVal "This signal indicates output value of final spark timing from ECU which reflects torque intervention requests by ESC(TCS), SCC and TCU.



Physical range:

-35.625¢ª ¡¦ 0¢ª  =  00H .. 5FH (Retard)

0.375¢ª ¡¦ 60¢ª  =  60H .. FFH (Advance) 



Conversion:";
BA_ "UserSigValidity" SG_ 2214658050 ENG_SprkTimeVal 3;
BA_ "RoutingFactor" SG_ 2214658050 ENG_SprkTimeVal 5;
BA_ "Version" SG_ 2214658050 ENG_SprkTimeVal "17.12.00";
BA_ "Description" SG_ 2214658050 ENG_CltchOpSta "This signal indicates that ECU has detected an operation of a clutch. Using this signal an ISG (Idle Stop & Go) system acts as an alternator or a starter.



If the EMS does not support this signal the value is 00H";
BA_ "UserSigValidity" SG_ 2214658050 ENG_CltchOpSta 3;
BA_ "RoutingFactor" SG_ 2214658050 ENG_CltchOpSta 5;
BA_ "Version" SG_ 2214658050 ENG_CltchOpSta "17.12.00";
BA_ "Description" SG_ 2214658050 EMS_BrkReq_Slope "Brake request at slope for anti-stall";
BA_ "UserSigValidity" SG_ 2214658050 EMS_BrkReq_Slope 3;
BA_ "RoutingFactor" SG_ 2214658050 EMS_BrkReq_Slope 5;
BA_ "Version" SG_ 2214658050 EMS_BrkReq_Slope "20.04.06";
BA_ "Description" SG_ 623 ATS_ARSOpenCloseStatus "ÈÄ¼® ¾Ï·¹½ºÆ® ¿­¸²/´ÝÈû »óÅÂ ½ÅÈ£";
BA_ "GenSigSendType" SG_ 623 ATS_ARSOpenCloseStatus 4;
BA_ "UserSigValidity" SG_ 623 ATS_ARSOpenCloseStatus 3;
BA_ "NetworkRequest" SG_ 623 ATS_ARSOpenCloseStatus 0;
BA_ "NetworkRequestHoldingTime" SG_ 623 ATS_ARSOpenCloseStatus 5000;
BA_ "Version" SG_ 623 ATS_ARSOpenCloseStatus "20.12.05";
BA_ "Description" SG_ 623 ATS_RLLumbarDefBtn "ÈÄ¼® LH ·³¹ö ¹è±â ÀÛµ¿";
BA_ "GenSigSendType" SG_ 623 ATS_RLLumbarDefBtn 4;
BA_ "UserSigValidity" SG_ 623 ATS_RLLumbarDefBtn 3;
BA_ "NetworkRequest" SG_ 623 ATS_RLLumbarDefBtn 0;
BA_ "NetworkRequestHoldingTime" SG_ 623 ATS_RLLumbarDefBtn 5000;
BA_ "Version" SG_ 623 ATS_RLLumbarDefBtn "19.09.02";
BA_ "Description" SG_ 623 ATS_RLLumbarLowBtn "ÈÄ¼® LH ·³¹ö LOW ÀÛµ¿";
BA_ "GenSigSendType" SG_ 623 ATS_RLLumbarLowBtn 4;
BA_ "UserSigValidity" SG_ 623 ATS_RLLumbarLowBtn 3;
BA_ "NetworkRequest" SG_ 623 ATS_RLLumbarLowBtn 0;
BA_ "NetworkRequestHoldingTime" SG_ 623 ATS_RLLumbarLowBtn 5000;
BA_ "Version" SG_ 623 ATS_RLLumbarLowBtn "19.09.02";
BA_ "Description" SG_ 623 ATS_RLLumbarMidBtn "ÈÄ¼® LH ·³¹ö MID ÀÛµ¿";
BA_ "GenSigSendType" SG_ 623 ATS_RLLumbarMidBtn 4;
BA_ "UserSigValidity" SG_ 623 ATS_RLLumbarMidBtn 3;
BA_ "NetworkRequest" SG_ 623 ATS_RLLumbarMidBtn 0;
BA_ "NetworkRequestHoldingTime" SG_ 623 ATS_RLLumbarMidBtn 5000;
BA_ "Version" SG_ 623 ATS_RLLumbarMidBtn "19.09.02";
BA_ "Description" SG_ 623 ATS_RLLumbarUpBtn "ÈÄ¼® LH ·³¹ö UP ÀÛµ¿";
BA_ "GenSigSendType" SG_ 623 ATS_RLLumbarUpBtn 4;
BA_ "UserSigValidity" SG_ 623 ATS_RLLumbarUpBtn 3;
BA_ "NetworkRequest" SG_ 623 ATS_RLLumbarUpBtn 0;
BA_ "NetworkRequestHoldingTime" SG_ 623 ATS_RLLumbarUpBtn 5000;
BA_ "Version" SG_ 623 ATS_RLLumbarUpBtn "19.09.02";
BA_ "Description" SG_ 623 ATS_RLBolsterDefBtn "ÈÄ¼® LH º¼½ºÅÍ ¹è±â ÀÛµ¿";
BA_ "GenSigSendType" SG_ 623 ATS_RLBolsterDefBtn 4;
BA_ "UserSigValidity" SG_ 623 ATS_RLBolsterDefBtn 3;
BA_ "NetworkRequest" SG_ 623 ATS_RLBolsterDefBtn 0;
BA_ "NetworkRequestHoldingTime" SG_ 623 ATS_RLBolsterDefBtn 5000;
BA_ "Version" SG_ 623 ATS_RLBolsterDefBtn "19.09.02";
BA_ "Description" SG_ 623 ATS_RLBolsterInfSw "ÈÄ¼® LH º¼½ºÅÍ Èí±â ÀÛµ¿";
BA_ "GenSigSendType" SG_ 623 ATS_RLBolsterInfSw 4;
BA_ "UserSigValidity" SG_ 623 ATS_RLBolsterInfSw 3;
BA_ "NetworkRequest" SG_ 623 ATS_RLBolsterInfSw 0;
BA_ "NetworkRequestHoldingTime" SG_ 623 ATS_RLBolsterInfSw 5000;
BA_ "Version" SG_ 623 ATS_RLBolsterInfSw "19.09.02";
BA_ "Description" SG_ 623 ATS_RRLumbarDefBtn "ÈÄ¼® LH ·³¹ö ¹è±â ÀÛµ¿";
BA_ "GenSigSendType" SG_ 623 ATS_RRLumbarDefBtn 4;
BA_ "UserSigValidity" SG_ 623 ATS_RRLumbarDefBtn 3;
BA_ "NetworkRequest" SG_ 623 ATS_RRLumbarDefBtn 0;
BA_ "NetworkRequestHoldingTime" SG_ 623 ATS_RRLumbarDefBtn 5000;
BA_ "Version" SG_ 623 ATS_RRLumbarDefBtn "19.09.02";
BA_ "Description" SG_ 623 ATS_RRLumbarLowBtn "ÈÄ¼® RH ·³¹ö LOW ÀÛµ¿";
BA_ "GenSigSendType" SG_ 623 ATS_RRLumbarLowBtn 4;
BA_ "UserSigValidity" SG_ 623 ATS_RRLumbarLowBtn 3;
BA_ "NetworkRequest" SG_ 623 ATS_RRLumbarLowBtn 0;
BA_ "NetworkRequestHoldingTime" SG_ 623 ATS_RRLumbarLowBtn 5000;
BA_ "Version" SG_ 623 ATS_RRLumbarLowBtn "19.09.02";
BA_ "Description" SG_ 623 ATS_RRLumbarMidBtn "ÈÄ¼® RH ·³¹ö MID ÀÛµ¿";
BA_ "GenSigSendType" SG_ 623 ATS_RRLumbarMidBtn 4;
BA_ "UserSigValidity" SG_ 623 ATS_RRLumbarMidBtn 3;
BA_ "NetworkRequest" SG_ 623 ATS_RRLumbarMidBtn 0;
BA_ "NetworkRequestHoldingTime" SG_ 623 ATS_RRLumbarMidBtn 5000;
BA_ "Version" SG_ 623 ATS_RRLumbarMidBtn "19.09.02";
BA_ "Description" SG_ 623 ATS_RRLumbarUpBtn "ÈÄ¼® RH ·³¹ö UP ÀÛµ¿";
BA_ "GenSigSendType" SG_ 623 ATS_RRLumbarUpBtn 4;
BA_ "UserSigValidity" SG_ 623 ATS_RRLumbarUpBtn 3;
BA_ "NetworkRequest" SG_ 623 ATS_RRLumbarUpBtn 0;
BA_ "NetworkRequestHoldingTime" SG_ 623 ATS_RRLumbarUpBtn 5000;
BA_ "Version" SG_ 623 ATS_RRLumbarUpBtn "19.09.02";
BA_ "Description" SG_ 623 ATS_RRBolsterDefBtn "ÈÄ¼® RH º¼½ºÅÍ ¹è±â ÀÛµ¿";
BA_ "GenSigSendType" SG_ 623 ATS_RRBolsterDefBtn 4;
BA_ "UserSigValidity" SG_ 623 ATS_RRBolsterDefBtn 3;
BA_ "NetworkRequest" SG_ 623 ATS_RRBolsterDefBtn 0;
BA_ "NetworkRequestHoldingTime" SG_ 623 ATS_RRBolsterDefBtn 5000;
BA_ "Version" SG_ 623 ATS_RRBolsterDefBtn "19.09.02";
BA_ "Description" SG_ 623 ATS_RRBolsterInfSw "ÈÄ¼® RH º¼½ºÅÍ Èí±â ÀÛµ¿";
BA_ "GenSigSendType" SG_ 623 ATS_RRBolsterInfSw 4;
BA_ "UserSigValidity" SG_ 623 ATS_RRBolsterInfSw 3;
BA_ "NetworkRequest" SG_ 623 ATS_RRBolsterInfSw 0;
BA_ "NetworkRequestHoldingTime" SG_ 623 ATS_RRBolsterInfSw 5000;
BA_ "Version" SG_ 623 ATS_RRBolsterInfSw "19.09.02";
BA_ "Description" SG_ 639 ATS_RRSeatHeaterSW "ÈÄ¼® RH ½ÃÆ® ¿­¼± Á¶Àý";
BA_ "GenSigSendType" SG_ 639 ATS_RRSeatHeaterSW 4;
BA_ "UserSigValidity" SG_ 639 ATS_RRSeatHeaterSW 3;
BA_ "NetworkRequest" SG_ 639 ATS_RRSeatHeaterSW 0;
BA_ "NetworkRequestHoldingTime" SG_ 639 ATS_RRSeatHeaterSW 5000;
BA_ "Version" SG_ 639 ATS_RRSeatHeaterSW "20.07.01";
BA_ "Description" SG_ 639 ATS_RLSeatHeaterUpSW "ÈÄ¼® LH ½ÃÆ® ¿­¼± Á¶Àý";
BA_ "GenSigSendType" SG_ 639 ATS_RLSeatHeaterUpSW 4;
BA_ "UserSigValidity" SG_ 639 ATS_RLSeatHeaterUpSW 3;
BA_ "NetworkRequest" SG_ 639 ATS_RLSeatHeaterUpSW 0;
BA_ "NetworkRequestHoldingTime" SG_ 639 ATS_RLSeatHeaterUpSW 5000;
BA_ "Version" SG_ 639 ATS_RLSeatHeaterUpSW "20.12.04";
BA_ "Description" SG_ 639 ATS_RRSeatVentDownSW "ÈÄ¼® RH ½ÃÆ® ÅëÇ³ Á¶Àý";
BA_ "GenSigSendType" SG_ 639 ATS_RRSeatVentDownSW 4;
BA_ "UserSigValidity" SG_ 639 ATS_RRSeatVentDownSW 3;
BA_ "NetworkRequest" SG_ 639 ATS_RRSeatVentDownSW 0;
BA_ "NetworkRequestHoldingTime" SG_ 639 ATS_RRSeatVentDownSW 5000;
BA_ "Version" SG_ 639 ATS_RRSeatVentDownSW "20.12.04";
BA_ "Description" SG_ 639 ATS_RLSeatVentDownSW "ÈÄ¼® LH ½ÃÆ® ÅëÇ³ Á¶Àý";
BA_ "GenSigSendType" SG_ 639 ATS_RLSeatVentDownSW 4;
BA_ "UserSigValidity" SG_ 639 ATS_RLSeatVentDownSW 3;
BA_ "NetworkRequest" SG_ 639 ATS_RLSeatVentDownSW 0;
BA_ "NetworkRequestHoldingTime" SG_ 639 ATS_RLSeatVentDownSW 5000;
BA_ "Version" SG_ 639 ATS_RLSeatVentDownSW "20.12.04";
BA_ "Description" SG_ 639 ATS_RLMemoryRestBtn "Rear Left Rest Mode Custom Save Button (Except North America)";
BA_ "GenSigSendType" SG_ 639 ATS_RLMemoryRestBtn 4;
BA_ "UserSigValidity" SG_ 639 ATS_RLMemoryRestBtn 3;
BA_ "NetworkRequest" SG_ 639 ATS_RLMemoryRestBtn 0;
BA_ "NetworkRequestHoldingTime" SG_ 639 ATS_RLMemoryRestBtn 5000;
BA_ "Version" SG_ 639 ATS_RLMemoryRestBtn "21.01.02";
BA_ "Description" SG_ 639 ATS_RLMemoryReturnBtn "Rear Left Return Mode Custom Save Button (Except North America)";
BA_ "GenSigSendType" SG_ 639 ATS_RLMemoryReturnBtn 4;
BA_ "UserSigValidity" SG_ 639 ATS_RLMemoryReturnBtn 3;
BA_ "NetworkRequest" SG_ 639 ATS_RLMemoryReturnBtn 0;
BA_ "NetworkRequestHoldingTime" SG_ 639 ATS_RLMemoryReturnBtn 5000;
BA_ "Version" SG_ 639 ATS_RLMemoryReturnBtn "21.01.02";
BA_ "Description" SG_ 639 ATS_RLSeatHeaterSW "ÈÄ¼® LH ½ÃÆ® ¿­¼± Á¶Àý";
BA_ "GenSigSendType" SG_ 639 ATS_RLSeatHeaterSW 4;
BA_ "UserSigValidity" SG_ 639 ATS_RLSeatHeaterSW 3;
BA_ "NetworkRequest" SG_ 639 ATS_RLSeatHeaterSW 0;
BA_ "NetworkRequestHoldingTime" SG_ 639 ATS_RLSeatHeaterSW 5000;
BA_ "Version" SG_ 639 ATS_RLSeatHeaterSW "20.07.01";
BA_ "Description" SG_ 639 ATS_RRMemoryRestBtn "Rear Right Rest Mode Custom Save Button (Except North America)";
BA_ "GenSigSendType" SG_ 639 ATS_RRMemoryRestBtn 4;
BA_ "UserSigValidity" SG_ 639 ATS_RRMemoryRestBtn 3;
BA_ "NetworkRequest" SG_ 639 ATS_RRMemoryRestBtn 0;
BA_ "NetworkRequestHoldingTime" SG_ 639 ATS_RRMemoryRestBtn 5000;
BA_ "Version" SG_ 639 ATS_RRMemoryRestBtn "21.01.02";
BA_ "Description" SG_ 639 ATS_RRMemoryReturnBtn "Rear Right Return Mode Custom Save Button (Except North America)";
BA_ "GenSigSendType" SG_ 639 ATS_RRMemoryReturnBtn 4;
BA_ "UserSigValidity" SG_ 639 ATS_RRMemoryReturnBtn 3;
BA_ "NetworkRequest" SG_ 639 ATS_RRMemoryReturnBtn 0;
BA_ "NetworkRequestHoldingTime" SG_ 639 ATS_RRMemoryReturnBtn 5000;
BA_ "Version" SG_ 639 ATS_RRMemoryReturnBtn "21.01.02";
BA_ "Description" SG_ 639 ATS_RRMemoryAvWtcBtn "Rear Right AV Watching Mode Custom Save Button (Except North America)";
BA_ "GenSigSendType" SG_ 639 ATS_RRMemoryAvWtcBtn 4;
BA_ "UserSigValidity" SG_ 639 ATS_RRMemoryAvWtcBtn 3;
BA_ "NetworkRequest" SG_ 639 ATS_RRMemoryAvWtcBtn 0;
BA_ "NetworkRequestHoldingTime" SG_ 639 ATS_RRMemoryAvWtcBtn 5000;
BA_ "Version" SG_ 639 ATS_RRMemoryAvWtcBtn "21.01.02";
BA_ "Description" SG_ 639 ATS_RRMemoryReadingBtn "Rear Right Reading Mode Custom Save Button (Except North America)";
BA_ "GenSigSendType" SG_ 639 ATS_RRMemoryReadingBtn 4;
BA_ "UserSigValidity" SG_ 639 ATS_RRMemoryReadingBtn 3;
BA_ "NetworkRequest" SG_ 639 ATS_RRMemoryReadingBtn 0;
BA_ "NetworkRequestHoldingTime" SG_ 639 ATS_RRMemoryReadingBtn 5000;
BA_ "Version" SG_ 639 ATS_RRMemoryReadingBtn "21.01.02";
BA_ "Description" SG_ 639 ATS_RRRestModBtnSTD "Rear Right Rest Mode Touch Button (EXCEPT North America)";
BA_ "GenSigSendType" SG_ 639 ATS_RRRestModBtnSTD 4;
BA_ "UserSigValidity" SG_ 639 ATS_RRRestModBtnSTD 3;
BA_ "NetworkRequest" SG_ 639 ATS_RRRestModBtnSTD 0;
BA_ "NetworkRequestHoldingTime" SG_ 639 ATS_RRRestModBtnSTD 5000;
BA_ "Version" SG_ 639 ATS_RRRestModBtnSTD "20.07.01";
BA_ "Description" SG_ 639 ATS_RRResetModBtnSTD "Rear Right Return Mode Touch Button (EXCEPT North America)";
BA_ "GenSigSendType" SG_ 639 ATS_RRResetModBtnSTD 4;
BA_ "UserSigValidity" SG_ 639 ATS_RRResetModBtnSTD 3;
BA_ "NetworkRequest" SG_ 639 ATS_RRResetModBtnSTD 0;
BA_ "NetworkRequestHoldingTime" SG_ 639 ATS_RRResetModBtnSTD 5000;
BA_ "Version" SG_ 639 ATS_RRResetModBtnSTD "20.07.01";
BA_ "Description" SG_ 639 ATS_RRAvWtcModBtnSTD "Rear Right AV Watching Mode Touch Button (EXCEPT North America)";
BA_ "GenSigSendType" SG_ 639 ATS_RRAvWtcModBtnSTD 4;
BA_ "UserSigValidity" SG_ 639 ATS_RRAvWtcModBtnSTD 3;
BA_ "NetworkRequest" SG_ 639 ATS_RRAvWtcModBtnSTD 0;
BA_ "NetworkRequestHoldingTime" SG_ 639 ATS_RRAvWtcModBtnSTD 5000;
BA_ "Version" SG_ 639 ATS_RRAvWtcModBtnSTD "20.07.01";
BA_ "Description" SG_ 639 ATS_RRReadingModBtnSTD "Rear Right Reading Mode Touch Button (EXCEPT North America)";
BA_ "GenSigSendType" SG_ 639 ATS_RRReadingModBtnSTD 4;
BA_ "UserSigValidity" SG_ 639 ATS_RRReadingModBtnSTD 3;
BA_ "NetworkRequest" SG_ 639 ATS_RRReadingModBtnSTD 0;
BA_ "NetworkRequestHoldingTime" SG_ 639 ATS_RRReadingModBtnSTD 5000;
BA_ "Version" SG_ 639 ATS_RRReadingModBtnSTD "20.07.01";
BA_ "Description" SG_ 639 ATS_RRSeatVentSW "ÈÄ¼® RH ½ÃÆ® ÅëÇ³ Á¶Àý";
BA_ "GenSigSendType" SG_ 639 ATS_RRSeatVentSW 4;
BA_ "UserSigValidity" SG_ 639 ATS_RRSeatVentSW 3;
BA_ "NetworkRequest" SG_ 639 ATS_RRSeatVentSW 0;
BA_ "NetworkRequestHoldingTime" SG_ 639 ATS_RRSeatVentSW 5000;
BA_ "Version" SG_ 639 ATS_RRSeatVentSW "20.07.01";
BA_ "Description" SG_ 639 ATS_RLRestModBtnSTD "Rear Left Rest Mode Touch Button (EXCEPT North America)";
BA_ "GenSigSendType" SG_ 639 ATS_RLRestModBtnSTD 4;
BA_ "UserSigValidity" SG_ 639 ATS_RLRestModBtnSTD 3;
BA_ "NetworkRequest" SG_ 639 ATS_RLRestModBtnSTD 0;
BA_ "NetworkRequestHoldingTime" SG_ 639 ATS_RLRestModBtnSTD 5000;
BA_ "Version" SG_ 639 ATS_RLRestModBtnSTD "20.07.01";
BA_ "Description" SG_ 639 ATS_RLResetModBtnSTD "Rear Left Return Mode Touch Button (EXCEPT North America)";
BA_ "GenSigSendType" SG_ 639 ATS_RLResetModBtnSTD 4;
BA_ "UserSigValidity" SG_ 639 ATS_RLResetModBtnSTD 3;
BA_ "NetworkRequest" SG_ 639 ATS_RLResetModBtnSTD 0;
BA_ "NetworkRequestHoldingTime" SG_ 639 ATS_RLResetModBtnSTD 5000;
BA_ "Version" SG_ 639 ATS_RLResetModBtnSTD "20.07.01";
BA_ "Description" SG_ 639 ATS_RRModestateStopBtn "Rear Right One touch mode Stop Button";
BA_ "GenSigSendType" SG_ 639 ATS_RRModestateStopBtn 4;
BA_ "UserSigValidity" SG_ 639 ATS_RRModestateStopBtn 3;
BA_ "NetworkRequest" SG_ 639 ATS_RRModestateStopBtn 0;
BA_ "NetworkRequestHoldingTime" SG_ 639 ATS_RRModestateStopBtn 5000;
BA_ "Version" SG_ 639 ATS_RRModestateStopBtn "20.07.01";
BA_ "Description" SG_ 639 ATS_RLModestateStopBtn "Rear Left One touch mode Stop Button";
BA_ "GenSigSendType" SG_ 639 ATS_RLModestateStopBtn 4;
BA_ "UserSigValidity" SG_ 639 ATS_RLModestateStopBtn 3;
BA_ "NetworkRequest" SG_ 639 ATS_RLModestateStopBtn 0;
BA_ "NetworkRequestHoldingTime" SG_ 639 ATS_RLModestateStopBtn 5000;
BA_ "Version" SG_ 639 ATS_RLModestateStopBtn "20.07.01";
BA_ "Description" SG_ 639 ATS_RLResetRestBtn "Rear Left Rest Mode Custom Initialization Button (Except North America)";
BA_ "GenSigSendType" SG_ 639 ATS_RLResetRestBtn 4;
BA_ "UserSigValidity" SG_ 639 ATS_RLResetRestBtn 3;
BA_ "NetworkRequest" SG_ 639 ATS_RLResetRestBtn 0;
BA_ "NetworkRequestHoldingTime" SG_ 639 ATS_RLResetRestBtn 5000;
BA_ "Version" SG_ 639 ATS_RLResetRestBtn "21.01.02";
BA_ "Description" SG_ 639 ATS_RLResetReturnBtn "Rear Left Return Mode Custom Initialization Button (Except North America)";
BA_ "GenSigSendType" SG_ 639 ATS_RLResetReturnBtn 4;
BA_ "UserSigValidity" SG_ 639 ATS_RLResetReturnBtn 3;
BA_ "NetworkRequest" SG_ 639 ATS_RLResetReturnBtn 0;
BA_ "NetworkRequestHoldingTime" SG_ 639 ATS_RLResetReturnBtn 5000;
BA_ "Version" SG_ 639 ATS_RLResetReturnBtn "21.01.02";
BA_ "Description" SG_ 639 ATS_RRResetRestBtn "Rear Right Rest Mode Custom Initialization Button (Except North America)";
BA_ "GenSigSendType" SG_ 639 ATS_RRResetRestBtn 4;
BA_ "UserSigValidity" SG_ 639 ATS_RRResetRestBtn 3;
BA_ "NetworkRequest" SG_ 639 ATS_RRResetRestBtn 0;
BA_ "NetworkRequestHoldingTime" SG_ 639 ATS_RRResetRestBtn 5000;
BA_ "Version" SG_ 639 ATS_RRResetRestBtn "21.01.02";
BA_ "Description" SG_ 639 ATS_RRResetReturnBtn "Rear Right Return Mode Custom Initialization Button (Except North America)";
BA_ "GenSigSendType" SG_ 639 ATS_RRResetReturnBtn 4;
BA_ "UserSigValidity" SG_ 639 ATS_RRResetReturnBtn 3;
BA_ "NetworkRequest" SG_ 639 ATS_RRResetReturnBtn 0;
BA_ "NetworkRequestHoldingTime" SG_ 639 ATS_RRResetReturnBtn 5000;
BA_ "Version" SG_ 639 ATS_RRResetReturnBtn "21.01.02";
BA_ "Description" SG_ 639 ATS_RRResetAvWtcBtn "Rear Right AV Watching Mode Custom Initialization Button (Except North America)";
BA_ "GenSigSendType" SG_ 639 ATS_RRResetAvWtcBtn 4;
BA_ "UserSigValidity" SG_ 639 ATS_RRResetAvWtcBtn 3;
BA_ "NetworkRequest" SG_ 639 ATS_RRResetAvWtcBtn 0;
BA_ "NetworkRequestHoldingTime" SG_ 639 ATS_RRResetAvWtcBtn 5000;
BA_ "Version" SG_ 639 ATS_RRResetAvWtcBtn "21.01.02";
BA_ "Description" SG_ 639 ATS_RRResetReadingBtn "Rear Right Reading Mode Custom Initialization Button (Except North America)";
BA_ "GenSigSendType" SG_ 639 ATS_RRResetReadingBtn 4;
BA_ "UserSigValidity" SG_ 639 ATS_RRResetReadingBtn 3;
BA_ "NetworkRequest" SG_ 639 ATS_RRResetReadingBtn 0;
BA_ "NetworkRequestHoldingTime" SG_ 639 ATS_RRResetReadingBtn 5000;
BA_ "Version" SG_ 639 ATS_RRResetReadingBtn "21.01.02";
BA_ "Description" SG_ 639 ATS_RLSeatVentSW "ÈÄ¼® LH ½ÃÆ® ÅëÇ³ Á¶Àý";
BA_ "GenSigSendType" SG_ 639 ATS_RLSeatVentSW 4;
BA_ "UserSigValidity" SG_ 639 ATS_RLSeatVentSW 3;
BA_ "NetworkRequest" SG_ 639 ATS_RLSeatVentSW 0;
BA_ "NetworkRequestHoldingTime" SG_ 639 ATS_RLSeatVentSW 5000;
BA_ "Version" SG_ 639 ATS_RLSeatVentSW "20.07.01";
BA_ "Description" SG_ 639 ATS_RRSeatHeaterUpSW "ÈÄ¼® RH ½ÃÆ® ¿­¼± Á¶Àý";
BA_ "GenSigSendType" SG_ 639 ATS_RRSeatHeaterUpSW 4;
BA_ "UserSigValidity" SG_ 639 ATS_RRSeatHeaterUpSW 3;
BA_ "NetworkRequest" SG_ 639 ATS_RRSeatHeaterUpSW 0;
BA_ "NetworkRequestHoldingTime" SG_ 639 ATS_RRSeatHeaterUpSW 5000;
BA_ "Version" SG_ 639 ATS_RRSeatHeaterUpSW "20.12.04";
BA_ "Description" SG_ 1584 AMP_NaviWarnSound "Navi Warning prompt on/off

Only ON during the Navi Warning Sound Playing

Default : Off

-This Signal's Feedback is AMP_NaviWarnModeState@AMP";
BA_ "GenSigSendType" SG_ 1584 AMP_NaviWarnSound 4;
BA_ "GenSigStartValue" SG_ 1584 AMP_NaviWarnSound 3;
BA_ "UserSigValidity" SG_ 1584 AMP_NaviWarnSound 1;
BA_ "Version" SG_ 1584 AMP_NaviWarnSound "21.04.10";
BA_ "Description" SG_ 1584 AMP_Beep1Mode "16.02.05_[Default Value]

0x0";
BA_ "GenSigSendType" SG_ 1584 AMP_Beep1Mode 4;
BA_ "GenSigStartValue" SG_ 1584 AMP_Beep1Mode 3;
BA_ "UserSigValidity" SG_ 1584 AMP_Beep1Mode 1;
BA_ "NetworkRequest" SG_ 1584 AMP_Beep1Mode 0;
BA_ "Version" SG_ 1584 AMP_Beep1Mode "18.12.06";
BA_ "Description" SG_ 1584 AMP_MasterBeepVolumeStep "MasterBeepVolumeStep (0/1/2/3/4/5)";
BA_ "GenSigSendType" SG_ 1584 AMP_MasterBeepVolumeStep 4;
BA_ "GenSigStartValue" SG_ 1584 AMP_MasterBeepVolumeStep 7;
BA_ "UserSigValidity" SG_ 1584 AMP_MasterBeepVolumeStep 1;
BA_ "NetworkRequest" SG_ 1584 AMP_MasterBeepVolumeStep 0;
BA_ "Version" SG_ 1584 AMP_MasterBeepVolumeStep "20.08.02";
BA_ "Description" SG_ 1584 AMP_RrTTSSound "This signal is  Rear TTS output state information";
BA_ "GenSigSendType" SG_ 1584 AMP_RrTTSSound 4;
BA_ "GenSigStartValue" SG_ 1584 AMP_RrTTSSound 3;
BA_ "UserSigValidity" SG_ 1584 AMP_RrTTSSound 1;
BA_ "Version" SG_ 1584 AMP_RrTTSSound "19.12.01";
BA_ "Description" SG_ 1584 AMP_ASDMode "16.04.01_HI : default value 0x01

DH PE : default value 0x03 (this signal used for DH PE eng mode asd setting)";
BA_ "GenSigSendType" SG_ 1584 AMP_ASDMode 4;
BA_ "GenSigStartValue" SG_ 1584 AMP_ASDMode 7;
BA_ "UserSigValidity" SG_ 1584 AMP_ASDMode 1;
BA_ "NetworkRequest" SG_ 1584 AMP_ASDMode 0;
BA_ "Version" SG_ 1584 AMP_ASDMode "18.12.06";
BA_ "Description" SG_ 1584 AMP_ANCMode "18.03.08_";
BA_ "GenSigSendType" SG_ 1584 AMP_ANCMode 4;
BA_ "GenSigStartValue" SG_ 1584 AMP_ANCMode 3;
BA_ "UserSigValidity" SG_ 1584 AMP_ANCMode 1;
BA_ "Version" SG_ 1584 AMP_ANCMode "18.12.06";
BA_ "Description" SG_ 1584 AMP_VirtualVenueMode "Select VV mode";
BA_ "GenSigSendType" SG_ 1584 AMP_VirtualVenueMode 4;
BA_ "GenSigStartValue" SG_ 1584 AMP_VirtualVenueMode 7;
BA_ "UserSigValidity" SG_ 1584 AMP_VirtualVenueMode 1;
BA_ "NetworkRequest" SG_ 1584 AMP_VirtualVenueMode 0;
BA_ "Version" SG_ 1584 AMP_VirtualVenueMode "19.08.08";
BA_ "Description" SG_ 1584 AMP_QLIMode "Select QLI mode";
BA_ "GenSigSendType" SG_ 1584 AMP_QLIMode 4;
BA_ "GenSigStartValue" SG_ 1584 AMP_QLIMode 7;
BA_ "UserSigValidity" SG_ 1584 AMP_QLIMode 1;
BA_ "NetworkRequest" SG_ 1584 AMP_QLIMode 0;
BA_ "Version" SG_ 1584 AMP_QLIMode "19.08.08";
BA_ "Description" SG_ 1584 AMP_DriverMode "Turn On/Off Driver mode";
BA_ "GenSigSendType" SG_ 1584 AMP_DriverMode 4;
BA_ "GenSigStartValue" SG_ 1584 AMP_DriverMode 3;
BA_ "UserSigValidity" SG_ 1584 AMP_DriverMode 1;
BA_ "NetworkRequest" SG_ 1584 AMP_DriverMode 0;
BA_ "Version" SG_ 1584 AMP_DriverMode "19.08.08";
BA_ "Description" SG_ 1584 AMP_NaviSound "16.02.05_[Default Value]

0x0";
BA_ "GenSigSendType" SG_ 1584 AMP_NaviSound 4;
BA_ "GenSigStartValue" SG_ 1584 AMP_NaviSound 3;
BA_ "UserSigValidity" SG_ 1584 AMP_NaviSound 1;
BA_ "Version" SG_ 1584 AMP_NaviSound "19.01.05";
BA_ "Description" SG_ 1584 AMP_ETCSSound "ETCS sound on/off

Only ON during the ETCS sound playing

Default : Off

-This Signal's Feedback is AMP_ETCSModeState@AMP";
BA_ "GenSigSendType" SG_ 1584 AMP_ETCSSound 4;
BA_ "GenSigStartValue" SG_ 1584 AMP_ETCSSound 3;
BA_ "UserSigValidity" SG_ 1584 AMP_ETCSSound 1;
BA_ "Version" SG_ 1584 AMP_ETCSSound "22.05.02";
BA_ "Description" SG_ 1584 AMP_VoiceGuideTTS "Play VoiceGuide TTS";
BA_ "GenSigSendType" SG_ 1584 AMP_VoiceGuideTTS 4;
BA_ "GenSigStartValue" SG_ 1584 AMP_VoiceGuideTTS 3;
BA_ "UserSigValidity" SG_ 1584 AMP_VoiceGuideTTS 1;
BA_ "NetworkRequest" SG_ 1584 AMP_VoiceGuideTTS 0;
BA_ "Version" SG_ 1584 AMP_VoiceGuideTTS "19.08.08";
BA_ "Description" SG_ 1584 AMP_Beep1KBDMode "Play touch beep sound at keyboard screen on AVN

This Signal's Feedback is AMP_Beep1KBDModeState@AMP";
BA_ "GenSigSendType" SG_ 1584 AMP_Beep1KBDMode 4;
BA_ "GenSigStartValue" SG_ 1584 AMP_Beep1KBDMode 3;
BA_ "UserSigValidity" SG_ 1584 AMP_Beep1KBDMode 1;
BA_ "Version" SG_ 1584 AMP_Beep1KBDMode "20.06.01";
BA_ "Description" SG_ 1584 AMP_ETCSVolumeStep "- Command for ETCS Volume Setting

- This Signal's Feedback is AMP_ETCSVolumeState@AMP";
BA_ "GenSigSendType" SG_ 1584 AMP_ETCSVolumeStep 4;
BA_ "GenSigStartValue" SG_ 1584 AMP_ETCSVolumeStep 255;
BA_ "UserSigValidity" SG_ 1584 AMP_ETCSVolumeStep 1;
BA_ "Version" SG_ 1584 AMP_ETCSVolumeStep "22.05.02";
BA_ "Description" SG_ 1584 AMP_NaviWarnVolumeStep "- Command for Navigation Warning Prompt Volume Setting

- This Signal's Feedback is AMP_NaviWarnVolumeState@AMP";
BA_ "GenSigSendType" SG_ 1584 AMP_NaviWarnVolumeStep 4;
BA_ "GenSigStartValue" SG_ 1584 AMP_NaviWarnVolumeStep 255;
BA_ "UserSigValidity" SG_ 1584 AMP_NaviWarnVolumeStep 1;
BA_ "Version" SG_ 1584 AMP_NaviWarnVolumeStep "21.04.10";
BA_ "Description" SG_ 1584 AMP_TTSSound "This signal is  TTS output state information";
BA_ "GenSigSendType" SG_ 1584 AMP_TTSSound 4;
BA_ "GenSigStartValue" SG_ 1584 AMP_TTSSound 3;
BA_ "UserSigValidity" SG_ 1584 AMP_TTSSound 1;
BA_ "Version" SG_ 1584 AMP_TTSSound "19.07.06";
BA_ "Description" SG_ 1584 AMP_SDVCStep "16.02.05_";
BA_ "GenSigSendType" SG_ 1584 AMP_SDVCStep 4;
BA_ "UserSigValidity" SG_ 1584 AMP_SDVCStep 1;
BA_ "NetworkRequest" SG_ 1584 AMP_SDVCStep 0;
BA_ "Version" SG_ 1584 AMP_SDVCStep "18.12.06";
BA_ "GenSigSendType" SG_ 577 C_AstBolsterInfSw_HU 4;
BA_ "UserSigValidity" SG_ 577 C_AstBolsterInfSw_HU 0;
BA_ "Version" SG_ 577 C_AstBolsterInfSw_HU "19.11.09";
BA_ "GenSigSendType" SG_ 577 C_RLHrestUpSw_HU 4;
BA_ "UserSigValidity" SG_ 577 C_RLHrestUpSw_HU 0;
BA_ "Version" SG_ 577 C_RLHrestUpSw_HU "19.11.09";
BA_ "GenSigSendType" SG_ 577 C_RLHrestDnSw_HU 4;
BA_ "UserSigValidity" SG_ 577 C_RLHrestDnSw_HU 0;
BA_ "Version" SG_ 577 C_RLHrestDnSw_HU "19.11.09";
BA_ "GenSigSendType" SG_ 577 C_RLHrestFwdSw_HU 4;
BA_ "UserSigValidity" SG_ 577 C_RLHrestFwdSw_HU 0;
BA_ "Version" SG_ 577 C_RLHrestFwdSw_HU "19.11.09";
BA_ "GenSigSendType" SG_ 577 C_AstBolsterDefSw_HU 4;
BA_ "UserSigValidity" SG_ 577 C_AstBolsterDefSw_HU 0;
BA_ "Version" SG_ 577 C_AstBolsterDefSw_HU "19.11.09";
BA_ "GenSigSendType" SG_ 577 C_RLHrestBwdSw_HU 4;
BA_ "UserSigValidity" SG_ 577 C_RLHrestBwdSw_HU 0;
BA_ "Version" SG_ 577 C_RLHrestBwdSw_HU "19.11.09";
BA_ "GenSigSendType" SG_ 577 C_RLLumbarUpSw_HU 4;
BA_ "UserSigValidity" SG_ 577 C_RLLumbarUpSw_HU 0;
BA_ "Version" SG_ 577 C_RLLumbarUpSw_HU "19.11.09";
BA_ "GenSigSendType" SG_ 577 C_RLLumbarMidSw_HU 4;
BA_ "UserSigValidity" SG_ 577 C_RLLumbarMidSw_HU 0;
BA_ "Version" SG_ 577 C_RLLumbarMidSw_HU "19.11.09";
BA_ "GenSigSendType" SG_ 577 C_RLLumbarLowSw_HU 4;
BA_ "UserSigValidity" SG_ 577 C_RLLumbarLowSw_HU 0;
BA_ "Version" SG_ 577 C_RLLumbarLowSw_HU "19.11.09";
BA_ "GenSigSendType" SG_ 577 C_RLLumbarDefSw_HU 4;
BA_ "UserSigValidity" SG_ 577 C_RLLumbarDefSw_HU 0;
BA_ "Version" SG_ 577 C_RLLumbarDefSw_HU "19.11.09";
BA_ "GenSigSendType" SG_ 577 C_RLBolsterInfSw_HU 4;
BA_ "UserSigValidity" SG_ 577 C_RLBolsterInfSw_HU 0;
BA_ "Version" SG_ 577 C_RLBolsterInfSw_HU "19.11.09";
BA_ "GenSigSendType" SG_ 577 C_RLBolsterDefSw_HU 4;
BA_ "UserSigValidity" SG_ 577 C_RLBolsterDefSw_HU 0;
BA_ "Version" SG_ 577 C_RLBolsterDefSw_HU "19.11.09";
BA_ "GenSigSendType" SG_ 577 C_AstHrestUpSw_HU 4;
BA_ "UserSigValidity" SG_ 577 C_AstHrestUpSw_HU 0;
BA_ "Version" SG_ 577 C_AstHrestUpSw_HU "19.11.09";
BA_ "GenSigSendType" SG_ 577 C_AstHrestDnSw_HU 4;
BA_ "UserSigValidity" SG_ 577 C_AstHrestDnSw_HU 0;
BA_ "Version" SG_ 577 C_AstHrestDnSw_HU "19.11.09";
BA_ "GenSigSendType" SG_ 577 C_AstFootrestFldSw_HU 4;
BA_ "UserSigValidity" SG_ 577 C_AstFootrestFldSw_HU 0;
BA_ "Version" SG_ 577 C_AstFootrestFldSw_HU "19.11.09";
BA_ "GenSigSendType" SG_ 577 C_AstHrestFwdSw_HU 4;
BA_ "UserSigValidity" SG_ 577 C_AstHrestFwdSw_HU 0;
BA_ "Version" SG_ 577 C_AstHrestFwdSw_HU "19.11.09";
BA_ "GenSigSendType" SG_ 577 C_AstHrestBwdSw_HU 4;
BA_ "UserSigValidity" SG_ 577 C_AstHrestBwdSw_HU 0;
BA_ "Version" SG_ 577 C_AstHrestBwdSw_HU "19.11.09";
BA_ "GenSigSendType" SG_ 577 C_AstFootrestUnFldSw_HU 4;
BA_ "UserSigValidity" SG_ 577 C_AstFootrestUnFldSw_HU 0;
BA_ "Version" SG_ 577 C_AstFootrestUnFldSw_HU "19.11.09";
BA_ "GenSigSendType" SG_ 578 C_RRLegSupFwdSw_HU 4;
BA_ "UserSigValidity" SG_ 578 C_RRLegSupFwdSw_HU 0;
BA_ "Version" SG_ 578 C_RRLegSupFwdSw_HU "19.11.09";
BA_ "GenSigSendType" SG_ 578 C_RRHrestDnSw_HU 4;
BA_ "UserSigValidity" SG_ 578 C_RRHrestDnSw_HU 0;
BA_ "Version" SG_ 578 C_RRHrestDnSw_HU "19.11.09";
BA_ "GenSigSendType" SG_ 578 C_RRHrestFwdSw_HU 4;
BA_ "UserSigValidity" SG_ 578 C_RRHrestFwdSw_HU 0;
BA_ "Version" SG_ 578 C_RRHrestFwdSw_HU "19.11.09";
BA_ "GenSigSendType" SG_ 578 C_RRHrestBwdSw_HU 4;
BA_ "UserSigValidity" SG_ 578 C_RRHrestBwdSw_HU 0;
BA_ "Version" SG_ 578 C_RRHrestBwdSw_HU "19.11.09";
BA_ "GenSigSendType" SG_ 578 C_RRLumbarUpSw_HU 4;
BA_ "UserSigValidity" SG_ 578 C_RRLumbarUpSw_HU 0;
BA_ "Version" SG_ 578 C_RRLumbarUpSw_HU "19.11.09";
BA_ "GenSigSendType" SG_ 578 C_RRLumbarMidSw_HU 4;
BA_ "UserSigValidity" SG_ 578 C_RRLumbarMidSw_HU 0;
BA_ "Version" SG_ 578 C_RRLumbarMidSw_HU "19.11.09";
BA_ "GenSigSendType" SG_ 578 C_RRLegSupBwdSw_HU 4;
BA_ "UserSigValidity" SG_ 578 C_RRLegSupBwdSw_HU 0;
BA_ "Version" SG_ 578 C_RRLegSupBwdSw_HU "19.11.09";
BA_ "GenSigSendType" SG_ 578 C_RRLumbarLowSw_HU 4;
BA_ "UserSigValidity" SG_ 578 C_RRLumbarLowSw_HU 0;
BA_ "Version" SG_ 578 C_RRLumbarLowSw_HU "19.11.09";
BA_ "GenSigSendType" SG_ 578 C_RRLumbarDefSw_HU 4;
BA_ "UserSigValidity" SG_ 578 C_RRLumbarDefSw_HU 0;
BA_ "Version" SG_ 578 C_RRLumbarDefSw_HU "19.11.09";
BA_ "GenSigSendType" SG_ 578 C_RRBolsterInfSw_HU 4;
BA_ "UserSigValidity" SG_ 578 C_RRBolsterInfSw_HU 0;
BA_ "Version" SG_ 578 C_RRBolsterInfSw_HU "19.11.09";
BA_ "GenSigSendType" SG_ 578 C_RRLegSupUpSw_HU 4;
BA_ "UserSigValidity" SG_ 578 C_RRLegSupUpSw_HU 0;
BA_ "Version" SG_ 578 C_RRLegSupUpSw_HU "19.11.09";
BA_ "GenSigSendType" SG_ 578 C_RROneTchNValueSet 4;
BA_ "UserSigValidity" SG_ 578 C_RROneTchNValueSet 0;
BA_ "Version" SG_ 578 C_RROneTchNValueSet "19.11.09";
BA_ "GenSigSendType" SG_ 578 C_RLOneTchNValueSet 4;
BA_ "UserSigValidity" SG_ 578 C_RLOneTchNValueSet 0;
BA_ "Version" SG_ 578 C_RLOneTchNValueSet "19.11.09";
BA_ "GenSigSendType" SG_ 578 C_RRBolsterDefSw_HU 4;
BA_ "UserSigValidity" SG_ 578 C_RRBolsterDefSw_HU 0;
BA_ "Version" SG_ 578 C_RRBolsterDefSw_HU "19.11.09";
BA_ "GenSigSendType" SG_ 578 C_AstRlxTiltUpSw_HU 4;
BA_ "UserSigValidity" SG_ 578 C_AstRlxTiltUpSw_HU 0;
BA_ "Version" SG_ 578 C_AstRlxTiltUpSw_HU "19.12.02";
BA_ "GenSigSendType" SG_ 578 C_AstRlxTiltDnSw_HU 4;
BA_ "UserSigValidity" SG_ 578 C_AstRlxTiltDnSw_HU 0;
BA_ "Version" SG_ 578 C_AstRlxTiltDnSw_HU "19.12.02";
BA_ "GenSigSendType" SG_ 578 C_RLRSEUpSw_HU 4;
BA_ "UserSigValidity" SG_ 578 C_RLRSEUpSw_HU 0;
BA_ "Version" SG_ 578 C_RLRSEUpSw_HU "19.12.02";
BA_ "GenSigSendType" SG_ 578 C_RLRSEDnSw_HU 4;
BA_ "UserSigValidity" SG_ 578 C_RLRSEDnSw_HU 0;
BA_ "Version" SG_ 578 C_RLRSEDnSw_HU "19.12.02";
BA_ "GenSigSendType" SG_ 578 C_RRRSEUpSw_HU 4;
BA_ "UserSigValidity" SG_ 578 C_RRRSEUpSw_HU 0;
BA_ "Version" SG_ 578 C_RRRSEUpSw_HU "19.12.02";
BA_ "GenSigSendType" SG_ 578 C_RRLegSupDnSw_HU 4;
BA_ "UserSigValidity" SG_ 578 C_RRLegSupDnSw_HU 0;
BA_ "Version" SG_ 578 C_RRLegSupDnSw_HU "19.11.09";
BA_ "GenSigSendType" SG_ 578 C_RRRSEDnSw_HU 4;
BA_ "UserSigValidity" SG_ 578 C_RRRSEDnSw_HU 0;
BA_ "Version" SG_ 578 C_RRRSEDnSw_HU "19.12.02";
BA_ "GenSigSendType" SG_ 578 C_RRHrestUpSw_HU 4;
BA_ "UserSigValidity" SG_ 578 C_RRHrestUpSw_HU 0;
BA_ "Version" SG_ 578 C_RRHrestUpSw_HU "19.11.09";
BA_ "Description" SG_ 2424579841 DATC_Crc11Val "The data area for CRC calculation is based on the data length (DLC) of the message DB.

The CRC shall be calculated over the entire data block (excluding the CRC bytes) including the user data, alive counter and Data ID



- CRC Polynomial (0x1021) , Ini";
BA_ "GenSigSendType" SG_ 2424579841 DATC_Crc11Val 4;
BA_ "GenSigStartValue" SG_ 2424579841 DATC_Crc11Val 65535;
BA_ "UserSigValidity" SG_ 2424579841 DATC_Crc11Val 3;
BA_ "Version" SG_ 2424579841 DATC_Crc11Val "21.09.03";
BA_ "Description" SG_ 2424579841 DATC_AlvCnt11Val "For the first transmission request for a data element the counter shall be initialized with 0 and shall be incremented by 1 for every subsequent send request. 

When the counter reaches the maximum value(0xFF), then it shall restart with 0 for the next s";
BA_ "GenSigSendType" SG_ 2424579841 DATC_AlvCnt11Val 4;
BA_ "UserSigValidity" SG_ 2424579841 DATC_AlvCnt11Val 3;
BA_ "Version" SG_ 2424579841 DATC_AlvCnt11Val "21.09.03";
BA_ "Description" SG_ 2424579841 DATC_TnnlClimtUSMSta "Tunnel Mode USM State";
BA_ "GenSigSendType" SG_ 2424579841 DATC_TnnlClimtUSMSta 4;
BA_ "UserSigValidity" SG_ 2424579841 DATC_TnnlClimtUSMSta 7;
BA_ "Version" SG_ 2424579841 DATC_TnnlClimtUSMSta "17.11.00";
BA_ "Description" SG_ 2424579841 DATC_ProximitySnsrSta "HTR CONTROL light near button ON/OFF USM f/back signal";
BA_ "GenSigSendType" SG_ 2424579841 DATC_ProximitySnsrSta 4;
BA_ "UserSigValidity" SG_ 2424579841 DATC_ProximitySnsrSta 7;
BA_ "Version" SG_ 2424579841 DATC_ProximitySnsrSta "17.11.00";
BA_ "Description" SG_ 2424579841 DATC_TunnelFuncOff4AutoDfgReq "DATC Turn off Tunnel Function for ADS";
BA_ "GenSigSendType" SG_ 2424579841 DATC_TunnelFuncOff4AutoDfgReq 4;
BA_ "UserSigValidity" SG_ 2424579841 DATC_TunnelFuncOff4AutoDfgReq 7;
BA_ "Version" SG_ 2424579841 DATC_TunnelFuncOff4AutoDfgReq "17.11.00";
BA_ "Description" SG_ 2424579841 DATC_RrCtlLckSta "Rear Lock Status Informed  DATC  to AVN";
BA_ "GenSigSendType" SG_ 2424579841 DATC_RrCtlLckSta 4;
BA_ "UserSigValidity" SG_ 2424579841 DATC_RrCtlLckSta 7;
BA_ "Version" SG_ 2424579841 DATC_RrCtlLckSta "17.11.00";
BA_ "Description" SG_ 2424579841 DATC_DrvrStHtrUSMSta "If the 'Auto Comfort Control' function is applied separately to the Seat and Steering Wheel, 

this signal is used.";
BA_ "GenSigSendType" SG_ 2424579841 DATC_DrvrStHtrUSMSta 4;
BA_ "UserSigValidity" SG_ 2424579841 DATC_DrvrStHtrUSMSta 7;
BA_ "Version" SG_ 2424579841 DATC_DrvrStHtrUSMSta "17.11.00";
BA_ "Description" SG_ 2424579841 DATC_InDrctVntUSMSta "This signal indicate Indirect Vent USM State.";
BA_ "GenSigSendType" SG_ 2424579841 DATC_InDrctVntUSMSta 4;
BA_ "UserSigValidity" SG_ 2424579841 DATC_InDrctVntUSMSta 3;
BA_ "Version" SG_ 2424579841 DATC_InDrctVntUSMSta "18.05.00";
BA_ "Description" SG_ 2424579841 DATC_WshFldUSMSta "This signal indicate Washer Fulid USM State.";
BA_ "GenSigSendType" SG_ 2424579841 DATC_WshFldUSMSta 4;
BA_ "UserSigValidity" SG_ 2424579841 DATC_WshFldUSMSta 7;
BA_ "Version" SG_ 2424579841 DATC_WshFldUSMSta "18.06.00";
BA_ "Description" SG_ 2424579841 DATC_DfgLgcUSMSta "This signal indicates USM States of DefLogic

(DEF ÇØÁ¦º¹±Í ·ÎÁ÷ USM ¼³Á¤°ª ¼Û½Å ½ÅÈ£)";
BA_ "GenSigSendType" SG_ 2424579841 DATC_DfgLgcUSMSta 4;
BA_ "GenSigStartValue" SG_ 2424579841 DATC_DfgLgcUSMSta 3;
BA_ "UserSigValidity" SG_ 2424579841 DATC_DfgLgcUSMSta 3;
BA_ "Version" SG_ 2424579841 DATC_DfgLgcUSMSta "18.07.03";
BA_ "Description" SG_ 2424579841 DATC_AutoFrshUSMSta "This signal indicates USM States of Auto Fresh

(°á·Î¹æÁö ÇØÁ¦ º¹±Í USM ¼³Á¤ »óÅÂ ¼Û½Å ½ÅÈ£)";
BA_ "GenSigSendType" SG_ 2424579841 DATC_AutoFrshUSMSta 4;
BA_ "GenSigStartValue" SG_ 2424579841 DATC_AutoFrshUSMSta 3;
BA_ "UserSigValidity" SG_ 2424579841 DATC_AutoFrshUSMSta 3;
BA_ "Version" SG_ 2424579841 DATC_AutoFrshUSMSta "18.07.03";
BA_ "Description" SG_ 2424579841 DATC_HptIntnstySta "This signal indicate the Haptic Intensity of Touch Button in the Heater Control.";
BA_ "GenSigSendType" SG_ 2424579841 DATC_HptIntnstySta 4;
BA_ "UserSigValidity" SG_ 2424579841 DATC_HptIntnstySta 7;
BA_ "Version" SG_ 2424579841 DATC_HptIntnstySta "18.11.01";
BA_ "Description" SG_ 2424579841 DATC_ClmtPwrSum_W "accumulated energy consumption while driving(200ms)";
BA_ "GenSigSendType" SG_ 2424579841 DATC_ClmtPwrSum_W 4;
BA_ "UserSigValidity" SG_ 2424579841 DATC_ClmtPwrSum_W 4;
BA_ "Version" SG_ 2424579841 DATC_ClmtPwrSum_W "18.09.00";
BA_ "Description" SG_ 579 OHCL_Opt "This signal is OHCL(OverHead Console Lamp)  ECU Option state";
BA_ "GenSigSendType" SG_ 579 OHCL_Opt 4;
BA_ "TimeoutValue" SG_ 579 OHCL_Opt "Old Value";
BA_ "UserSigValidity" SG_ 579 OHCL_Opt 3;
BA_ "Version" SG_ 579 OHCL_Opt "19.12.01";
BA_ "Description" SG_ 579 OHCL_Sys_sta "This signal is OHCL (OverHead Console Lamp) system state";
BA_ "GenSigSendType" SG_ 579 OHCL_Sys_sta 4;
BA_ "TimeoutValue" SG_ 579 OHCL_Sys_sta "0x3";
BA_ "UserSigValidity" SG_ 579 OHCL_Sys_sta 3;
BA_ "Version" SG_ 579 OHCL_Sys_sta "19.12.01";
BA_ "Description" SG_ 579 OHCL_DoorOn_Sta "This signal is door lamp switch On/Off status";
BA_ "GenSigSendType" SG_ 579 OHCL_DoorOn_Sta 4;
BA_ "TimeoutValue" SG_ 579 OHCL_DoorOn_Sta "Old Value";
BA_ "UserSigValidity" SG_ 579 OHCL_DoorOn_Sta 3;
BA_ "Version" SG_ 579 OHCL_DoorOn_Sta "19.12.01";
BA_ "Description" SG_ 579 OHCL_RrMapLftOn_Sta "This signal is rear left map lamp On/Off status";
BA_ "GenSigSendType" SG_ 579 OHCL_RrMapLftOn_Sta 4;
BA_ "TimeoutValue" SG_ 579 OHCL_RrMapLftOn_Sta "Old Value";
BA_ "UserSigValidity" SG_ 579 OHCL_RrMapLftOn_Sta 3;
BA_ "Version" SG_ 579 OHCL_RrMapLftOn_Sta "19.12.01";
BA_ "Description" SG_ 579 OHCL_RrMapRtOn_Sta "This signal is rear right map lamp On/Off status";
BA_ "GenSigSendType" SG_ 579 OHCL_RrMapRtOn_Sta 4;
BA_ "TimeoutValue" SG_ 579 OHCL_RrMapRtOn_Sta "Old Value";
BA_ "UserSigValidity" SG_ 579 OHCL_RrMapRtOn_Sta 3;
BA_ "Version" SG_ 579 OHCL_RrMapRtOn_Sta "19.12.01";
BA_ "Description" SG_ 579 OHCL_RrRoomOn_Sta "This signal is rear room map lamp On/Off status ( all )";
BA_ "GenSigSendType" SG_ 579 OHCL_RrRoomOn_Sta 4;
BA_ "TimeoutValue" SG_ 579 OHCL_RrRoomOn_Sta "Old Value";
BA_ "UserSigValidity" SG_ 579 OHCL_RrRoomOn_Sta 3;
BA_ "Version" SG_ 579 OHCL_RrRoomOn_Sta "19.12.01";
BA_ "Description" SG_ 579 OHCL_RrMoodOn_Sta "This signal is rear mood map lamp On/Off status";
BA_ "GenSigSendType" SG_ 579 OHCL_RrMoodOn_Sta 4;
BA_ "TimeoutValue" SG_ 579 OHCL_RrMoodOn_Sta "Old Value";
BA_ "UserSigValidity" SG_ 579 OHCL_RrMoodOn_Sta 3;
BA_ "Version" SG_ 579 OHCL_RrMoodOn_Sta "19.12.01";
BA_ "Description" SG_ 579 OHCL_LEDClr_Sta "This signal is interior lamps lighting color status";
BA_ "GenSigSendType" SG_ 579 OHCL_LEDClr_Sta 4;
BA_ "TimeoutValue" SG_ 579 OHCL_LEDClr_Sta "Old Value";
BA_ "UserSigValidity" SG_ 579 OHCL_LEDClr_Sta 3;
BA_ "Version" SG_ 579 OHCL_LEDClr_Sta "19.12.01";
BA_ "Description" SG_ 579 OHCL_LEDBgtns_Sta "This signal is interior lamps brightness status";
BA_ "GenSigSendType" SG_ 579 OHCL_LEDBgtns_Sta 4;
BA_ "TimeoutValue" SG_ 579 OHCL_LEDBgtns_Sta "Old Value";
BA_ "UserSigValidity" SG_ 579 OHCL_LEDBgtns_Sta 3;
BA_ "Version" SG_ 579 OHCL_LEDBgtns_Sta "19.12.01";
BA_ "Description" SG_ 579 OHCL_TllTlLmpSta "This signal is PAB tell tale lamp status signal

( ACU_TllTlLmpDis feedback signal )";
BA_ "GenSigSendType" SG_ 579 OHCL_TllTlLmpSta 4;
BA_ "GenSigStartValue" SG_ 579 OHCL_TllTlLmpSta 3;
BA_ "UserSigValidity" SG_ 579 OHCL_TllTlLmpSta 3;
BA_ "Version" SG_ 579 OHCL_TllTlLmpSta "20.10.00";
BA_ "Description" SG_ 579 OHCL_FrMapLftOn_Sta "This signal is front left map lamp On/Off status";
BA_ "GenSigSendType" SG_ 579 OHCL_FrMapLftOn_Sta 4;
BA_ "TimeoutValue" SG_ 579 OHCL_FrMapLftOn_Sta "0x0";
BA_ "UserSigValidity" SG_ 579 OHCL_FrMapLftOn_Sta 3;
BA_ "Version" SG_ 579 OHCL_FrMapLftOn_Sta "19.12.01";
BA_ "Description" SG_ 579 OHCL_RrCurtainReq "This signal is Rear curtain switch On/Off signal

( The signal send 'On' during push switch only )";
BA_ "GenSigSendType" SG_ 579 OHCL_RrCurtainReq 4;
BA_ "UserSigValidity" SG_ 579 OHCL_RrCurtainReq 3;
BA_ "Version" SG_ 579 OHCL_RrCurtainReq "20.01.01";
BA_ "Description" SG_ 579 OHCL_FrMapRtOn_Sta "This signal is front right map lamp On/Off status";
BA_ "GenSigSendType" SG_ 579 OHCL_FrMapRtOn_Sta 4;
BA_ "TimeoutValue" SG_ 579 OHCL_FrMapRtOn_Sta "Old Value";
BA_ "UserSigValidity" SG_ 579 OHCL_FrMapRtOn_Sta 3;
BA_ "Version" SG_ 579 OHCL_FrMapRtOn_Sta "19.12.01";
BA_ "Description" SG_ 579 OHCL_FrRoomOn_Sta "This signal is front room lamp On/Off status ( all )";
BA_ "GenSigSendType" SG_ 579 OHCL_FrRoomOn_Sta 4;
BA_ "TimeoutValue" SG_ 579 OHCL_FrRoomOn_Sta "Old Value";
BA_ "UserSigValidity" SG_ 579 OHCL_FrRoomOn_Sta 3;
BA_ "Version" SG_ 579 OHCL_FrRoomOn_Sta "19.12.01";
BA_ "Description" SG_ 579 OHCL_FrMoodOn_Sta "This signal is front mood map lamp On/Off status";
BA_ "GenSigSendType" SG_ 579 OHCL_FrMoodOn_Sta 4;
BA_ "UserSigValidity" SG_ 579 OHCL_FrMoodOn_Sta 3;
BA_ "Version" SG_ 579 OHCL_FrMoodOn_Sta "19.12.01";
BA_ "Description" SG_ 1546 AMP_SupportBeepVolumeControl "18.02.01_";
BA_ "GenSigStartValue" SG_ 1546 AMP_SupportBeepVolumeControl 3;
BA_ "UserSigValidity" SG_ 1546 AMP_SupportBeepVolumeControl 1;
BA_ "Version" SG_ 1546 AMP_SupportBeepVolumeControl "18.12.06";
BA_ "Description" SG_ 1546 AMP_SupportESEVMode "Dose amp support CenterPoint mode?";
BA_ "GenSigStartValue" SG_ 1546 AMP_SupportESEVMode 3;
BA_ "UserSigValidity" SG_ 1546 AMP_SupportESEVMode 1;
BA_ "NetworkRequest" SG_ 1546 AMP_SupportESEVMode 0;
BA_ "Version" SG_ 1546 AMP_SupportESEVMode "20.03.06";
BA_ "Description" SG_ 1546 AMP_SupportDSC "18.04.00_Does amp support Dynamic Speed Compensation mode?";
BA_ "GenSigStartValue" SG_ 1546 AMP_SupportDSC 3;
BA_ "UserSigValidity" SG_ 1546 AMP_SupportDSC 1;
BA_ "Version" SG_ 1546 AMP_SupportDSC "18.12.06";
BA_ "Description" SG_ 1546 AMP_SupportANCMode "18.03.08_";
BA_ "GenSigStartValue" SG_ 1546 AMP_SupportANCMode 3;
BA_ "UserSigValidity" SG_ 1546 AMP_SupportANCMode 1;
BA_ "Version" SG_ 1546 AMP_SupportANCMode "18.12.06";
BA_ "GenSigStartValue" SG_ 1546 AMP_MakerID 255;
BA_ "UserSigValidity" SG_ 1546 AMP_MakerID 1;
BA_ "Version" SG_ 1546 AMP_MakerID "19.12.00";
BA_ "Description" SG_ 1546 AMP_SupportQLS "16.03.03_";
BA_ "GenSigStartValue" SG_ 1546 AMP_SupportQLS 3;
BA_ "UserSigValidity" SG_ 1546 AMP_SupportQLS 1;
BA_ "Version" SG_ 1546 AMP_SupportQLS "18.12.06";
BA_ "Description" SG_ 1546 AMP_SupportQLS_2step "Information for 2 Step QLS mode (Harman AMP only)";
BA_ "GenSigStartValue" SG_ 1546 AMP_SupportQLS_2step 3;
BA_ "UserSigValidity" SG_ 1546 AMP_SupportQLS_2step 1;
BA_ "Version" SG_ 1546 AMP_SupportQLS_2step "21.09.10";
BA_ "GenSigStartValue" SG_ 1546 AMP_SupportHorizon 3;
BA_ "UserSigValidity" SG_ 1546 AMP_SupportHorizon 1;
BA_ "NetworkRequest" SG_ 1546 AMP_SupportHorizon 0;
BA_ "Version" SG_ 1546 AMP_SupportHorizon "20.05.00";
BA_ "Description" SG_ 1546 AMP_SupportASDMode "16.03.03_";
BA_ "GenSigStartValue" SG_ 1546 AMP_SupportASDMode 3;
BA_ "UserSigValidity" SG_ 1546 AMP_SupportASDMode 1;
BA_ "Version" SG_ 1546 AMP_SupportASDMode "18.12.06";
BA_ "GenSigStartValue" SG_ 1546 AMP_SupportIntelliQ 3;
BA_ "UserSigValidity" SG_ 1546 AMP_SupportIntelliQ 1;
BA_ "NetworkRequest" SG_ 1546 AMP_SupportIntelliQ 0;
BA_ "Version" SG_ 1546 AMP_SupportIntelliQ "20.05.00";
BA_ "Description" SG_ 1546 AMP_SupportCenterpoint "18.04.00_Does amp support CenterPoint mode?";
BA_ "GenSigStartValue" SG_ 1546 AMP_SupportCenterpoint 3;
BA_ "UserSigValidity" SG_ 1546 AMP_SupportCenterpoint 1;
BA_ "Version" SG_ 1546 AMP_SupportCenterpoint "18.12.06";
BA_ "Description" SG_ 1546 AMP_SupportLiveDynamicMode "16.03.04_";
BA_ "GenSigStartValue" SG_ 1546 AMP_SupportLiveDynamicMode 7;
BA_ "UserSigValidity" SG_ 1546 AMP_SupportLiveDynamicMode 1;
BA_ "Version" SG_ 1546 AMP_SupportLiveDynamicMode "18.12.06";
BA_ "Description" SG_ 1546 AMP_Support_ElecSound "16.07.03_";
BA_ "GenSigStartValue" SG_ 1546 AMP_Support_ElecSound 3;
BA_ "UserSigValidity" SG_ 1546 AMP_Support_ElecSound 1;
BA_ "NetworkRequest" SG_ 1546 AMP_Support_ElecSound 0;
BA_ "Version" SG_ 1546 AMP_Support_ElecSound "18.12.06";
BA_REL_ "GenSigTimeoutTime" BU_SG_REL_ PSB SG_ 2244048385 RCU_HDP_EgSta 1500;
BA_REL_ "GenSigTimeoutTime" BU_SG_REL_ APSU SG_ 1616 MKBD_SeatKeySet 0;
BA_REL_ "GenSigTimeoutTime" BU_SG_REL_ SHVU_FR SG_ 1616 MKBD_SeatKeySet 0;
BA_REL_ "GenSigTimeoutTime" BU_SG_REL_ DPSU SG_ 1616 MKBD_SeatKeySet 0;
BA_REL_ "GenSigTimeoutTime" BU_SG_REL_ HOD SG_ 2273435649 HDP_SysSta 1500;
BA_REL_ "GenSigTimeoutTime" BU_SG_REL_ PSB SG_ 2273435650 HDP_HapticWarnReq 1500;
BA_REL_ "GenSigTimeoutTime" BU_SG_REL_ RWPC SG_ 2214658049 ENG_EngSta 1500;
BA_REL_ "GenSigTimeoutTime" BU_SG_REL_ PSB SG_ 1578 PSB_CCP_CRO_Byte0 0;
BA_REL_ "GenSigTimeoutTime" BU_SG_REL_ PSB SG_ 1578 PSB_CCP_CRO_Byte2 0;
BA_REL_ "GenSigTimeoutTime" BU_SG_REL_ PSB SG_ 1578 PSB_CCP_CRO_Byte3 0;
BA_REL_ "GenSigTimeoutTime" BU_SG_REL_ PSB SG_ 1578 PSB_CCP_CRO_Byte4 0;
BA_REL_ "GenSigTimeoutTime" BU_SG_REL_ PSB SG_ 1578 PSB_CCP_CRO_Byte5 0;
BA_REL_ "GenSigTimeoutTime" BU_SG_REL_ PSB SG_ 1578 PSB_CCP_CRO_Byte6 0;
BA_REL_ "GenSigTimeoutTime" BU_SG_REL_ PSB SG_ 1578 PSB_CCP_CRO_Byte7 0;
BA_REL_ "GenSigTimeoutTime" BU_SG_REL_ PSB SG_ 1578 PSB_CCP_CRO_Byte1 0;
BA_REL_ "GenSigTimeoutTime" BU_SG_REL_ CGW_CCU SG_ 1579 PSB_CCP_DTO_Byte0 0;
BA_REL_ "GenSigTimeoutTime" BU_SG_REL_ CGW_CCU SG_ 1579 PSB_CCP_DTO_Byte2 0;
BA_REL_ "GenSigTimeoutTime" BU_SG_REL_ CGW_CCU SG_ 1579 PSB_CCP_DTO_Byte3 0;
BA_REL_ "GenSigTimeoutTime" BU_SG_REL_ CGW_CCU SG_ 1579 PSB_CCP_DTO_Byte4 0;
BA_REL_ "GenSigTimeoutTime" BU_SG_REL_ CGW_CCU SG_ 1579 PSB_CCP_DTO_Byte5 0;
BA_REL_ "GenSigTimeoutTime" BU_SG_REL_ CGW_CCU SG_ 1579 PSB_CCP_DTO_Byte6 0;
BA_REL_ "GenSigTimeoutTime" BU_SG_REL_ CGW_CCU SG_ 1579 PSB_CCP_DTO_Byte7 0;
BA_REL_ "GenSigTimeoutTime" BU_SG_REL_ CGW_CCU SG_ 1579 PSB_CCP_DTO_Byte1 0;
BA_REL_ "GenSigTimeoutTime" BU_SG_REL_ RRHV SG_ 639 ATS_RRSeatHeaterSW 0;
BA_REL_ "GenSigTimeoutTime" BU_SG_REL_ SHVU_RR SG_ 639 ATS_RRSeatHeaterSW 0;
BA_REL_ "GenSigTimeoutTime" BU_SG_REL_ RLHV SG_ 639 ATS_RLSeatHeaterUpSW 0;
BA_REL_ "GenSigTimeoutTime" BU_SG_REL_ SHVU_RR SG_ 639 ATS_RLSeatHeaterUpSW 0;
BA_REL_ "GenSigTimeoutTime" BU_SG_REL_ RRHV SG_ 639 ATS_RRSeatVentDownSW 0;
BA_REL_ "GenSigTimeoutTime" BU_SG_REL_ SHVU_RR SG_ 639 ATS_RRSeatVentDownSW 0;
BA_REL_ "GenSigTimeoutTime" BU_SG_REL_ RLHV SG_ 639 ATS_RLSeatVentDownSW 0;
BA_REL_ "GenSigTimeoutTime" BU_SG_REL_ SHVU_RR SG_ 639 ATS_RLSeatVentDownSW 0;
BA_REL_ "GenSigTimeoutTime" BU_SG_REL_ RLHV SG_ 639 ATS_RLSeatHeaterSW 0;
BA_REL_ "GenSigTimeoutTime" BU_SG_REL_ SHVU_RR SG_ 639 ATS_RLSeatHeaterSW 0;
BA_REL_ "GenSigTimeoutTime" BU_SG_REL_ RRHV SG_ 639 ATS_RRSeatVentSW 0;
BA_REL_ "GenSigTimeoutTime" BU_SG_REL_ SHVU_RR SG_ 639 ATS_RRSeatVentSW 0;
BA_REL_ "GenSigTimeoutTime" BU_SG_REL_ RLHV SG_ 639 ATS_RLSeatVentSW 0;
BA_REL_ "GenSigTimeoutTime" BU_SG_REL_ SHVU_RR SG_ 639 ATS_RLSeatVentSW 0;
BA_REL_ "GenSigTimeoutTime" BU_SG_REL_ RRHV SG_ 639 ATS_RRSeatHeaterUpSW 0;
BA_REL_ "GenSigTimeoutTime" BU_SG_REL_ SHVU_RR SG_ 639 ATS_RRSeatHeaterUpSW 0;
BA_REL_ "GenSigTimeoutTime" BU_SG_REL_ ATS SG_ 1584 AMP_Beep1Mode 0;
BA_REL_ "GenSigTimeoutTime" BU_SG_REL_ ASAU SG_ 577 C_AstBolsterInfSw_HU 1500;
BA_REL_ "GenSigTimeoutTime" BU_SG_REL_ ALBCU SG_ 577 C_AstBolsterInfSw_HU 1500;
BA_REL_ "GenSigTimeoutTime" BU_SG_REL_ APSU SG_ 577 C_RLHrestUpSw_HU 1500;
BA_REL_ "GenSigTimeoutTime" BU_SG_REL_ RLPSU SG_ 577 C_RLHrestUpSw_HU 1500;
BA_REL_ "GenSigTimeoutTime" BU_SG_REL_ APSU SG_ 577 C_RLHrestDnSw_HU 1500;
BA_REL_ "GenSigTimeoutTime" BU_SG_REL_ RLPSU SG_ 577 C_RLHrestDnSw_HU 1500;
BA_REL_ "GenSigTimeoutTime" BU_SG_REL_ APSU SG_ 577 C_RLHrestFwdSw_HU 1500;
BA_REL_ "GenSigTimeoutTime" BU_SG_REL_ RLPSU SG_ 577 C_RLHrestFwdSw_HU 1500;
BA_REL_ "GenSigTimeoutTime" BU_SG_REL_ ASAU SG_ 577 C_AstBolsterDefSw_HU 1500;
BA_REL_ "GenSigTimeoutTime" BU_SG_REL_ ALBCU SG_ 577 C_AstBolsterDefSw_HU 1500;
BA_REL_ "GenSigTimeoutTime" BU_SG_REL_ APSU SG_ 577 C_RLHrestBwdSw_HU 1500;
BA_REL_ "GenSigTimeoutTime" BU_SG_REL_ RLPSU SG_ 577 C_RLHrestBwdSw_HU 1500;
BA_REL_ "GenSigTimeoutTime" BU_SG_REL_ RLPSU SG_ 577 C_RLLumbarUpSw_HU 1500;
BA_REL_ "GenSigTimeoutTime" BU_SG_REL_ RLPSU SG_ 577 C_RLLumbarMidSw_HU 1500;
BA_REL_ "GenSigTimeoutTime" BU_SG_REL_ RLPSU SG_ 577 C_RLLumbarLowSw_HU 1500;
BA_REL_ "GenSigTimeoutTime" BU_SG_REL_ RLPSU SG_ 577 C_RLLumbarDefSw_HU 1500;
BA_REL_ "GenSigTimeoutTime" BU_SG_REL_ RLPSU SG_ 577 C_RLBolsterInfSw_HU 1500;
BA_REL_ "GenSigTimeoutTime" BU_SG_REL_ RLPSU SG_ 577 C_RLBolsterDefSw_HU 1500;
BA_REL_ "GenSigTimeoutTime" BU_SG_REL_ APSU SG_ 577 C_AstHrestUpSw_HU 1500;
BA_REL_ "GenSigTimeoutTime" BU_SG_REL_ APSU SG_ 577 C_AstHrestDnSw_HU 1500;
BA_REL_ "GenSigTimeoutTime" BU_SG_REL_ APSU SG_ 577 C_AstFootrestFldSw_HU 1500;
BA_REL_ "GenSigTimeoutTime" BU_SG_REL_ APSU SG_ 577 C_AstHrestFwdSw_HU 1500;
BA_REL_ "GenSigTimeoutTime" BU_SG_REL_ APSU SG_ 577 C_AstHrestBwdSw_HU 1500;
BA_REL_ "GenSigTimeoutTime" BU_SG_REL_ APSU SG_ 577 C_AstFootrestUnFldSw_HU 1500;
BA_REL_ "GenSigTimeoutTime" BU_SG_REL_ APSU SG_ 578 C_RRLegSupFwdSw_HU 1500;
BA_REL_ "GenSigTimeoutTime" BU_SG_REL_ RRPSU SG_ 578 C_RRLegSupFwdSw_HU 1500;
BA_REL_ "GenSigTimeoutTime" BU_SG_REL_ APSU SG_ 578 C_RRHrestDnSw_HU 1500;
BA_REL_ "GenSigTimeoutTime" BU_SG_REL_ RRPSU SG_ 578 C_RRHrestDnSw_HU 1500;
BA_REL_ "GenSigTimeoutTime" BU_SG_REL_ APSU SG_ 578 C_RRHrestFwdSw_HU 1500;
BA_REL_ "GenSigTimeoutTime" BU_SG_REL_ RRPSU SG_ 578 C_RRHrestFwdSw_HU 1500;
BA_REL_ "GenSigTimeoutTime" BU_SG_REL_ APSU SG_ 578 C_RRHrestBwdSw_HU 1500;
BA_REL_ "GenSigTimeoutTime" BU_SG_REL_ RRPSU SG_ 578 C_RRHrestBwdSw_HU 1500;
BA_REL_ "GenSigTimeoutTime" BU_SG_REL_ APSU SG_ 578 C_RRLumbarUpSw_HU 1500;
BA_REL_ "GenSigTimeoutTime" BU_SG_REL_ RRPSU SG_ 578 C_RRLumbarUpSw_HU 1500;
BA_REL_ "GenSigTimeoutTime" BU_SG_REL_ APSU SG_ 578 C_RRLumbarMidSw_HU 1500;
BA_REL_ "GenSigTimeoutTime" BU_SG_REL_ RRPSU SG_ 578 C_RRLumbarMidSw_HU 1500;
BA_REL_ "GenSigTimeoutTime" BU_SG_REL_ APSU SG_ 578 C_RRLegSupBwdSw_HU 1500;
BA_REL_ "GenSigTimeoutTime" BU_SG_REL_ RRPSU SG_ 578 C_RRLegSupBwdSw_HU 1500;
BA_REL_ "GenSigTimeoutTime" BU_SG_REL_ APSU SG_ 578 C_RRLumbarLowSw_HU 1500;
BA_REL_ "GenSigTimeoutTime" BU_SG_REL_ RRPSU SG_ 578 C_RRLumbarLowSw_HU 1500;
BA_REL_ "GenSigTimeoutTime" BU_SG_REL_ APSU SG_ 578 C_RRLumbarDefSw_HU 1500;
BA_REL_ "GenSigTimeoutTime" BU_SG_REL_ RRPSU SG_ 578 C_RRLumbarDefSw_HU 1500;
BA_REL_ "GenSigTimeoutTime" BU_SG_REL_ APSU SG_ 578 C_RRBolsterInfSw_HU 1500;
BA_REL_ "GenSigTimeoutTime" BU_SG_REL_ RRPSU SG_ 578 C_RRBolsterInfSw_HU 1500;
BA_REL_ "GenSigTimeoutTime" BU_SG_REL_ APSU SG_ 578 C_RRLegSupUpSw_HU 1500;
BA_REL_ "GenSigTimeoutTime" BU_SG_REL_ RRPSU SG_ 578 C_RRLegSupUpSw_HU 1500;
BA_REL_ "GenSigTimeoutTime" BU_SG_REL_ APSU SG_ 578 C_RROneTchNValueSet 1500;
BA_REL_ "GenSigTimeoutTime" BU_SG_REL_ RRPSU SG_ 578 C_RROneTchNValueSet 1500;
BA_REL_ "GenSigTimeoutTime" BU_SG_REL_ ATS SG_ 578 C_RROneTchNValueSet 1500;
BA_REL_ "GenSigTimeoutTime" BU_SG_REL_ APSU SG_ 578 C_RLOneTchNValueSet 1500;
BA_REL_ "GenSigTimeoutTime" BU_SG_REL_ RRPSU SG_ 578 C_RLOneTchNValueSet 1500;
BA_REL_ "GenSigTimeoutTime" BU_SG_REL_ RLPSU SG_ 578 C_RLOneTchNValueSet 1500;
BA_REL_ "GenSigTimeoutTime" BU_SG_REL_ ATS SG_ 578 C_RLOneTchNValueSet 1500;
BA_REL_ "GenSigTimeoutTime" BU_SG_REL_ APSU SG_ 578 C_RRBolsterDefSw_HU 1500;
BA_REL_ "GenSigTimeoutTime" BU_SG_REL_ RRPSU SG_ 578 C_RRBolsterDefSw_HU 1500;
BA_REL_ "GenSigTimeoutTime" BU_SG_REL_ APSU SG_ 578 C_AstRlxTiltUpSw_HU 1500;
BA_REL_ "GenSigTimeoutTime" BU_SG_REL_ APSU SG_ 578 C_AstRlxTiltDnSw_HU 1500;
BA_REL_ "GenSigTimeoutTime" BU_SG_REL_ APSU SG_ 578 C_RLRSEUpSw_HU 1500;
BA_REL_ "GenSigTimeoutTime" BU_SG_REL_ RLPSU SG_ 578 C_RLRSEUpSw_HU 1500;
BA_REL_ "GenSigTimeoutTime" BU_SG_REL_ APSU SG_ 578 C_RLRSEDnSw_HU 1500;
BA_REL_ "GenSigTimeoutTime" BU_SG_REL_ RLPSU SG_ 578 C_RLRSEDnSw_HU 1500;
BA_REL_ "GenSigTimeoutTime" BU_SG_REL_ APSU SG_ 578 C_RRRSEUpSw_HU 1500;
BA_REL_ "GenSigTimeoutTime" BU_SG_REL_ RRPSU SG_ 578 C_RRRSEUpSw_HU 1500;
BA_REL_ "GenSigTimeoutTime" BU_SG_REL_ APSU SG_ 578 C_RRLegSupDnSw_HU 1500;
BA_REL_ "GenSigTimeoutTime" BU_SG_REL_ RRPSU SG_ 578 C_RRLegSupDnSw_HU 1500;
BA_REL_ "GenSigTimeoutTime" BU_SG_REL_ APSU SG_ 578 C_RRRSEDnSw_HU 1500;
BA_REL_ "GenSigTimeoutTime" BU_SG_REL_ RRPSU SG_ 578 C_RRRSEDnSw_HU 1500;
BA_REL_ "GenSigTimeoutTime" BU_SG_REL_ APSU SG_ 578 C_RRHrestUpSw_HU 1500;
BA_REL_ "GenSigTimeoutTime" BU_SG_REL_ RRPSU SG_ 578 C_RRHrestUpSw_HU 1500;
BA_REL_ "GenSigTimeoutTime" BU_SG_REL_ ATS SG_ 2424579841 DATC_RrCtlLckSta 1500;
BA_REL_ "GenSigTimeoutTime" BU_SG_REL_ APSU SG_ 2424579841 DATC_DrvrStHtrUSMSta 1500;
BA_REL_ "GenSigTimeoutTime" BU_SG_REL_ DPSU SG_ 2424579841 DATC_DrvrStHtrUSMSta 1500;
BA_REL_ "GenSigTimeoutTime" BU_SG_REL_ ATS SG_ 579 OHCL_Opt 1000;
BA_REL_ "GenSigTimeoutTime" BU_SG_REL_ ATS SG_ 579 OHCL_Sys_sta 1000;
BA_REL_ "GenSigTimeoutTime" BU_SG_REL_ ATS SG_ 579 OHCL_DoorOn_Sta 1000;
BA_REL_ "GenSigTimeoutTime" BU_SG_REL_ ATS SG_ 579 OHCL_RrMapLftOn_Sta 1000;
BA_REL_ "GenSigTimeoutTime" BU_SG_REL_ ATS SG_ 579 OHCL_RrMapRtOn_Sta 1000;
BA_REL_ "GenSigTimeoutTime" BU_SG_REL_ ATS SG_ 579 OHCL_RrRoomOn_Sta 1000;
BA_REL_ "GenSigTimeoutTime" BU_SG_REL_ ATS SG_ 579 OHCL_RrMoodOn_Sta 1000;
BA_REL_ "GenSigTimeoutTime" BU_SG_REL_ ATS SG_ 579 OHCL_LEDClr_Sta 1000;
BA_REL_ "GenSigTimeoutTime" BU_SG_REL_ ATS SG_ 579 OHCL_LEDBgtns_Sta 1000;
BA_REL_ "GenSigTimeoutTime" BU_SG_REL_ CGW_CCU SG_ 579 OHCL_TllTlLmpSta 1000;
BA_REL_ "GenSigTimeoutTime" BU_SG_REL_ ATS SG_ 579 OHCL_FrMapLftOn_Sta 1000;
BA_REL_ "GenSigTimeoutTime" BU_SG_REL_ ATS SG_ 579 OHCL_FrMapRtOn_Sta 1000;
BA_REL_ "GenSigTimeoutTime" BU_SG_REL_ ATS SG_ 579 OHCL_FrRoomOn_Sta 1000;
BA_REL_ "GenSigTimeoutTime" BU_SG_REL_ ATS SG_ 579 OHCL_FrMoodOn_Sta 1000;
BA_REL_ "GenSigTimeoutTime" BU_SG_REL_ ATS SG_ 1546 AMP_SupportBeepVolumeControl 1500;
VAL_ 2244048387 RCU_AD3_TCS_TqFlag 0 "Positive" 1 "Negative" ;
VAL_ 2244048387 RCU_AD3_TCS_Sta 0 "Not Applied" 1 "Off" 2 "Ready" 3 "Activated" 4 "Reserved" 5 "Reserved" 6 "Reserved" 7 "Reserved" 8 "Reserved" 9 "Reserved" 10 "Reserved" 11 "Reserved" 12 "Reserved" 13 "Reserved" 14 "Not Coded" 15 "Defective" ;
VAL_ 2244048387 RCU_AD3_VehAccelVal 2047 "Error" ;
VAL_ 2244048387 RCU_AD3_MSR_TqFlag 0 "Positive" 1 "Negative" ;
VAL_ 2244048387 RCU_AD3_LDM_Sta 0 "RCU ready to DBFAVH (requested by switch)" 1 "RCU can¡¯t perform DBFAVH (requested by switch)" 2 "Not used" 3 "Error Indicator" ;
VAL_ 2244048387 RCU_AD3_ECD_ActvSta 0 "RCU ECD is not active" 1 "RCU ECD is active(operating)" 2 "Not used" 3 "Error Indicator" ;
VAL_ 2244048387 RCU_AD3_MSR_FuncReq 0 "Passive or RCU TCS function" 1 "RCU MSR control active" 2 "Not used" 3 "Error Indicator" ;
VAL_ 2244048387 RCU_AD3_TCS_Req 0 "Passive" 1 "RCU_TCS/ESC control active" 2 "Not used" 3 "Error Indicator" ;
VAL_ 2244048387 RCU_AD3_TCS_LmpSta 0 "RCU_TCSESC FunctionWarning Lamp OFF" 1 "RCU_TCSESC FunctionWarning Lamp ON" 2 "RCU_TCSESC FunctionWarning Lamp BLINKING(2Hz)" 3 "Error Indicator" ;
VAL_ 2244048387 RCU_AD3_SCC_TqReq 0 "No request" 1 "Enable SCC torque request" 2 "Not used" 3 "Error Indicator" ;
VAL_ 2244048387 RCU_AD3_StdStillVal 0 "No stand still detected" 1 "stand still detected" 2 "Not used" 3 "Error Indicator" ;
VAL_ 2244048387 RCU_AD3_SCC_ReqLimSta 0 "No request" 1 "Limited No Limitation" 2 "Acceleration Limited" 3 "Deceleration Limited" ;
VAL_ 2244048387 RCU_AD3_SCC_OptTyp 0 "RCU_SCC is not equipped" 1 "RCU_SCC is equipped" 2 "Not used" 3 "Not Coded" ;
VAL_ 2244048387 RCU_AD3_SCC_EnblReq 0 "RCU_SCC enabled" 1 "RCU_SCC disabled reversible" 2 "RCU_SCC disabled irreversible" 3 "RCU_SCC disabled irreversible due to communication error" ;
VAL_ 2244048387 RCU_AD3_FCA_EquipSta 0 "RCU_FCA is not equipped" 1 "RCU_FCA is equipped" 2 "Not used" 3 "Not Coded" ;
VAL_ 2244048387 RCU_AD3_FCA_ActvSta 0 "RCU_FCA Brake is not in activation" 1 "RCU_FCA Pre-Brake" 2 "RCU_FCA Full-Brake" 3 "Invalid" ;
VAL_ 2244048387 RCU_AD3_DclEnblReq 0 "Disable deceleration control" 1 "Enable deceleration control" 2 "Not used" 3 "Error Indicator" ;
VAL_ 2244048387 RCU_AD3_DBS_ActvSta 0 "RCU_DBS control is inactive" 1 "RCU_DBS control is active" 2 "Not used" 3 "Not used" ;
VAL_ 2244048387 RCU_AD3_AccelBasisVal 2047 "Error" ;
VAL_ 2244048386 RCU_AD3_Wss2FlFltSta 0 "No Fault" 1 "Fault" 2 "Not used" 3 "Error Indicator" ;
VAL_ 2244048386 RCU_AD3_DiagSta 0 "RCU is not diagnostic mode" 1 "RCU is diagnostic mode" 2 "Not used" 3 "Error Indicator" ;
VAL_ 2244048386 RCU_AD3_PrsrValVldSta 0 "Normal" 1 "Fail" 2 "RESERVED" 3 "Suspect" ;
VAL_ 2244048386 RCU_AD3_PrsrVal 4095 "Error" ;
VAL_ 2244048386 RCU_AD3_Wss2FrFltSta 0 "No Fault" 1 "Fault" 2 "Not used" 3 "Error Indicator" ;
VAL_ 2244048386 RCU_AD3_ABS_DfctvSta 0 "RCU ABS function is not defective" 1 "RCU ABS function is defective" 2 "Not used" 3 "Error Indicator" ;
VAL_ 2244048386 RCU_AD3_ABS_ActvSta 0 "RCU ABS control inactive" 1 "RCU ABS control active" 2 "Not used" 3 "Error Indicator" ;
VAL_ 2244048386 RCU_AD3_BBC_DfctvSta 0 "RCU BBC function is not defective" 1 "RCU BBC function is defective" 2 "Not used" 3 "Error Indicator" ;
VAL_ 2244048386 RCU_AD3_BBC_ActvSta 0 "RCU BBC control inactive" 1 "RCU BBC control active" 2 "Not used" 3 "Error Indicator" ;
VAL_ 2244048386 RCU_AD3_Wss2RlFltSta 0 "No Fault" 1 "Fault" 2 "Not used" 3 "Error Indicator" ;
VAL_ 2244048386 RCU_AD3_BrkLtActSta 0 "No request" 1 "RCU Activate brake lights" 2 "Not used" 3 "Error Indicator" ;
VAL_ 2244048386 RCU_AD3_DrvOvrdSta 0 "No override" 1 "Override by acceleration pedal" 2 "Override by deceleration" 3 "Error Indicator" ;
VAL_ 2244048386 RCU_AD3_PrkBrkActvSta 0 "RCU Parking brake is not activated" 1 "RCU Parking brake is activated" 2 "Not used" 3 "Error Indicator" ;
VAL_ 2244048386 RCU_AD3_FCA_AvlblSta 0 "Available" 1 "Temporarily not available" 2 "Permanently not available" 3 "FCA Communication Error" ;
VAL_ 2244048386 RCU_AD3_Wss2RrFltSta 0 "No Fault" 1 "Fault" 2 "Not used" 3 "Error Indicator" ;
VAL_ 2244048386 RCU_AD3_SrvLmpDis 0 "RCU Service Lamp is Off" 1 "RCU Service Lamp is On" 2 "RCU Service Lamp is BLINKING(2HZ)" 3 "error indicator" ;
VAL_ 2244048385 RCU_Crc3Val 0 "0x0x0~0xFFFF:CRCValue" 65535 "0x0x0~0xFFFF:CRCValue" ;
VAL_ 2244048385 RCU_AlvCnt3Val 0 "0x0x0~0xFF:AlvCntValue" 255 "0x0x0~0xFF:AlvCntValue" ;
VAL_ 2244048385 RCU_HDP_FltMonSta 0 "No Fault" 1 "Main Controller Fault Detected (ADAS_DRV 2)" 2 "Sub Controller Fault Detected (FR_CMR)" 3 "Main & Sub Controller Fault Detected (ADAS_DRV 2 & FR_CMR)" 4 "Reserved" 5 "Reserved" 6 "Reserved" 7 "Reserved" ;
VAL_ 2244048385 RCU_HDP_EgSta 0 "Not Engaged" 1 "Engaged in main controller by IEB (ESC)" 2 "Engaged in sub controller by IEB (ESC)" 3 "MRM with IEB (ESC) alone" 4 "Engaged in main controller by RCU" 5 "Engaged in sub controller by RCU" 6 "MRM with RCU alone" 7 "Engaged in sub controller by IEB (ESC), but RCU Signal" ;
VAL_ 2244048385 RCU_HDP_EnblReq 0 "No Fault" 1 "Req. longitudinal control normal, Functional Fault" 2 "Req. longitudinal control normal, Partial performance degradation" 3 "Req. longitudinal control abnormal, Brake control possible" 4 "Req. longitudinal control abnormal, Brake control impossible" 5 "Req. longitudinal control normal, Acceleration control Fault (eg. Engine Fault)" 6 "HDP disabled reversible" 7 "Reserved" ;
VAL_ 2244048385 RCU_AD3_AWD_FastOpnCrdnShftCltch 0 "Passive" 1 "Clutch off" 2 "Torque limit" 3 "Error" ;
VAL_ 2244048385 RCU_AD3_PdlTrvlSnsrValVldSta 0 "Normal" 1 "Fail" 2 "Compare error" 3 "Suspect" ;
VAL_ 2244048385 RCU_AD3_PdlCalibSta 0 "Not complete" 1 "Complete" 2 "Not used" 3 "Not used" ;
VAL_ 2244048385 RCU_AD3_WSSmode 0 "Not support" 1 "RCU support mode" ;
VAL_ 527 ATS_DrvStRseFwdBtn 0 "Default" 1 "Off" 2 "On" 3 "Reserved" ;
VAL_ 527 ATS_DrvStRseBwdBtn 0 "Default" 1 "Off" 2 "On" 3 "Reserved" ;
VAL_ 527 ATS_RRRestModBtn 0 "Default" 1 "Off" 2 "On" 3 "Reserved" ;
VAL_ 527 ATS_RRResetModBtn 0 "Default" 1 "Off" 2 "On" 3 "Reserved" ;
VAL_ 527 ATS_RRAvWtcModBtn 0 "Default" 1 "Off" 2 "On" 3 "Reserved" ;
VAL_ 527 ATS_RRReadingModBtn 0 "Default" 1 "Off" 2 "On" 3 "Reserved" ;
VAL_ 527 ATS_RLRestModBtn 0 "Default" 1 "Off" 2 "On" 3 "Reserved" ;
VAL_ 527 ATS_RLResetModBtn 0 "Default" 1 "Off" 2 "On" 3 "Reserved" ;
VAL_ 2244048388 RCU_HDPSpprtSWVer 0 "Not Supported" 1 "SW Version" 2 "SW Version" 3 "SW Version" 4 "SW Version" 5 "SW Version" 6 "SW Version" 7 "SW Version" 8 "SW Version" 9 "SW Version" 10 "SW Version" 11 "SW Version" 12 "SW Version" 13 "SW Version" 14 "SW Version" 15 "SW Version" 16 "SW Version" 17 "SW Version" 18 "SW Version" 19 "SW Version" 20 "SW Version" 21 "SW Version" 22 "SW Version" 23 "SW Version" 24 "SW Version" 25 "SW Version" 26 "SW Version" 27 "SW Version" 28 "SW Version" 29 "SW Version" 30 "SW Version" 31 "SW Version" ;
VAL_ 2244048388 RCU_AD3_ABS_WrngLmpSta 0 "RCU ABS Warning lamp OFF" 1 "RCU ABS Warning lamp ON" 2 "RESERVED" 3 "Error Indicator" ;
VAL_ 2244048388 RCU_AD3_ESC_Sta 0 "Not Applied" 1 "Off" 2 "Ready" 3 "Activated" 4 "RESERVED" 5 "RESERVED" 6 "RESERVED" 7 "RESERVED" 8 "RESERVED" 9 "RESERVED" 10 "RESERVED" 11 "RESERVED" 12 "RESERVED" 13 "RESERVED" 14 "Not Coded" 15 "Defective" ;
VAL_ 1616 MKBD_IllumiState 0 "Not received" 1 "Receive Completed" 2 "Reserved" 3 "Invalid" ;
VAL_ 1616 MKBD_SeatKeySet 0 "Off" 1 "On" 2 "Reserved" 3 "Invalid" ;
VAL_ 543 ATS_AstStSldFwdBtn 0 "Default" 1 "Off" 2 "On" 3 "Reserved" ;
VAL_ 543 ATS_AstStSldBwdBtn 0 "Default" 1 "Off" 2 "On" 3 "Reserved" ;
VAL_ 543 ATS_AstStRclFwdBtn 0 "Default" 1 "Off" 2 "On" 3 "Reserved" ;
VAL_ 543 ATS_AstStRclBwdBtn 0 "Default" 1 "Off" 2 "On" 3 "Reserved" ;
VAL_ 543 ATS_AstStHgtUpBtn 0 "Default" 1 "Off" 2 "On" 3 "Reserved" ;
VAL_ 543 ATS_AstStHgtDnBtn 0 "Default" 1 "Off" 2 "On" 3 "Reserved" ;
VAL_ 543 ATS_AstStHRestUpBtn 0 "Default" 1 "Off" 2 "On" 3 "Reserved" ;
VAL_ 543 ATS_AstStHRestDnBtn 0 "Default" 1 "Off" 2 "On" 3 "Reserved" ;
VAL_ 543 ATS_AstStHRestFwdBtn 0 "Default" 1 "Off" 2 "On" 3 "Reserved" ;
VAL_ 543 ATS_AstStHRestBwdBtn 0 "Default" 1 "Off" 2 "On" 3 "Reserved" ;
VAL_ 543 ATS_AstStHRestFldBtn 0 "Default" 1 "Off" 2 "On" 3 "Reserved" ;
VAL_ 543 ATS_AstStHRestUnFldBtn 0 "Default" 1 "Off" 2 "On" 3 "Reserved" ;
VAL_ 543 ATS_AstStRseFwdBtn 0 "Default" 1 "Off" 2 "On" 3 "Reserved" ;
VAL_ 543 ATS_AstStRseBwdBtn 0 "Default" 1 "Off" 2 "On" 3 "Reserved" ;
VAL_ 543 ATS_AstStFRestFldBtn 0 "Default" 1 "Off" 2 "On" 3 "Reserved" ;
VAL_ 543 ATS_AstStFRestUnFldBtn 0 "Default" 1 "Off" 2 "On" 3 "Reserved" ;
VAL_ 543 ATS_AstTltUpBtn 0 "Default" 1 "Off" 2 "On" 3 "Reserved" ;
VAL_ 543 ATS_AstTltDnBtn 0 "Default" 1 "Off" 2 "On" 3 "Reserved" ;
VAL_ 2214658052 ENG_DclBrkCntrlReq 4095 "Error indicator" ;
VAL_ 2214658052 ENG_BstPrsrVal 4095 "Error indicator" ;
VAL_ 2214658052 ENG_EngOilTempVal 255 "Error indicator" ;
VAL_ 2214658052 ENG_DpfWrngSta 0 "DPF Normal State" 1 "DPF Warning State Level 1" 2 "DPF Warning State Level 2" 3 "Reserved" ;
VAL_ 2214658052 ENG_BattWrngLmpSta 0 "Battery Warning Lamp OFF" 1 "Battery Warning Lamp ON" 2 "Not used" 3 "Error indicator" ;
VAL_ 2214658052 ENG_OilPrsrWrngLmpSta 0 "Oil Pressure Warning Lamp OFF" 1 "Oil Pressure Warning Lamp ON" 2 "Not used" 3 "Error indicator" ;
VAL_ 2214658052 ENG_IsgInhbtLmpSta 0 "ISG Inhibit Lamp OFF" 1 "ISG Inhibit Lamp ON" 2 "Not used" 3 "Error indicator" ;
VAL_ 2273435649 ADAS_CMD_Crc31Val 0 "0x0x0~0xFFFF:CRCValue" 65535 "0x0x0~0xFFFF:CRCValue" ;
VAL_ 2273435649 ADAS_CMD_AlvCnt31Val 0 "0x0x0~0xFF:AlvCntValue" 255 "0x0x0~0xFF:AlvCntValue" ;
VAL_ 2273435649 HDA_OptUsmSta 0 "Not Applied" 1 "Function Off" 2 "Function On" 3 "Reserved" 4 "Reserved" 5 "Reserved" 6 "Reserved" 7 "Invalid (Fail)" ;
VAL_ 2273435649 HDA_CntrlModSta 0 "System OFF (Default)" 1 "System STANDBY" 2 "System ACTIVE" 3 "Reserved" ;
VAL_ 2273435649 HDA_InfoPUDis 0 "No pop-up" 1 "system start pop-up" 2 "system auto disengaged pop-up by highway off" 3 "System Fail pop up (LFA)" 4 "System Fail pop up (HDA)" 5 "Hands-off pop up" 6 "Hands-off pop up w/sound" 7 "RESERVED" ;
VAL_ 2273435649 HDP_AutoCallReqSta 0 "No request" 1 "HDP MRM Auto Call Request" 2 "Reserved" 3 "Reserved" 4 "Reserved" 5 "Reserved" 6 "Cancel the HDP Auto Call" 7 "Invalid" ;
VAL_ 2273435649 HDP_DispBarSta 0 "Not Display" 1 "Amber Blinking" 2 "RESERVED" 3 "Amber Display" 4 "Red Display" 5 "RESERVED" 6 "RESERVED" 7 "RESERVED" 8 "RESERVED" 9 "RESERVED" 10 "RESERVED" 11 "RESERVED" 12 "RESERVED" 13 "RESERVED" 14 "RESERVED" 15 "RESERVED" ;
VAL_ 2273435649 HDP_OptInfoSta 0 "HDP option not applied" 1 "HDP option applied" 2 "RESERVED" 3 "RESERVED" ;
VAL_ 2273435649 HDA_LFA_SymSta 0 "Off" 1 "Gray" 2 "Green" 3 "White blink" ;
VAL_ 2273435649 HDA_LFA_WrnSnd 0 "Off" 1 "Additional Warning Sound" 2 "Reserved" 3 "Error indicator" ;
VAL_ 2273435649 HDA_InfoPUDis1 0 "No Pop-up" 1 "System Automatic off (LFA)" 2 "System Automatic off (HDA)" 3 "Reserved" 4 "Reserved" 5 "Reserved" 6 "Not Used" 7 "Error Indicator" ;
VAL_ 2273435649 HDA_TDMRMDclReq 0 "Not automatically deactivated state of LFA (default)" 1 "Automatically deactivated state of LFA" 2 "Reserved" 3 "Reserved" ;
VAL_ 2273435649 HDP_ActvSta 0 "Not Active" 1 "Active" 2 "Reserved" 3 "Reserved" ;
VAL_ 2273435649 HDP_SysSta 0 "OFF" 1 "Standby" 2 "DDT" 3 "TD" 4 "MRM" 5 "EM" 6 "Reserved" 15 "Reserved" ;
VAL_ 2273435649 HDP_FailureMode 0 "Normal" 1 "Blockage" 2 "Failure" ;
VAL_ 2273435650 HDP_ObstacleDstVal 0 "0x0x0~0x5DC:Distance" 1500 "0x0x0~0x5DC:Distance" 1501 "0x5DD~0x7FD:Reserved" 2045 "0x5DD~0x7FD:Reserved" 2046 "Default" 2047 "Error" ;
VAL_ 2273435650 HDP_ObstacleLatPosVal 0 "0x0x0~0x1FD:Position Value" 509 "0x0x0~0x1FD:Position Value" 510 "Default" 511 "Error" ;
VAL_ 2273435650 HDP_InfoPUDis 0 "None" 1 "HDP Active" 2 "HDP TD Lv1" 3 "HDP TD Lv2" 4 "HDP MRM" 5 "HDP EM" 6 "HDP Automatic system off" 7 "HDP Driver availability warning" 8 "Unable to start HDP" 9 "HDP guides user to change lane" 10 "HDP off by the driver" 11 "RESERVED" 12 "RESERVED" 13 "RESERVED" 14 "RESERVED" 15 "RESERVED" ;
VAL_ 2273435650 HDP_WrngTypPUDis 0 "Reserved" 1 "Reserved" 2 "Reserved" 3 "Reserved" 4 "Reserved" 5 "Reserved" 6 "Reserved" 7 "Reserved" 8 "Reserved" 9 "Reserved" 10 "Reserved" 11 "Reserved" 12 "Reserved" 13 "Reserved" 14 "Reserved" 15 "Reserved" 16 "Reserved" 17 "Reserved" 18 "Reserved" 19 "Reserved" 20 "Reserved" 21 "Reserved" 22 "Reserved" 23 "Reserved" 24 "Reserved" 25 "Reserved" 26 "Reserved" 27 "Reserved" 28 "Reserved" 29 "Reserved" 30 "Reserved" 31 "Reserved" ;
VAL_ 2273435650 HDP_HapticWarnReq 0 "No Warn" 1 "Request Haptic Warn - Level1" 2 "Request Haptic Warn - Level2" 3 "Invalid" ;
VAL_ 2273435650 HDP_ActvStaDis 0 "Not Active" 1 "Active" 2 "RESERVED" 3 "RESERVED" 4 "RESERVED" 5 "RESERVED" 6 "RESERVED" 7 "Invalid" ;
VAL_ 2273435650 HDP_OpStaDisp 0 "None" 1 "Standby" 2 "Ready" 3 "Active(DDT)" 4 "Active(TD)" 5 "Active(MRM)" 6 "Active(EM)" 7 "RESERVED" 8 "RESERVED" 9 "RESERVED" 10 "RESERVED" 11 "RESERVED" 12 "RESERVED" 13 "RESERVED" 14 "RESERVED" 15 "Invalid" ;
VAL_ 2273435650 HDP_ObstSta 0 "No in-path obstacle detected" 1 "In-path obstacle detected (uncontrollable)" 2 "In-path obstacle detected (controllable:longitudinal)" 3 "Reserved" 4 "Reserved" 5 "Reserved" 6 "Reserved" 7 "Reserved" ;
VAL_ 2273435650 HDP_SysFlrDisp 0 "No HDP failure pop-up" 1 "HDP failure pop-up" 2 "HDP Camera blockage" 3 "HDP Radar blockage" 4 "HDP Lidar blockage" 5 "RESERVED" 6 "RESERVED" 7 "RESERVED" ;
VAL_ 2273435650 HDP_InhbtOffDispSta 0 "None" 1 "Inhibit change while HDP (H/Unit)" 2 "RESERVED" 3 "RESERVED" 4 "RESERVED" 5 "RESERVED" 6 "RESERVED" 7 "RESERVED" ;
VAL_ 2273435650 HDP_CtRoadSrfcDistVal 0 "0x0x0~0x5DC:Real Values" 1500 "0x0x0~0x5DC:Real Values" 1501 "0x5DD~0x7FD:RESERVED" 2045 "0x5DD~0x7FD:RESERVED" 2046 "Default (Not Display)" 2047 "Invalid" ;
VAL_ 2273435650 ADAS_DRV_UpDateInfo 0 "old" 1 "new" ;
VAL_ 2214658049 EMS_Crc2Val 0 "0x0x0~0xFFFF:CRCValue" 65535 "0x0x0~0xFFFF:CRCValue" ;
VAL_ 2214658049 EMS_AlvCnt2Val 0 "0x0x0~0xFF:AlvCntValue" 255 "0x0x0~0xFF:AlvCntValue" ;
VAL_ 2214658049 ENG_BrkSwSta 0 "Brake switch is not pressed (OFF)" 1 "Brake switch is pressed (ON)" 2 "EMS does not support this function." 3 "Brake switch failure" ;
VAL_ 2214658049 ENG_EngClntTempVal 255 "Error indicator" ;
VAL_ 2214658049 ENG_MafCrctVal 128 "Error indicator" ;
VAL_ 2214658049 ENG_BattDscnctSta 0 "no battery disconnection detected" 1 "battery disconnection detected and failure memory erased" 2 "Not used" 3 "Error indicator" ;
VAL_ 2214658049 OBD_MilConfgVal 0 "no MIL, Failure Memory Management OBD-I" 1 "MIL Treatment OBD-I, Failure Memory Management OBD-I" 2 "MIL Treatment OBD-II, Exception" 3 "MIL Treatment OBD-II, Failure Memory Management OBD-II" 4 "MIL Treatment E-OBD, Failure Memory Management E-OBD" 5 "MIL Treatment K-OBD, Failure Memory Management K-OBD" ;
VAL_ 2214658049 ENG_EngSta 0 "Engine Stop" 1 "Cranking" 2 "Stalled" 3 "Running" 4 "Reserved" 5 "Reserved" 6 "Reserved" 7 "Fault" ;
VAL_ 614 EMCU_Crc1Val 0 "0x0x0~0xFF:CRCValue" 255 "0x0x0~0xFF:CRCValue" ;
VAL_ 614 EMCU_AlvCnt1Val 0 "AlvCntValue" 1 "AlvCntValue" 2 "AlvCntValue" 3 "AlvCntValue" 4 "AlvCntValue" 5 "AlvCntValue" 6 "AlvCntValue" 7 "AlvCntValue" 8 "AlvCntValue" 9 "AlvCntValue" 10 "AlvCntValue" 11 "AlvCntValue" 12 "AlvCntValue" 13 "AlvCntValue" 14 "AlvCntValue" 15 "AlvCntValue" ;
VAL_ 614 EMCU_LHActSta 0 "OFF" 1 "ON" 2 "RESERVED" 3 "Error indicator" ;
VAL_ 614 EMCU_RHActSta 0 "OFF" 1 "ON" 2 "RESERVED" 3 "Error indicator" ;
VAL_ 614 EMCU_DeltaSpdVal 0 "0x0x000~0xFFE:real values" 4094 "0x0x000~0xFFE:real values" 4095 "Error indicator" ;
VAL_ 614 EMCU_System_Sta 0 "Normal" 1 "RESERVED" 2 "RESERVED" 3 "Error indicator" ;
VAL_ 2214658051 ENG_AppAccelPdlSta 0 "Accelerator pedal not pressed" 1 "Accelerator pedal pressed" 2 "Reserved" 3 "Accelerator pedal position sensor failure" ;
VAL_ 2214658051 ENG_BrkCtrlReq 0 "Brake control request is not active" 1 "Brake control request is active" 2 "Not used" 3 "Error indicator" ;
VAL_ 2214658051 ACC_DnShftCtrlReq 0 "Downshift control request is not active" 1 "Downshift request to 1st gear" 2 "Downshift request to 2nd gear" 3 "Downshift request to 3rd gear" 4 "Downshift request to 4th gear" 5 "Downshift request to 5th gear" 6 "Downshift request to 6th gear" 7 "Downshift request to 7th gear" 8 "Downshift request to 8th gear" 9 "Reserved" 10 "Reserved" 11 "Reserved" 12 "Reserved" 13 "Reserved" 14 "Reserved" 15 "Error indicator" ;
VAL_ 2214658050 ENG_Ack4EngStpSta 0 "No acknowledgement" 1 "Acknowledgement engine stopped" 2 "Not used" 3 "Error indicator" ;
VAL_ 2214658050 ENG_AccDrvAlertDisp 0 "Default" 1 "Auto cruise Disengaged" 2 "No Auto cruise Engaged" 3 "Error indicator" ;
VAL_ 2214658050 DSL_GlowCtrlReq 0 "Glow plug off request" 1 "Glow plug on request" 2 "System Error" 3 "Reserved" ;
VAL_ 2214658050 ENG_GlowLmpSta 0 "Lamp Off" 1 "Lamp On" 2 "Not used" 3 "Error indicator" ;
VAL_ 2214658050 ENG_ThrPosVal 32 "Idle (port value is learnt)" 245 "Throttle perpendicular" 255 "Throttle defective" ;
VAL_ 2214658050 ENG_OverDrvOffReq 0 "Normal operation" 1 "Over drive off request to TCU by the cruise control function" 2 "Not used" 3 "Error indicator" ;
VAL_ 2214658050 ENG_AccelPdlVal 0 "Accelerator Pedal not activated" 1022 "Accelerator Pedal fully activated" 1023 "Accelerator Pedal is defective (fail state) or Non-ETC system (APS is not installed), Error indicator" ;
VAL_ 2214658050 ENG_AccActSta 0 "Auto cruise control is not active" 1 "Auto cruise control is active" 2 "Not used" 3 "Error indicator" ;
VAL_ 2214658050 ACC_CrsMainSwLmpSta 0 "Cruise MAIN switch indication lamp turn OFF" 1 "Cruise MAIN switch indication lamp turn ON" 2 "Not used" 3 "Error indicator" ;
VAL_ 2214658050 ACC_CrsSetSwLmpSta 0 "Cruise SET switch indication lamp turn OFF" 1 "Cruise SET switch indication lamp turn ON" 2 "Not used" 3 "Error indicator" ;
VAL_ 2214658050 ENG_LV_FUP_ENA_THD 0 "The pressure is too low to start engine" 1 "The pressure is enough high to start engine" ;
VAL_ 2214658050 ENG_SoakTimeErrSta 0 "No Failure detected" 1 "Failure detected" 2 "Not used" 3 "Error indicator" ;
VAL_ 2214658050 ENG_CltchOpSta 0 "Clutch is not operating" 1 "Clutch is operating" 2 "Not used" 3 "Error indicator" ;
VAL_ 2214658050 EMS_BrkReq_Slope 0 "No Request" 1 "Brake Request" ;
VAL_ 623 ATS_ARSOpenCloseStatus 0 "Default" 1 "Open" 2 "Close" 3 "Invalid" ;
VAL_ 623 ATS_RLLumbarDefBtn 0 "Default" 1 "Off" 2 "On" 3 "Reserved" ;
VAL_ 623 ATS_RLLumbarLowBtn 0 "Default" 1 "Off" 2 "On" 3 "Reserved" ;
VAL_ 623 ATS_RLLumbarMidBtn 0 "Default" 1 "Off" 2 "On" 3 "Reserved" ;
VAL_ 623 ATS_RLLumbarUpBtn 0 "Default" 1 "Off" 2 "On" 3 "Reserved" ;
VAL_ 623 ATS_RLBolsterDefBtn 0 "Default" 1 "Off" 2 "On" 3 "Reserved" ;
VAL_ 623 ATS_RLBolsterInfSw 0 "Default" 1 "Off" 2 "On" 3 "Reserved" ;
VAL_ 623 ATS_RRLumbarDefBtn 0 "Default" 1 "Off" 2 "On" 3 "Reserved" ;
VAL_ 623 ATS_RRLumbarLowBtn 0 "Default" 1 "Off" 2 "On" 3 "Reserved" ;
VAL_ 623 ATS_RRLumbarMidBtn 0 "Default" 1 "Off" 2 "On" 3 "Reserved" ;
VAL_ 623 ATS_RRLumbarUpBtn 0 "Default" 1 "Off" 2 "On" 3 "Reserved" ;
VAL_ 623 ATS_RRBolsterDefBtn 0 "Default" 1 "Off" 2 "On" 3 "Reserved" ;
VAL_ 623 ATS_RRBolsterInfSw 0 "Default" 1 "Off" 2 "On" 3 "Reserved" ;
VAL_ 639 ATS_RRSeatHeaterSW 0 "Default" 1 "Short On" 2 "Long On" 3 "Invalid" ;
VAL_ 639 ATS_RLSeatHeaterUpSW 0 "Default" 1 "Short On" 2 "Long On" 3 "Invalid" ;
VAL_ 639 ATS_RRSeatVentDownSW 0 "Default" 1 "Short On" 2 "Long On" 3 "Invalid" ;
VAL_ 639 ATS_RLSeatVentDownSW 0 "Default" 1 "Short On" 2 "Long On" 3 "Invalid" ;
VAL_ 639 ATS_RLMemoryRestBtn 0 "Default" 1 "Off" 2 "On" 3 "Invalid" ;
VAL_ 639 ATS_RLMemoryReturnBtn 0 "Default" 1 "Off" 2 "On" 3 "Invalid" ;
VAL_ 639 ATS_RLSeatHeaterSW 0 "Default" 1 "Short On" 2 "Long On" 3 "Invalid" ;
VAL_ 639 ATS_RRMemoryRestBtn 0 "Default" 1 "Off" 2 "On" 3 "Invalid" ;
VAL_ 639 ATS_RRMemoryReturnBtn 0 "Default" 1 "Off" 2 "On" 3 "Invalid" ;
VAL_ 639 ATS_RRMemoryAvWtcBtn 0 "Default" 1 "Off" 2 "On" 3 "Invalid" ;
VAL_ 639 ATS_RRMemoryReadingBtn 0 "Default" 1 "Off" 2 "On" 3 "Invalid" ;
VAL_ 639 ATS_RRRestModBtnSTD 0 "Default" 1 "Off" 2 "On" 3 "Invalid" ;
VAL_ 639 ATS_RRResetModBtnSTD 0 "Default" 1 "Off" 2 "On" 3 "Invalid" ;
VAL_ 639 ATS_RRAvWtcModBtnSTD 0 "Default" 1 "Off" 2 "On" 3 "Invalid" ;
VAL_ 639 ATS_RRReadingModBtnSTD 0 "Default" 1 "Off" 2 "On" 3 "Invalid" ;
VAL_ 639 ATS_RRSeatVentSW 0 "Default" 1 "Short On" 2 "Long On" 3 "Invalid" ;
VAL_ 639 ATS_RLRestModBtnSTD 0 "Default" 1 "Off" 2 "On" 3 "Invalid" ;
VAL_ 639 ATS_RLResetModBtnSTD 0 "Default" 1 "Off" 2 "On" 3 "Invalid" ;
VAL_ 639 ATS_RRModestateStopBtn 0 "Default" 1 "Off" 2 "On" 3 "Invalid" ;
VAL_ 639 ATS_RLModestateStopBtn 0 "Default" 1 "Off" 2 "On" 3 "Invalid" ;
VAL_ 639 ATS_RLResetRestBtn 0 "Default" 1 "Off" 2 "On" 3 "Invalid" ;
VAL_ 639 ATS_RLResetReturnBtn 0 "Default" 1 "Off" 2 "On" 3 "Invalid" ;
VAL_ 639 ATS_RRResetRestBtn 0 "Default" 1 "Off" 2 "On" 3 "Invalid" ;
VAL_ 639 ATS_RRResetReturnBtn 0 "Default" 1 "Off" 2 "On" 3 "Invalid" ;
VAL_ 639 ATS_RRResetAvWtcBtn 0 "Default" 1 "Off" 2 "On" 3 "Invalid" ;
VAL_ 639 ATS_RRResetReadingBtn 0 "Default" 1 "Off" 2 "On" 3 "Invalid" ;
VAL_ 639 ATS_RLSeatVentSW 0 "Default" 1 "Short On" 2 "Long On" 3 "Invalid" ;
VAL_ 639 ATS_RRSeatHeaterUpSW 0 "Default" 1 "Short On" 2 "Long On" 3 "Invalid" ;
VAL_ 1584 AMP_NaviWarnSound 0 "Navi Warning Off" 1 "Navi Warning On" 2 "Unused" 3 "Invalid" ;
VAL_ 1584 AMP_Beep1Mode 0 "Beep1 mode off" 1 "Beep1 mode On" 2 "Unsed" 3 "Invalid" ;
VAL_ 1584 AMP_MasterBeepVolumeStep 0 "level 0" 1 "level 1" 2 "level 2" 3 "level 3" 4 "level 4" 5 "level 5" 6 "Reserved" 7 "Invalid" ;
VAL_ 1584 AMP_RrTTSSound 0 "RrTTS Off" 1 "RrTTS ON" 2 "Unused" 3 "Invalid" ;
VAL_ 1584 AMP_ASDMode 0 "Not use" 1 "ASD OFF" 2 "Reserved" 3 "ASD ON" 4 "Reserved" 5 "Reserved" 6 "Reserved" 7 "Invalid" ;
VAL_ 1584 AMP_ANCMode 0 "Not used" 1 "ANC Off" 2 "ANC On" 3 "Invalid" ;
VAL_ 1584 AMP_VirtualVenueMode 0 "Off" 1 "Livingroom" 2 "ConcertHall" 3 "Stadium" 4 "Reserved" 5 "Reserved" 6 "Reserved" 7 "Invalid" ;
VAL_ 1584 AMP_QLIMode 0 "Off" 1 "Reference" 2 "Audience" 3 "OnStage" 4 "Reserved" 5 "Reserved" 6 "Reserved" 7 "Invalid" ;
VAL_ 1584 AMP_DriverMode 0 "Off" 1 "On" 2 "Reserved" 3 "Invalid" ;
VAL_ 1584 AMP_NaviSound 0 "Navi Off" 1 "Navi ON" 2 "Unused" 3 "Invalid" ;
VAL_ 1584 AMP_ETCSSound 0 "ETCS Sound Off" 1 "ETCS Sound On" 2 "Unused" 3 "Invalid" ;
VAL_ 1584 AMP_VoiceGuideTTS 0 "Off" 1 "On" 2 "Reserved" 3 "Invalid" ;
VAL_ 1584 AMP_Beep1KBDMode 0 "Beep1 mode off" 1 "Beep1 mode On" 2 "Unsed" 3 "Invalid" ;
VAL_ 1584 AMP_ETCSVolumeStep 0 "0x0x0~0xFD:ETCS Volume" 253 "0x0x0~0xFD:ETCS Volume" 254 "Req. Amp supported ETCS Set" 255 "Invalid" ;
VAL_ 1584 AMP_NaviWarnVolumeStep 0 "0x0x0~0xFD:Navi Warning Volume" 253 "0x0x0~0xFD:Navi Warning Volume" 254 "Req. amp supported Navi Set" 255 "Invalid" ;
VAL_ 1584 AMP_TTSSound 0 "TTS Off" 1 "TTS ON" 2 "Unused" 3 "Invalid" ;
VAL_ 1584 AMP_SDVCStep 0 "off" 1 "low" 2 "mid" 3 "high" 7 "Invalid" ;
VAL_ 577 C_AstBolsterInfSw_HU 0 "Default" 1 "Off" 2 "On" 3 "Invalid" ;
VAL_ 577 C_RLHrestUpSw_HU 0 "Default" 1 "Off" 2 "On" 3 "Invalid" ;
VAL_ 577 C_RLHrestDnSw_HU 0 "Default" 1 "Off" 2 "On" 3 "Invalid" ;
VAL_ 577 C_RLHrestFwdSw_HU 0 "Default" 1 "Off" 2 "On" 3 "Invalid" ;
VAL_ 577 C_AstBolsterDefSw_HU 0 "Default" 1 "Off" 2 "On" 3 "Invalid" ;
VAL_ 577 C_RLHrestBwdSw_HU 0 "Default" 1 "Off" 2 "On" 3 "Invalid" ;
VAL_ 577 C_RLLumbarUpSw_HU 0 "Default" 1 "Off" 2 "On" 3 "Invalid" ;
VAL_ 577 C_RLLumbarMidSw_HU 0 "Default" 1 "Off" 2 "On" 3 "Invalid" ;
VAL_ 577 C_RLLumbarLowSw_HU 0 "Default" 1 "Off" 2 "On" 3 "Invalid" ;
VAL_ 577 C_RLLumbarDefSw_HU 0 "Default" 1 "Off" 2 "On" 3 "Invalid" ;
VAL_ 577 C_RLBolsterInfSw_HU 0 "Default" 1 "Off" 2 "On" 3 "Invalid" ;
VAL_ 577 C_RLBolsterDefSw_HU 0 "Default" 1 "Off" 2 "On" 3 "Invalid" ;
VAL_ 577 C_AstHrestUpSw_HU 0 "Default" 1 "Off" 2 "On" 3 "Invalid" ;
VAL_ 577 C_AstHrestDnSw_HU 0 "Default" 1 "Off" 2 "On" 3 "Invalid" ;
VAL_ 577 C_AstFootrestFldSw_HU 0 "Default" 1 "Off" 2 "On" 3 "Invalid" ;
VAL_ 577 C_AstHrestFwdSw_HU 0 "Default" 1 "Off" 2 "On" 3 "Invalid" ;
VAL_ 577 C_AstHrestBwdSw_HU 0 "Default" 1 "Off" 2 "On" 3 "Invalid" ;
VAL_ 577 C_AstFootrestUnFldSw_HU 0 "Default" 1 "Off" 2 "On" 3 "Invalid" ;
VAL_ 578 C_RRLegSupFwdSw_HU 0 "Default" 1 "Off" 2 "On" 3 "Invalid" ;
VAL_ 578 C_RRHrestDnSw_HU 0 "Default" 1 "Off" 2 "On" 3 "Invalid" ;
VAL_ 578 C_RRHrestFwdSw_HU 0 "Default" 1 "Off" 2 "On" 3 "Invalid" ;
VAL_ 578 C_RRHrestBwdSw_HU 0 "Default" 1 "Off" 2 "On" 3 "Invalid" ;
VAL_ 578 C_RRLumbarUpSw_HU 0 "Default" 1 "Off" 2 "On" 3 "Invalid" ;
VAL_ 578 C_RRLumbarMidSw_HU 0 "Default" 1 "Off" 2 "On" 3 "Invalid" ;
VAL_ 578 C_RRLegSupBwdSw_HU 0 "Default" 1 "Off" 2 "On" 3 "Invalid" ;
VAL_ 578 C_RRLumbarLowSw_HU 0 "Default" 1 "Off" 2 "On" 3 "Invalid" ;
VAL_ 578 C_RRLumbarDefSw_HU 0 "Default" 1 "Off" 2 "On" 3 "Invalid" ;
VAL_ 578 C_RRBolsterInfSw_HU 0 "Default" 1 "Off" 2 "On" 3 "Invalid" ;
VAL_ 578 C_RRLegSupUpSw_HU 0 "Default" 1 "Off" 2 "On" 3 "Invalid" ;
VAL_ 578 C_RROneTchNValueSet 0 "Default" 1 "Off" 2 "Return" 3 "Relax" 4 "AV" 5 "Read" 6 "Reserved" 7 "Invalid" ;
VAL_ 578 C_RLOneTchNValueSet 0 "Default" 1 "Off" 2 "Return" 3 "Relax" 4 "Reserved" 5 "Reserved" 6 "Reserved" 7 "Invalid" ;
VAL_ 578 C_RRBolsterDefSw_HU 0 "Default" 1 "Off" 2 "On" 3 "Invalid" ;
VAL_ 578 C_AstRlxTiltUpSw_HU 0 "Default" 1 "Off" 2 "On" 3 "Invalid" ;
VAL_ 578 C_AstRlxTiltDnSw_HU 0 "Default" 1 "Off" 2 "On" 3 "Invalid" ;
VAL_ 578 C_RLRSEUpSw_HU 0 "Default" 1 "Off" 2 "On" 3 "Invalid" ;
VAL_ 578 C_RLRSEDnSw_HU 0 "Default" 1 "Off" 2 "On" 3 "Invalid" ;
VAL_ 578 C_RRRSEUpSw_HU 0 "Default" 1 "Off" 2 "On" 3 "Invalid" ;
VAL_ 578 C_RRLegSupDnSw_HU 0 "Default" 1 "Off" 2 "On" 3 "Invalid" ;
VAL_ 578 C_RRRSEDnSw_HU 0 "Default" 1 "Off" 2 "On" 3 "Invalid" ;
VAL_ 578 C_RRHrestUpSw_HU 0 "Default" 1 "Off" 2 "On" 3 "Invalid" ;
VAL_ 2424579841 DATC_Crc11Val 0 "0x0x0~0xFFFF:CRCValue" 65535 "0x0x0~0xFFFF:CRCValue" ;
VAL_ 2424579841 DATC_AlvCnt11Val 0 "0x0x0~0xFF:AlvCntValue" 255 "0x0x0~0xFF:AlvCntValue" ;
VAL_ 2424579841 DATC_TnnlClimtUSMSta 0 "Default" 1 "OFF" 2 "ON" 3 "Error Indicator" ;
VAL_ 2424579841 DATC_ProximitySnsrSta 0 "Default(Not Apply)" 1 "OFF" 2 "ON" 3 "Error Indicator" ;
VAL_ 2424579841 DATC_TunnelFuncOff4AutoDfgReq 0 "Default" 1 "Tunnel Turn off" 2 "Not Used" 3 "Error Indicator" ;
VAL_ 2424579841 DATC_RrCtlLckSta 0 "Default" 1 "Rear Lock OFF" 2 "Rear Lock ON" 3 "Error Indicator" ;
VAL_ 2424579841 DATC_DrvrStHtrUSMSta 0 "NOT APPLY" 1 "OFF" 2 "ON" 3 "Error Indicator" ;
VAL_ 2424579841 DATC_InDrctVntUSMSta 0 "Default" 1 "InDirectVent USM OFF" 2 "InDirectVent USM ON" 3 "Invalid" ;
VAL_ 2424579841 DATC_WshFldUSMSta 0 "Default" 1 "OFF" 2 "ON" 3 "Invalid" ;
VAL_ 2424579841 DATC_DfgLgcUSMSta 0 "Default" 1 "OFF" 2 "ON" 3 "Invalid" ;
VAL_ 2424579841 DATC_AutoFrshUSMSta 0 "Default" 1 "OFF" 2 "ON" 3 "Invalid" ;
VAL_ 2424579841 DATC_HptIntnstySta 0 "Default" 1 "Haptic OFF" 2 "Haptic Intensity Level 1" 3 "Haptic Intensity Level 2" 4 "Haptic Intensity Level 3" 5 "Haptic Intensity Level 4" 6 "Haptic Intensity Level 5" 7 "Reserved" 8 "Reserved" 9 "Reserved" 10 "Reserved" 11 "Reserved" 12 "Reserved" 13 "Reserved" 14 "Reserved" 15 "Invalid" ;
VAL_ 579 OHCL_Opt 0 "None option" 1 "Enable" ;
VAL_ 579 OHCL_Sys_sta 0 "Normal" 1 "Not Used" 2 "Not Used" 3 "System Fail" ;
VAL_ 579 OHCL_DoorOn_Sta 0 "Off" 1 "On" 2 "Not Used" 3 "System Fail" ;
VAL_ 579 OHCL_RrMapLftOn_Sta 0 "Off" 1 "On" 2 "Not Used" 3 "System Fail" ;
VAL_ 579 OHCL_RrMapRtOn_Sta 0 "Off" 1 "On" 2 "Not Used" 3 "System Fail" ;
VAL_ 579 OHCL_RrRoomOn_Sta 0 "Off" 1 "On" 2 "Not Used" 3 "System Fail" ;
VAL_ 579 OHCL_RrMoodOn_Sta 0 "Off" 1 "On" 2 "Not Used" 3 "System Fail" ;
VAL_ 579 OHCL_LEDClr_Sta 0 "Color 1Step" 1 "Color 2Step" 2 "Color 3Step" 3 "Not Used" 4 "Not Used" 5 "Not Used" 6 "Not Used" 7 "System Fail" ;
VAL_ 579 OHCL_LEDBgtns_Sta 0 "Brightness 1Step" 1 "Brightness 2Step" 2 "Brightness 3Step" 3 "Not Used" 4 "Not Used" 5 "Not Used" 6 "Not Used" 7 "System Fail" ;
VAL_ 579 OHCL_TllTlLmpSta 0 "ON Lamp off OFF Lamp off" 1 "ON Lamp off OFF Lamp on" 2 "ON Lamp on OFF Lamp off" 3 "ON Lamp on OFF Lamp on" 4 "ACU message error" 5 "Not Supported" 6 "Reserved" 7 "Lamp circuit failure" ;
VAL_ 579 OHCL_FrMapLftOn_Sta 0 "Off" 1 "On" 2 "Not Used" 3 "System Fail" ;
VAL_ 579 OHCL_RrCurtainReq 0 "Off" 1 "On" 2 "NotUsed" 3 "ErrorIndicator" ;
VAL_ 579 OHCL_FrMapRtOn_Sta 0 "Off" 1 "On" 2 "Not Used" 3 "System Fail" ;
VAL_ 579 OHCL_FrRoomOn_Sta 0 "Off" 1 "On" 2 "Not Used" 3 "System Fail" ;
VAL_ 579 OHCL_FrMoodOn_Sta 0 "Off" 1 "On" 2 "Not Used" 3 "System Fail" ;
VAL_ 1546 AMP_SupportBeepVolumeControl 0 "Null" 1 "False" 2 "True" 3 "Invalid" ;
VAL_ 1546 AMP_SupportESEVMode 0 "Null" 1 "False" 2 "True" 3 "Invalid" ;
VAL_ 1546 AMP_SupportDSC 0 "Null" 1 "False" 2 "True" 3 "Invalid" ;
VAL_ 1546 AMP_SupportANCMode 0 "Null" 1 "False" 2 "True" 3 "Invalid" ;
VAL_ 1546 AMP_MakerID 0 "Initial Value" 1 "Mobis" 2 "Beats by Dr.Dre" 3 "Harman_Becker" 4 "BOSE" 5 "Bang&Olufsen" 6 "Meridian" 7 "0x07~0xFF:Invalid" 255 "0x07~0xFF:Invalid" ;
VAL_ 1546 AMP_SupportQLS 0 "Null" 1 "False" 2 "True" 3 "Invalid" ;
VAL_ 1546 AMP_SupportQLS_2step 0 "Null" 1 "False" 2 "True" 3 "Invalid" ;
VAL_ 1546 AMP_SupportHorizon 0 "Null" 1 "False" 2 "True" 3 "Invalid" ;
VAL_ 1546 AMP_SupportASDMode 0 "Null" 1 "False" 2 "True" 3 "Invalid" ;
VAL_ 1546 AMP_SupportIntelliQ 0 "Null" 1 "False" 2 "True" 3 "Invalid" ;
VAL_ 1546 AMP_SupportCenterpoint 0 "Null" 1 "False" 2 "True" 3 "Invalid" ;
VAL_ 1546 AMP_SupportLiveDynamicMode 0 "Null" 1 "False" 2 "True(Off On)" 3 "True(Off Natural Concert)" 4 "Reserved" 5 "Reserved" 6 "Reserved" 7 "Invalid" ;
VAL_ 1546 AMP_Support_ElecSound 0 "Null" 1 "False" 2 "True" 3 "Invalid" ;
